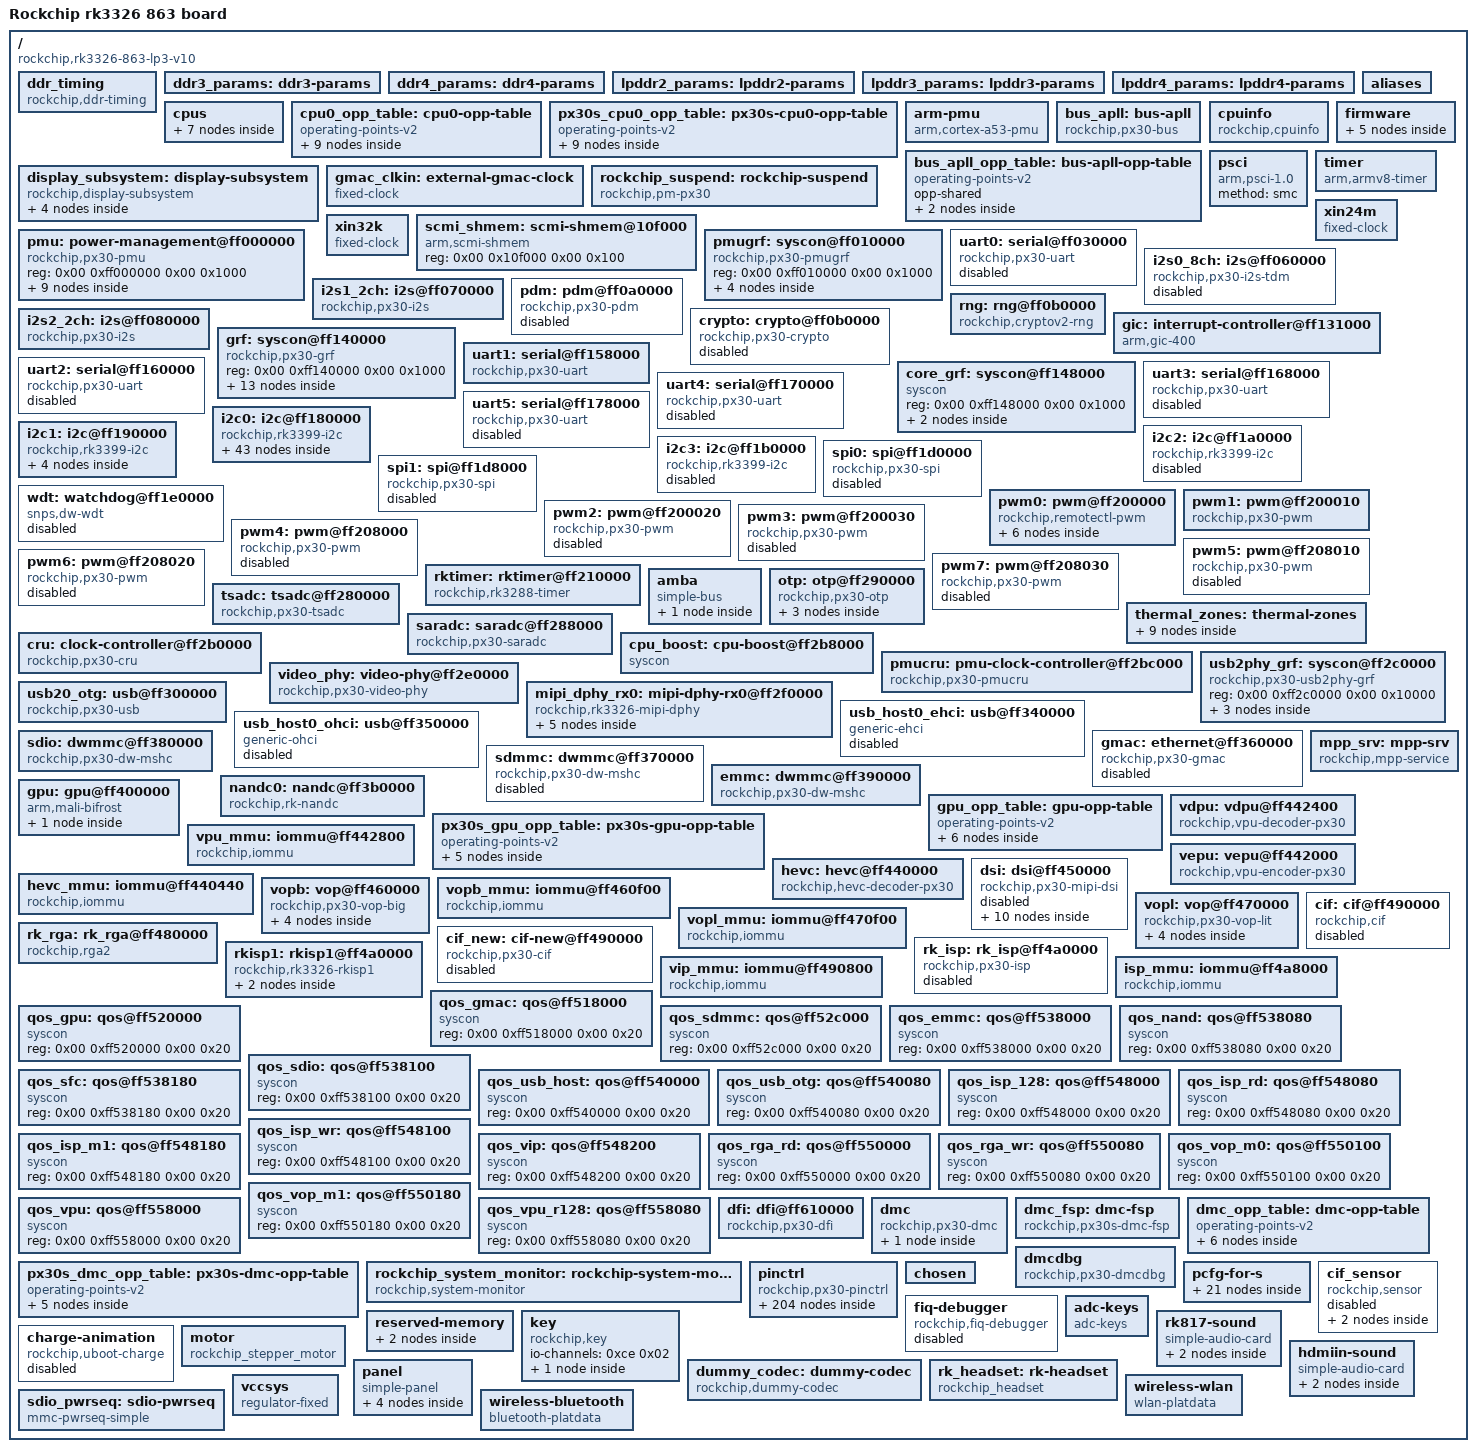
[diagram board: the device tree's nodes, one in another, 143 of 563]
/dts-v1/;

/ {
	compatible = "rockchip,rk3326-863-lp3-v10", "rockchip,rk3326";
	interrupt-parent = <0x01>;
	#address-cells = <0x02>;
	#size-cells = <0x02>;
	model = "Rockchip rk3326 863 board";

	ddr_timing: ddr_timing {
		compatible = "rockchip,ddr-timing";
		ddr2_speed_bin = <0x00>;
		ddr3_speed_bin = <0x15>;
		ddr4_speed_bin = <0x0c>;
		pd_idle = <0x0d>;
		sr_idle = <0x5d>;
		sr_mc_gate_idle = <0x00>;
		srpd_lite_idle = <0x00>;
		standby_idle = <0x00>;
		auto_pd_dis_freq = <0x42a>;
		auto_sr_dis_freq = <0x320>;
		ddr2_dll_dis_freq = <0x12c>;
		ddr3_dll_dis_freq = <0x12c>;
		ddr4_dll_dis_freq = <0x271>;
		phy_dll_dis_freq = <0x190>;
		ddr2_odt_dis_freq = <0x64>;
		phy_ddr2_odt_dis_freq = <0x64>;
		ddr2_drv = <0x01>;
		ddr2_odt = <0x96>;
		phy_ddr2_ca_drv = <0x15>;
		phy_ddr2_ck_drv = <0x12>;
		phy_ddr2_dq_drv = <0x15>;
		phy_ddr2_odt = <0x02>;
		ddr3_odt_dis_freq = <0x190>;
		phy_ddr3_odt_dis_freq = <0x190>;
		ddr3_drv = <0x28>;
		ddr3_odt = <0x78>;
		phy_ddr3_ca_drv = <0x15>;
		phy_ddr3_ck_drv = <0x12>;
		phy_ddr3_dq_drv = <0x15>;
		phy_ddr3_odt = <0x02>;
		phy_lpddr2_odt_dis_freq = <0x29a>;
		lpddr2_drv = <0x28>;
		phy_lpddr2_ca_drv = <0x16>;
		phy_lpddr2_ck_drv = <0x13>;
		phy_lpddr2_dq_drv = <0x16>;
		phy_lpddr2_odt = <0x00>;
		lpddr3_odt_dis_freq = <0x190>;
		phy_lpddr3_odt_dis_freq = <0x190>;
		lpddr3_drv = <0x28>;
		lpddr3_odt = <0xf0>;
		phy_lpddr3_ca_drv = <0x16>;
		phy_lpddr3_ck_drv = <0x13>;
		phy_lpddr3_dq_drv = <0x16>;
		phy_lpddr3_odt = <0x02>;
		lpddr4_odt_dis_freq = <0x320>;
		phy_lpddr4_odt_dis_freq = <0x320>;
		lpddr4_drv = <0x3c>;
		lpddr4_dq_odt = <0x28>;
		lpddr4_ca_odt = <0x28>;
		phy_lpddr4_ca_drv = <0x14>;
		phy_lpddr4_ck_cs_drv = <0x06>;
		phy_lpddr4_dq_drv = <0x06>;
		phy_lpddr4_odt = <0x10>;
		ddr4_odt_dis_freq = <0x29a>;
		phy_ddr4_odt_dis_freq = <0x29a>;
		ddr4_drv = <0x22>;
		ddr4_odt = <0xf0>;
		phy_ddr4_ca_drv = <0x16>;
		phy_ddr4_ck_drv = <0x13>;
		phy_ddr4_dq_drv = <0x16>;
		phy_ddr4_odt = <0x02>;
		ddr3a1_ddr4a9_de-skew = <0x06>;
		ddr3a0_ddr4a10_de-skew = <0x07>;
		ddr3a3_ddr4a6_de-skew = <0x07>;
		ddr3a2_ddr4a4_de-skew = <0x07>;
		ddr3a5_ddr4a8_de-skew = <0x07>;
		ddr3a4_ddr4a5_de-skew = <0x07>;
		ddr3a7_ddr4a11_de-skew = <0x07>;
		ddr3a6_ddr4a7_de-skew = <0x06>;
		ddr3a9_ddr4a0_de-skew = <0x07>;
		ddr3a8_ddr4a13_de-skew = <0x07>;
		ddr3a11_ddr4a3_de-skew = <0x07>;
		ddr3a10_ddr4cs0_de-skew = <0x07>;
		ddr3a13_ddr4a2_de-skew = <0x07>;
		ddr3a12_ddr4ba1_de-skew = <0x07>;
		ddr3a15_ddr4odt0_de-skew = <0x07>;
		ddr3a14_ddr4a1_de-skew = <0x07>;
		ddr3ba1_ddr4a15_de-skew = <0x07>;
		ddr3ba0_ddr4bg0_de-skew = <0x07>;
		ddr3ras_ddr4cke_de-skew = <0x07>;
		ddr3ba2_ddr4ba0_de-skew = <0x07>;
		ddr3we_ddr4bg1_de-skew = <0x07>;
		ddr3cas_ddr4a12_de-skew = <0x07>;
		ddr3ckn_ddr4ckn_de-skew = <0x07>;
		ddr3ckp_ddr4ckp_de-skew = <0x07>;
		ddr3cke_ddr4a16_de-skew = <0x07>;
		ddr3odt0_ddr4a14_de-skew = <0x07>;
		ddr3cs0_ddr4act_de-skew = <0x06>;
		ddr3reset_ddr4reset_de-skew = <0x07>;
		ddr3cs1_ddr4cs1_de-skew = <0x06>;
		ddr3odt1_ddr4odt1_de-skew = <0x07>;
		cs0_dm0_rx_de-skew = <0x07>;
		cs0_dm0_tx_de-skew = <0x07>;
		cs0_dq0_rx_de-skew = <0x08>;
		cs0_dq0_tx_de-skew = <0x08>;
		cs0_dq1_rx_de-skew = <0x09>;
		cs0_dq1_tx_de-skew = <0x08>;
		cs0_dq2_rx_de-skew = <0x08>;
		cs0_dq2_tx_de-skew = <0x08>;
		cs0_dq3_rx_de-skew = <0x08>;
		cs0_dq3_tx_de-skew = <0x08>;
		cs0_dq4_rx_de-skew = <0x09>;
		cs0_dq4_tx_de-skew = <0x08>;
		cs0_dq5_rx_de-skew = <0x09>;
		cs0_dq5_tx_de-skew = <0x08>;
		cs0_dq6_rx_de-skew = <0x09>;
		cs0_dq6_tx_de-skew = <0x08>;
		cs0_dq7_rx_de-skew = <0x08>;
		cs0_dq7_tx_de-skew = <0x08>;
		cs0_dqs0_rx_de-skew = <0x06>;
		cs0_dqs0p_tx_de-skew = <0x09>;
		cs0_dqs0n_tx_de-skew = <0x09>;
		cs0_dm1_rx_de-skew = <0x07>;
		cs0_dm1_tx_de-skew = <0x06>;
		cs0_dq8_rx_de-skew = <0x08>;
		cs0_dq8_tx_de-skew = <0x07>;
		cs0_dq9_rx_de-skew = <0x09>;
		cs0_dq9_tx_de-skew = <0x07>;
		cs0_dq10_rx_de-skew = <0x08>;
		cs0_dq10_tx_de-skew = <0x08>;
		cs0_dq11_rx_de-skew = <0x08>;
		cs0_dq11_tx_de-skew = <0x07>;
		cs0_dq12_rx_de-skew = <0x08>;
		cs0_dq12_tx_de-skew = <0x08>;
		cs0_dq13_rx_de-skew = <0x09>;
		cs0_dq13_tx_de-skew = <0x07>;
		cs0_dq14_rx_de-skew = <0x09>;
		cs0_dq14_tx_de-skew = <0x08>;
		cs0_dq15_rx_de-skew = <0x09>;
		cs0_dq15_tx_de-skew = <0x07>;
		cs0_dqs1_rx_de-skew = <0x07>;
		cs0_dqs1p_tx_de-skew = <0x09>;
		cs0_dqs1n_tx_de-skew = <0x09>;
		cs0_dm2_rx_de-skew = <0x07>;
		cs0_dm2_tx_de-skew = <0x07>;
		cs0_dq16_rx_de-skew = <0x09>;
		cs0_dq16_tx_de-skew = <0x09>;
		cs0_dq17_rx_de-skew = <0x07>;
		cs0_dq17_tx_de-skew = <0x09>;
		cs0_dq18_rx_de-skew = <0x07>;
		cs0_dq18_tx_de-skew = <0x08>;
		cs0_dq19_rx_de-skew = <0x07>;
		cs0_dq19_tx_de-skew = <0x09>;
		cs0_dq20_rx_de-skew = <0x09>;
		cs0_dq20_tx_de-skew = <0x09>;
		cs0_dq21_rx_de-skew = <0x09>;
		cs0_dq21_tx_de-skew = <0x09>;
		cs0_dq22_rx_de-skew = <0x08>;
		cs0_dq22_tx_de-skew = <0x09>;
		cs0_dq23_rx_de-skew = <0x08>;
		cs0_dq23_tx_de-skew = <0x09>;
		cs0_dqs2_rx_de-skew = <0x06>;
		cs0_dqs2p_tx_de-skew = <0x09>;
		cs0_dqs2n_tx_de-skew = <0x09>;
		cs0_dm3_rx_de-skew = <0x07>;
		cs0_dm3_tx_de-skew = <0x07>;
		cs0_dq24_rx_de-skew = <0x08>;
		cs0_dq24_tx_de-skew = <0x08>;
		cs0_dq25_rx_de-skew = <0x09>;
		cs0_dq25_tx_de-skew = <0x09>;
		cs0_dq26_rx_de-skew = <0x09>;
		cs0_dq26_tx_de-skew = <0x08>;
		cs0_dq27_rx_de-skew = <0x09>;
		cs0_dq27_tx_de-skew = <0x08>;
		cs0_dq28_rx_de-skew = <0x09>;
		cs0_dq28_tx_de-skew = <0x09>;
		cs0_dq29_rx_de-skew = <0x09>;
		cs0_dq29_tx_de-skew = <0x09>;
		cs0_dq30_rx_de-skew = <0x08>;
		cs0_dq30_tx_de-skew = <0x08>;
		cs0_dq31_rx_de-skew = <0x08>;
		cs0_dq31_tx_de-skew = <0x08>;
		cs0_dqs3_rx_de-skew = <0x07>;
		cs0_dqs3p_tx_de-skew = <0x09>;
		cs0_dqs3n_tx_de-skew = <0x09>;
		cs1_dm0_rx_de-skew = <0x07>;
		cs1_dm0_tx_de-skew = <0x07>;
		cs1_dq0_rx_de-skew = <0x08>;
		cs1_dq0_tx_de-skew = <0x08>;
		cs1_dq1_rx_de-skew = <0x09>;
		cs1_dq1_tx_de-skew = <0x08>;
		cs1_dq2_rx_de-skew = <0x08>;
		cs1_dq2_tx_de-skew = <0x08>;
		cs1_dq3_rx_de-skew = <0x08>;
		cs1_dq3_tx_de-skew = <0x08>;
		cs1_dq4_rx_de-skew = <0x08>;
		cs1_dq4_tx_de-skew = <0x08>;
		cs1_dq5_rx_de-skew = <0x09>;
		cs1_dq5_tx_de-skew = <0x08>;
		cs1_dq6_rx_de-skew = <0x09>;
		cs1_dq6_tx_de-skew = <0x08>;
		cs1_dq7_rx_de-skew = <0x08>;
		cs1_dq7_tx_de-skew = <0x08>;
		cs1_dqs0_rx_de-skew = <0x06>;
		cs1_dqs0p_tx_de-skew = <0x09>;
		cs1_dqs0n_tx_de-skew = <0x09>;
		cs1_dm1_rx_de-skew = <0x07>;
		cs1_dm1_tx_de-skew = <0x07>;
		cs1_dq8_rx_de-skew = <0x08>;
		cs1_dq8_tx_de-skew = <0x08>;
		cs1_dq9_rx_de-skew = <0x08>;
		cs1_dq9_tx_de-skew = <0x07>;
		cs1_dq10_rx_de-skew = <0x07>;
		cs1_dq10_tx_de-skew = <0x08>;
		cs1_dq11_rx_de-skew = <0x08>;
		cs1_dq11_tx_de-skew = <0x08>;
		cs1_dq12_rx_de-skew = <0x08>;
		cs1_dq12_tx_de-skew = <0x07>;
		cs1_dq13_rx_de-skew = <0x08>;
		cs1_dq13_tx_de-skew = <0x08>;
		cs1_dq14_rx_de-skew = <0x08>;
		cs1_dq14_tx_de-skew = <0x08>;
		cs1_dq15_rx_de-skew = <0x08>;
		cs1_dq15_tx_de-skew = <0x07>;
		cs1_dqs1_rx_de-skew = <0x07>;
		cs1_dqs1p_tx_de-skew = <0x09>;
		cs1_dqs1n_tx_de-skew = <0x09>;
		cs1_dm2_rx_de-skew = <0x07>;
		cs1_dm2_tx_de-skew = <0x08>;
		cs1_dq16_rx_de-skew = <0x08>;
		cs1_dq16_tx_de-skew = <0x09>;
		cs1_dq17_rx_de-skew = <0x08>;
		cs1_dq17_tx_de-skew = <0x09>;
		cs1_dq18_rx_de-skew = <0x07>;
		cs1_dq18_tx_de-skew = <0x08>;
		cs1_dq19_rx_de-skew = <0x08>;
		cs1_dq19_tx_de-skew = <0x09>;
		cs1_dq20_rx_de-skew = <0x09>;
		cs1_dq20_tx_de-skew = <0x09>;
		cs1_dq21_rx_de-skew = <0x09>;
		cs1_dq21_tx_de-skew = <0x09>;
		cs1_dq22_rx_de-skew = <0x08>;
		cs1_dq22_tx_de-skew = <0x09>;
		cs1_dq23_rx_de-skew = <0x08>;
		cs1_dq23_tx_de-skew = <0x09>;
		cs1_dqs2_rx_de-skew = <0x06>;
		cs1_dqs2p_tx_de-skew = <0x09>;
		cs1_dqs2n_tx_de-skew = <0x09>;
		cs1_dm3_rx_de-skew = <0x07>;
		cs1_dm3_tx_de-skew = <0x07>;
		cs1_dq24_rx_de-skew = <0x08>;
		cs1_dq24_tx_de-skew = <0x09>;
		cs1_dq25_rx_de-skew = <0x09>;
		cs1_dq25_tx_de-skew = <0x09>;
		cs1_dq26_rx_de-skew = <0x09>;
		cs1_dq26_tx_de-skew = <0x08>;
		cs1_dq27_rx_de-skew = <0x08>;
		cs1_dq27_tx_de-skew = <0x08>;
		cs1_dq28_rx_de-skew = <0x09>;
		cs1_dq28_tx_de-skew = <0x09>;
		cs1_dq29_rx_de-skew = <0x09>;
		cs1_dq29_tx_de-skew = <0x09>;
		cs1_dq30_rx_de-skew = <0x09>;
		cs1_dq30_tx_de-skew = <0x08>;
		cs1_dq31_rx_de-skew = <0x08>;
		cs1_dq31_tx_de-skew = <0x08>;
		cs1_dqs3_rx_de-skew = <0x07>;
		cs1_dqs3p_tx_de-skew = <0x09>;
		cs1_dqs3n_tx_de-skew = <0x09>;
		phandle = <0xbb>;
	};

	ddr3_params: ddr3-params {
		version = <0x101>;
		expanded_version = <0x00>;
		reserved = <0x00>;
		freq_0 = <0x312>;
		freq_1 = <0x148>;
		freq_2 = <0x29a>;
		freq_3 = <0x29a>;
		freq_4 = <0x00>;
		freq_5 = <0x00>;
		pd_idle = <0x0d>;
		sr_idle = <0x5d>;
		sr_mc_gate_idle = <0x00>;
		srpd_lite_idle = <0x00>;
		standby_idle = <0x00>;
		pd_dis_freq = <0x42a>;
		sr_dis_freq = <0x320>;
		dram_dll_dis_freq = <0x12c>;
		phy_dll_dis_freq = <0x00>;
		phy_dq_drv_odten = <0x21>;
		phy_ca_drv_odten = <0x21>;
		phy_clk_drv_odten = <0x21>;
		dram_dq_drv_odten = <0x22>;
		phy_dq_drv_odtoff = <0x21>;
		phy_ca_drv_odtoff = <0x21>;
		phy_clk_drv_odtoff = <0x21>;
		dram_dq_drv_odtoff = <0x22>;
		dram_odt = <0x78>;
		phy_odt = <0x85>;
		phy_odt_puup_en = <0x01>;
		phy_odt_pudn_en = <0x01>;
		dram_dq_odt_en_freq = <0x14d>;
		phy_odt_en_freq = <0x14d>;
		phy_dq_sr_odten = <0x0f>;
		phy_ca_sr_odten = <0x03>;
		phy_clk_sr_odten = <0x03>;
		phy_dq_sr_odtoff = <0x0f>;
		phy_ca_sr_odtoff = <0x03>;
		phy_clk_sr_odtoff = <0x03>;
		ssmod_downspread = <0x00>;
		ssmod_div = <0x00>;
		ssmod_spread = <0x00>;
		mode_2t = <0x00>;
		speed_bin = <0x15>;
		dram_ext_temp = <0x00>;
		byte_map = <0xb1>;
		dq_map_cs0_dq_l = <0x00>;
		dq_map_cs0_dq_h = <0x00>;
		dq_map_cs1_dq_l = <0x00>;
		dq_map_cs1_dq_h = <0x00>;
		phandle = <0xbc>;
	};

	ddr4_params: ddr4-params {
		version = <0x101>;
		expanded_version = <0x00>;
		reserved = <0x00>;
		freq_0 = <0x39c>;
		freq_1 = <0x148>;
		freq_2 = <0x29a>;
		freq_3 = <0x312>;
		freq_4 = <0x00>;
		freq_5 = <0x00>;
		pd_idle = <0x0d>;
		sr_idle = <0x5d>;
		sr_mc_gate_idle = <0x00>;
		srpd_lite_idle = <0x00>;
		standby_idle = <0x00>;
		pd_dis_freq = <0x42a>;
		sr_dis_freq = <0x320>;
		dram_dll_dis_freq = <0x1f4>;
		phy_dll_dis_freq = <0x00>;
		phy_dq_drv_odten = <0x21>;
		phy_ca_drv_odten = <0x21>;
		phy_clk_drv_odten = <0x21>;
		dram_dq_drv_odten = <0x22>;
		phy_dq_drv_odtoff = <0x21>;
		phy_ca_drv_odtoff = <0x21>;
		phy_clk_drv_odtoff = <0x21>;
		dram_dq_drv_odtoff = <0x22>;
		dram_odt = <0x78>;
		phy_odt = <0x79>;
		phy_odt_puup_en = <0x01>;
		phy_odt_pudn_en = <0x01>;
		dram_dq_odt_en_freq = <0x1f4>;
		phy_odt_en_freq = <0x1f4>;
		phy_dq_sr_odten = <0x0e>;
		phy_ca_sr_odten = <0x01>;
		phy_clk_sr_odten = <0x01>;
		phy_dq_sr_odtoff = <0x0e>;
		phy_ca_sr_odtoff = <0x01>;
		phy_clk_sr_odtoff = <0x01>;
		ssmod_downspread = <0x00>;
		ssmod_div = <0x00>;
		ssmod_spread = <0x00>;
		mode_2t = <0x00>;
		speed_bin = <0x0c>;
		dram_ext_temp = <0x00>;
		byte_map = <0xb1>;
		dq_map_cs0_dq_l = <0x139b6273>;
		dq_map_cs0_dq_h = <0x272d6f42>;
		dq_map_cs1_dq_l = <0x46ce3726>;
		dq_map_cs1_dq_h = <0x72783a17>;
		phandle = <0xbd>;
	};

	lpddr2_params: lpddr2-params {
		version = <0x101>;
		expanded_version = <0x00>;
		reserved = <0x00>;
		freq_0 = <0x210>;
		freq_1 = <0x148>;
		freq_2 = <0x1c2>;
		freq_3 = <0x210>;
		freq_4 = <0x00>;
		freq_5 = <0x00>;
		pd_idle = <0x0d>;
		sr_idle = <0x5d>;
		sr_mc_gate_idle = <0x00>;
		srpd_lite_idle = <0x00>;
		standby_idle = <0x00>;
		pd_dis_freq = <0x42a>;
		sr_dis_freq = <0x320>;
		dram_dll_dis_freq = <0x00>;
		phy_dll_dis_freq = <0x00>;
		phy_dq_drv_odten = <0x21>;
		phy_ca_drv_odten = <0x21>;
		phy_clk_drv_odten = <0x21>;
		dram_dq_drv_odten = <0x22>;
		phy_dq_drv_odtoff = <0x21>;
		phy_ca_drv_odtoff = <0x21>;
		phy_clk_drv_odtoff = <0x21>;
		dram_dq_drv_odtoff = <0x22>;
		dram_odt = <0x00>;
		phy_odt = <0x00>;
		phy_odt_puup_en = <0x00>;
		phy_odt_pudn_en = <0x00>;
		dram_dq_odt_en_freq = <0x271>;
		phy_odt_en_freq = <0x271>;
		phy_dq_sr_odten = <0x0e>;
		phy_ca_sr_odten = <0x01>;
		phy_clk_sr_odten = <0x01>;
		phy_dq_sr_odtoff = <0x0e>;
		phy_ca_sr_odtoff = <0x01>;
		phy_clk_sr_odtoff = <0x01>;
		ssmod_downspread = <0x00>;
		ssmod_div = <0x00>;
		ssmod_spread = <0x00>;
		mode_2t = <0x00>;
		speed_bin = <0x00>;
		dram_ext_temp = <0x00>;
		byte_map = <0xe4>;
		dq_map_cs0_dq_l = <0x00>;
		dq_map_cs0_dq_h = <0x00>;
		dq_map_cs1_dq_l = <0x00>;
		dq_map_cs1_dq_h = <0x00>;
		phandle = <0xbe>;
	};

	lpddr3_params: lpddr3-params {
		version = <0x101>;
		expanded_version = <0x00>;
		reserved = <0x00>;
		freq_0 = <0x29a>;
		freq_1 = <0x29a>;
		freq_2 = <0x29a>;
		freq_3 = <0x312>;
		freq_4 = <0x00>;
		freq_5 = <0x00>;
		pd_idle = <0x0d>;
		sr_idle = <0x5d>;
		sr_mc_gate_idle = <0x00>;
		srpd_lite_idle = <0x00>;
		standby_idle = <0x00>;
		pd_dis_freq = <0x42a>;
		sr_dis_freq = <0x320>;
		dram_dll_dis_freq = <0x00>;
		phy_dll_dis_freq = <0x00>;
		phy_dq_drv_odten = <0x21>;
		phy_ca_drv_odten = <0x21>;
		phy_clk_drv_odten = <0x21>;
		dram_dq_drv_odten = <0x22>;
		phy_dq_drv_odtoff = <0x21>;
		phy_ca_drv_odtoff = <0x21>;
		phy_clk_drv_odtoff = <0x21>;
		dram_dq_drv_odtoff = <0x22>;
		dram_odt = <0xf0>;
		phy_odt = <0x79>;
		phy_odt_puup_en = <0x01>;
		phy_odt_pudn_en = <0x01>;
		dram_dq_odt_en_freq = <0x14d>;
		phy_odt_en_freq = <0x14d>;
		phy_dq_sr_odten = <0x00>;
		phy_ca_sr_odten = <0x00>;
		phy_clk_sr_odten = <0x00>;
		phy_dq_sr_odtoff = <0x00>;
		phy_ca_sr_odtoff = <0x00>;
		phy_clk_sr_odtoff = <0x00>;
		ssmod_downspread = <0x00>;
		ssmod_div = <0x00>;
		ssmod_spread = <0x00>;
		mode_2t = <0x00>;
		speed_bin = <0x00>;
		dram_ext_temp = <0x00>;
		byte_map = <0xe4>;
		dq_map_cs0_dq_l = <0x00>;
		dq_map_cs0_dq_h = <0x00>;
		dq_map_cs1_dq_l = <0x00>;
		dq_map_cs1_dq_h = <0x00>;
		phandle = <0xbf>;
	};

	lpddr4_params: lpddr4-params {
		version = <0x101>;
		expanded_version = <0x00>;
		reserved = <0x00>;
		freq_0 = <0x39c>;
		freq_1 = <0x148>;
		freq_2 = <0x29a>;
		freq_3 = <0x312>;
		freq_4 = <0x00>;
		freq_5 = <0x00>;
		pd_idle = <0x0d>;
		sr_idle = <0x5d>;
		sr_mc_gate_idle = <0x00>;
		srpd_lite_idle = <0x00>;
		standby_idle = <0x00>;
		pd_dis_freq = <0x42a>;
		sr_dis_freq = <0x320>;
		dram_dll_dis_freq = <0x00>;
		phy_dll_dis_freq = <0x00>;
		phy_dq_drv_odten = <0x23>;
		phy_ca_drv_odten = <0x26>;
		phy_clk_drv_odten = <0x2f>;
		dram_dq_drv_odten = <0x28>;
		phy_dq_drv_odtoff = <0x23>;
		phy_ca_drv_odtoff = <0x26>;
		phy_clk_drv_odtoff = <0x2f>;
		dram_dq_drv_odtoff = <0x28>;
		dram_odt = <0x3c>;
		phy_odt = <0x50>;
		phy_odt_puup_en = <0x00>;
		phy_odt_pudn_en = <0x00>;
		dram_dq_odt_en_freq = <0x320>;
		phy_odt_en_freq = <0x320>;
		phy_dq_sr_odten = <0x0f>;
		phy_ca_sr_odten = <0x01>;
		phy_clk_sr_odten = <0x01>;
		phy_dq_sr_odtoff = <0x0f>;
		phy_ca_sr_odtoff = <0x01>;
		phy_clk_sr_odtoff = <0x01>;
		ssmod_downspread = <0x00>;
		ssmod_div = <0x00>;
		ssmod_spread = <0x00>;
		mode_2t = <0x00>;
		speed_bin = <0x00>;
		dram_ext_temp = <0x00>;
		byte_map = <0xe4>;
		dq_map_cs0_dq_l = <0x00>;
		dq_map_cs0_dq_h = <0x00>;
		dq_map_cs1_dq_l = <0x00>;
		dq_map_cs1_dq_h = <0x00>;
		lp4_ca_odt = <0x78>;
		lp4_drv_pu_cal_odten = <0x00>;
		lp4_drv_pu_cal_odtoff = <0x00>;
		phy_lp4_drv_pulldown_en_odten = <0x00>;
		phy_lp4_drv_pulldown_en_odtoff = <0x00>;
		lp4_ca_odt_en_freq = <0x320>;
		phy_lp4_cs_drv_odten = <0x00>;
		phy_lp4_cs_drv_odtoff = <0x00>;
		lp4_odte_ck_en = <0x01>;
		lp4_odte_cs_en = <0x01>;
		lp4_odtd_ca_en = <0x00>;
		phy_lp4_dq_vref_odten = <0xc8>;
		lp4_dq_vref_odten = <0x13c>;
		lp4_ca_vref_odten = <0x17c>;
		phy_lp4_dq_vref_odtoff = <0x12c>;
		lp4_dq_vref_odtoff = <0x1a4>;
		lp4_ca_vref_odtoff = <0x1a4>;
		phandle = <0xc0>;
	};

	aliases {
		ethernet0 = "/ethernet@ff360000";
		i2c0 = "/i2c@ff180000";
		i2c1 = "/i2c@ff190000";
		i2c2 = "/i2c@ff1a0000";
		i2c3 = "/i2c@ff1b0000";
		mmc0 = "/dwmmc@ff370000";
		mmc1 = "/dwmmc@ff380000";
		mmc2 = "/dwmmc@ff390000";
		serial0 = "/serial@ff030000";
		serial1 = "/serial@ff158000";
		serial2 = "/serial@ff160000";
		serial3 = "/serial@ff168000";
		serial4 = "/serial@ff170000";
		serial5 = "/serial@ff178000";
		spi0 = "/spi@ff1d0000";
		spi1 = "/spi@ff1d8000";
	};

	cpus {
		#address-cells = <0x02>;
		#size-cells = <0x00>;

		cpu0: cpu@0 {
			device_type = "cpu";
			compatible = "arm,cortex-a35", "arm,armv8";
			reg = <0x00 0x00>;
			enable-method = "psci";
			clocks = <0x02 0x07>;
			#cooling-cells = <0x02>;
			dynamic-power-coefficient = <0x5a>;
			operating-points-v2 = <0x03>;
			cpu-idle-states = <0x04 0x05>;
			cpu-supply = <0x06>;
			phandle = <0x09>;
		};

		cpu1: cpu@1 {
			device_type = "cpu";
			compatible = "arm,cortex-a35", "arm,armv8";
			reg = <0x00 0x01>;
			enable-method = "psci";
			operating-points-v2 = <0x03>;
			cpu-idle-states = <0x04 0x05>;
			phandle = <0x0a>;
		};

		cpu2: cpu@2 {
			device_type = "cpu";
			compatible = "arm,cortex-a35", "arm,armv8";
			reg = <0x00 0x02>;
			enable-method = "psci";
			operating-points-v2 = <0x03>;
			cpu-idle-states = <0x04 0x05>;
			phandle = <0x0b>;
		};

		cpu3: cpu@3 {
			device_type = "cpu";
			compatible = "arm,cortex-a35", "arm,armv8";
			reg = <0x00 0x03>;
			enable-method = "psci";
			operating-points-v2 = <0x03>;
			cpu-idle-states = <0x04 0x05>;
			phandle = <0x0c>;
		};

		idle-states {
			entry-method = "psci";

			CPU_SLEEP: cpu-sleep {
				compatible = "arm,idle-state";
				local-timer-stop;
				arm,psci-suspend-param = <0x10000>;
				entry-latency-us = <0x78>;
				exit-latency-us = <0xfa>;
				min-residency-us = <0x384>;
				phandle = <0x04>;
			};

			CLUSTER_SLEEP: cluster-sleep {
				compatible = "arm,idle-state";
				local-timer-stop;
				arm,psci-suspend-param = <0x1010000>;
				entry-latency-us = <0x190>;
				exit-latency-us = <0x1f4>;
				min-residency-us = <0x7d0>;
				phandle = <0x05>;
			};
		};
	};

	cpu0_opp_table: cpu0-opp-table {
		compatible = "operating-points-v2";
		opp-shared;
		rockchip,temp-hysteresis = <0x1388>;
		rockchip,low-temp = <0x00>;
		rockchip,low-temp-min-volt = <0xf4240>;
		rockchip,low-temp-adjust-volt = <0x00 0x5e8 0xc350>;
		clocks = <0x02 0x01>;
		rockchip,avs-scale = <0x04>;
		rockchip,max-volt = <0x149970>;
		rockchip,evb-irdrop = <0x61a8>;
		nvmem-cells = <0x07 0x08>;
		nvmem-cell-names = "cpu_leakage", "performance";
		rockchip,bin-scaling-sel = <0x00 0x0d 0x01 0x0f>;
		rockchip,pvtm-voltage-sel = <0x00 0xc350 0x00 0xc351 0xd2f0 0x01 0xd2f1 0xea60 0x02 0xea61 0x1869f 0x03>;
		rockchip,pvtm-freq = <0x639c0>;
		rockchip,pvtm-volt = <0xf4240>;
		rockchip,pvtm-ch = <0x00 0x00>;
		rockchip,pvtm-sample-time = <0x3e8>;
		rockchip,pvtm-number = <0x0a>;
		rockchip,pvtm-error = <0x3e8>;
		rockchip,pvtm-ref-temp = <0x28>;
		rockchip,pvtm-temp-prop = <0xffffffc8 0xffffffc8>;
		rockchip,thermal-zone = "soc-thermal";
		rockchip,avs = <0x01>;
		rockchip,board-irdrop = <0x00 0x32f 0x927c 0x330 0x45f 0xc350 0x4b0 0x5e8 0x124f8>;
		phandle = <0x03>;

		opp-408000000 {
			opp-hz = <0x00 0x18519600>;
			opp-microvolt = <0xe7ef0 0xe7ef0 0x149970>;
			opp-microvolt-L0 = <0xe7ef0 0xe7ef0 0x149970>;
			opp-microvolt-L1 = <0xe7ef0 0xe7ef0 0x149970>;
			opp-microvolt-L2 = <0xe7ef0 0xe7ef0 0x149970>;
			opp-microvolt-L3 = <0xe7ef0 0xe7ef0 0x149970>;
			clock-latency-ns = <0x9c40>;
			opp-suspend;
		};

		opp-600000000 {
			opp-hz = <0x00 0x23c34600>;
			opp-microvolt = <0xe7ef0 0xe7ef0 0x149970>;
			opp-microvolt-L0 = <0xe7ef0 0xe7ef0 0x149970>;
			opp-microvolt-L1 = <0xe7ef0 0xe7ef0 0x149970>;
			opp-microvolt-L2 = <0xe7ef0 0xe7ef0 0x149970>;
			opp-microvolt-L3 = <0xe7ef0 0xe7ef0 0x149970>;
			clock-latency-ns = <0x9c40>;
		};

		opp-816000000 {
			opp-hz = <0x00 0x30a32c00>;
			opp-microvolt = <0x100590 0x100590 0x149970>;
			opp-microvolt-L0 = <0x100590 0x100590 0x149970>;
			opp-microvolt-L1 = <0xf4240 0xf4240 0x149970>;
			opp-microvolt-L2 = <0xf4240 0xf4240 0x149970>;
			opp-microvolt-L3 = <0xe7ef0 0xe7ef0 0x149970>;
			clock-latency-ns = <0x9c40>;
		};

		opp-1008000000 {
			opp-hz = <0x00 0x3c14dc00>;
			opp-microvolt = <0x11edd8 0x11edd8 0x149970>;
			opp-microvolt-L0 = <0x11edd8 0x11edd8 0x149970>;
			opp-microvolt-L1 = <0x112a88 0x112a88 0x149970>;
			opp-microvolt-L2 = <0x112a88 0x112a88 0x149970>;
			opp-microvolt-L3 = <0x100590 0x100590 0x149970>;
			clock-latency-ns = <0x9c40>;
		};

		opp-1200000000 {
			opp-hz = <0x00 0x47868c00>;
			opp-microvolt = <0x13d620 0x13d620 0x149970>;
			opp-microvolt-L0 = <0x13d620 0x13d620 0x149970>;
			opp-microvolt-L1 = <0x137478 0x137478 0x149970>;
			opp-microvolt-L2 = <0x1312d0 0x1312d0 0x149970>;
			opp-microvolt-L3 = <0x124f80 0x124f80 0x149970>;
			clock-latency-ns = <0x9c40>;
		};

		opp-1248000000 {
			opp-hz = <0x00 0x4a62f800>;
			opp-microvolt = <0x149970 0x149970 0x149970>;
			opp-microvolt-L0 = <0x149970 0x149970 0x149970>;
			opp-microvolt-L1 = <0x13d620 0x13d620 0x149970>;
			opp-microvolt-L2 = <0x137478 0x137478 0x149970>;
			opp-microvolt-L3 = <0x12b128 0x12b128 0x149970>;
			clock-latency-ns = <0x9c40>;
		};

		opp-1296000000 {
			opp-hz = <0x00 0x4d3f6400>;
			opp-microvolt = <0x149970 0x149970 0x149970>;
			opp-microvolt-L0 = <0x149970 0x149970 0x149970>;
			opp-microvolt-L1 = <0x149970 0x149970 0x149970>;
			opp-microvolt-L2 = <0x13d620 0x13d620 0x149970>;
			opp-microvolt-L3 = <0x1312d0 0x1312d0 0x149970>;
			clock-latency-ns = <0x9c40>;
		};

		opp-1416000000 {
			opp-hz = <0x00 0x54667200>;
			opp-microvolt = <0x149970 0x149970 0x149970>;
			opp-microvolt-L0 = <0x149970 0x149970 0x149970>;
			opp-microvolt-L1 = <0x149970 0x149970 0x149970>;
			opp-microvolt-L2 = <0x13d620 0x13d620 0x149970>;
			opp-microvolt-L3 = <0x1312d0 0x1312d0 0x149970>;
			clock-latency-ns = <0x9c40>;
		};

		opp-1512000000 {
			opp-hz = <0x00 0x5a1f4a00>;
			opp-microvolt = <0x149970 0x149970 0x149970>;
			opp-microvolt-L0 = <0x149970 0x149970 0x149970>;
			opp-microvolt-L1 = <0x149970 0x149970 0x149970>;
			opp-microvolt-L2 = <0x13d620 0x13d620 0x149970>;
			opp-microvolt-L3 = <0x1312d0 0x1312d0 0x149970>;
			clock-latency-ns = <0x9c40>;
		};
	};

	px30s_cpu0_opp_table: px30s-cpu0-opp-table {
		compatible = "operating-points-v2";
		opp-shared;
		nvmem-cells = <0x07>;
		nvmem-cell-names = "cpu_leakage";
		rockchip,pvtm-voltage-sel = <0x00 0x110da 0x00 0x110db 0x12048 0x01 0x12049 0x12fb6 0x02 0x12fb7 0x13f24 0x03 0x13f25 0x1869f 0x04>;
		rockchip,pvtm-freq = <0x639c0>;
		rockchip,pvtm-volt = <0xdbba0>;
		rockchip,pvtm-ch = <0x00 0x00>;
		rockchip,pvtm-sample-time = <0x3e8>;
		rockchip,pvtm-number = <0x0a>;
		rockchip,pvtm-error = <0x3e8>;
		rockchip,pvtm-ref-temp = <0x00>;
		rockchip,pvtm-temp-prop = <0x00 0x00>;
		rockchip,thermal-zone = "soc-thermal";
		phandle = <0xdf>;

		opp-408000000 {
			opp-hz = <0x00 0x18519600>;
			opp-microvolt = <0xcf850 0xcf850 0x118c30>;
			clock-latency-ns = <0x9c40>;
			opp-suspend;
		};

		opp-600000000 {
			opp-hz = <0x00 0x23c34600>;
			opp-microvolt = <0xcf850 0xcf850 0x118c30>;
			clock-latency-ns = <0x9c40>;
		};

		opp-816000000 {
			opp-hz = <0x00 0x30a32c00>;
			opp-microvolt = <0xcf850 0xcf850 0x118c30>;
			clock-latency-ns = <0x9c40>;
		};

		opp-1008000000 {
			opp-hz = <0x00 0x3c14dc00>;
			opp-microvolt = <0xe7ef0 0xe7ef0 0x118c30>;
			opp-microvolt-L0 = <0xe7ef0 0xe7ef0 0x118c30>;
			opp-microvolt-L1 = <0xe1d48 0xe1d48 0x118c30>;
			opp-microvolt-L2 = <0xdbba0 0xdbba0 0x118c30>;
			opp-microvolt-L3 = <0xd59f8 0xd59f8 0x118c30>;
			opp-microvolt-L4 = <0xcf850 0xcf850 0x118c30>;
			clock-latency-ns = <0x9c40>;
		};

		opp-1200000000 {
			opp-hz = <0x00 0x47868c00>;
			opp-microvolt = <0x100590 0x100590 0x118c30>;
			opp-microvolt-L0 = <0x100590 0x100590 0x118c30>;
			opp-microvolt-L1 = <0xfa3e8 0xfa3e8 0x118c30>;
			opp-microvolt-L2 = <0xf4240 0xf4240 0x118c30>;
			opp-microvolt-L3 = <0xee098 0xee098 0x118c30>;
			opp-microvolt-L4 = <0xe7ef0 0xe7ef0 0x118c30>;
			clock-latency-ns = <0x9c40>;
		};

		opp-1248000000 {
			opp-hz = <0x00 0x4a62f800>;
			opp-microvolt = <0x106738 0x106738 0x118c30>;
			opp-microvolt-L0 = <0x106738 0x106738 0x118c30>;
			opp-microvolt-L1 = <0x100590 0x100590 0x118c30>;
			opp-microvolt-L2 = <0xfa3e8 0xfa3e8 0x118c30>;
			opp-microvolt-L3 = <0xf4240 0xf4240 0x118c30>;
			opp-microvolt-L4 = <0xee098 0xee098 0x118c30>;
			clock-latency-ns = <0x9c40>;
		};

		opp-1296000000 {
			opp-hz = <0x00 0x4d3f6400>;
			opp-microvolt = <0x10c8e0 0x10c8e0 0x118c30>;
			opp-microvolt-L0 = <0x10c8e0 0x10c8e0 0x118c30>;
			opp-microvolt-L1 = <0x106738 0x106738 0x118c30>;
			opp-microvolt-L2 = <0x100590 0x100590 0x118c30>;
			opp-microvolt-L3 = <0xfa3e8 0xfa3e8 0x118c30>;
			opp-microvolt-L4 = <0xf4240 0xf4240 0x118c30>;
			clock-latency-ns = <0x9c40>;
		};

		opp-1416000000 {
			opp-hz = <0x00 0x54667200>;
			opp-microvolt = <0x118c30 0x118c30 0x118c30>;
			opp-microvolt-L0 = <0x118c30 0x118c30 0x118c30>;
			opp-microvolt-L1 = <0x112a88 0x112a88 0x118c30>;
			opp-microvolt-L2 = <0x10c8e0 0x10c8e0 0x118c30>;
			opp-microvolt-L3 = <0x106738 0x106738 0x118c30>;
			opp-microvolt-L4 = <0x100590 0x100590 0x118c30>;
			clock-latency-ns = <0x9c40>;
		};

		opp-1512000000 {
			opp-hz = <0x00 0x5a1f4a00>;
			opp-microvolt = <0x118c30 0x118c30 0x118c30>;
			opp-microvolt-L0 = <0x118c30 0x118c30 0x118c30>;
			opp-microvolt-L1 = <0x112a88 0x112a88 0x118c30>;
			opp-microvolt-L2 = <0x10c8e0 0x10c8e0 0x118c30>;
			opp-microvolt-L3 = <0x106738 0x106738 0x118c30>;
			opp-microvolt-L4 = <0x100590 0x100590 0x118c30>;
			clock-latency-ns = <0x9c40>;
		};
	};

	arm-pmu {
		compatible = "arm,cortex-a53-pmu";
		interrupts = <0x00 0x64 0x04 0x00 0x65 0x04 0x00 0x66 0x04 0x00 0x67 0x04>;
		interrupt-affinity = <0x09 0x0a 0x0b 0x0c>;
	};

	bus_apll: bus-apll {
		compatible = "rockchip,px30-bus";
		rockchip,busfreq-policy = "clkfreq";
		clocks = <0x02 0x01>;
		clock-names = "bus";
		operating-points-v2 = <0x0d>;
		status = "okay";
		bus-supply = <0x0e>;
		phandle = <0xe0>;
	};

	bus_apll_opp_table: bus-apll-opp-table {
		compatible = "operating-points-v2";
		opp-shared;
		phandle = <0x0d>;

		opp-1512000000 {
			opp-hz = <0x00 0x5a1f4a00>;
			opp-microvolt = <0xf4240>;
		};

		opp-1008000000 {
			opp-hz = <0x00 0x3c14dc00>;
			opp-microvolt = <0xe7ef0>;
		};
	};

	cpuinfo {
		compatible = "rockchip,cpuinfo";
		nvmem-cells = <0x0f>;
		nvmem-cell-names = "id";
	};

	display_subsystem: display-subsystem {
		compatible = "rockchip,display-subsystem";
		ports = <0x10 0x11>;
		status = "okay";
		logo-memory-region = <0x12>;
		phandle = <0xe1>;

		route {

			route_lvds: route-lvds {
				status = "okay";
				logo,uboot = "logo.bmp";
				logo,kernel = "logo_kernel.bmp";
				logo,mode = "center";
				charge_logo,mode = "center";
				connect = <0x13>;
				phandle = <0xe2>;
			};

			route_dsi: route-dsi {
				status = "disabled";
				logo,uboot = "logo.bmp";
				logo,kernel = "logo_kernel.bmp";
				logo,mode = "center";
				charge_logo,mode = "center";
				connect = <0x14>;
				phandle = <0xe3>;
			};

			route_rgb: route-rgb {
				status = "disabled";
				logo,uboot = "logo.bmp";
				logo,kernel = "logo_kernel.bmp";
				logo,mode = "center";
				charge_logo,mode = "center";
				connect = <0x15>;
				phandle = <0xe4>;
			};
		};
	};

	firmware {

		optee: optee {
			compatible = "linaro,optee-tz";
			method = "smc";
			phandle = <0xe5>;
		};

		scmi: scmi {
			compatible = "arm,scmi-smc";
			shmem = <0x16>;
			arm,smc-id = <0x82000010>;
			#address-cells = <0x01>;
			#size-cells = <0x00>;
			phandle = <0xe6>;

			scmi_clk: protocol@14 {
				reg = <0x14>;
				#clock-cells = <0x01>;
				phandle = <0xe7>;
			};
		};

		sdei: sdei {
			compatible = "arm,sdei-1.0";
			method = "smc";
			phandle = <0xe8>;
		};

		firmware_android: android {
			phandle = <0xe9>;
		};
	};

	gmac_clkin: external-gmac-clock {
		compatible = "fixed-clock";
		clock-frequency = <0x2faf080>;
		clock-output-names = "gmac_clkin";
		#clock-cells = <0x00>;
		phandle = <0xea>;
	};

	psci {
		compatible = "arm,psci-1.0";
		method = "smc";
	};

	rockchip_suspend: rockchip-suspend {
		compatible = "rockchip,pm-px30";
		status = "okay";
		rockchip,sleep-debug-en = <0x01>;
		rockchip,sleep-mode-config = <0x20702>;
		rockchip,wakeup-config = <0x85>;
		phandle = <0xeb>;
	};

	timer {
		compatible = "arm,armv8-timer";
		interrupts = <0x01 0x0d 0xf04 0x01 0x0e 0xf04 0x01 0x0b 0xf04 0x01 0x0a 0xf04>;
	};

	xin24m: xin24m {
		compatible = "fixed-clock";
		#clock-cells = <0x00>;
		clock-frequency = <0x16e3600>;
		clock-output-names = "xin24m";
		phandle = <0xec>;
	};

	xin32k: xin32k {
		compatible = "fixed-clock";
		#clock-cells = <0x00>;
		clock-frequency = <0x8000>;
		clock-output-names = "xin32k";
		phandle = <0xed>;
	};

	scmi_shmem: scmi-shmem@10f000 {
		compatible = "arm,scmi-shmem";
		reg = <0x00 0x10f000 0x00 0x100>;
		phandle = <0x16>;
	};

	pmu: power-management@ff000000 {
		compatible = "rockchip,px30-pmu", "syscon", "simple-mfd";
		reg = <0x00 0xff000000 0x00 0x1000>;
		phandle = <0xee>;

		power: power-controller {
			compatible = "rockchip,px30-power-controller";
			#power-domain-cells = <0x01>;
			#address-cells = <0x01>;
			#size-cells = <0x00>;
			phandle = <0x91>;

			pd_usb@5 {
				reg = <0x05>;
				clocks = <0x02 0x103 0x02 0x102 0x02 0x3c>;
				pm_qos = <0x17 0x18>;
			};

			pd_sdcard@7 {
				reg = <0x07>;
				clocks = <0x02 0xf7 0x02 0x3b>;
				pm_qos = <0x19>;
			};

			pd_gmac@9 {
				reg = <0x09>;
				clocks = <0x02 0xb2 0x02 0x143 0x02 0x40 0x02 0x3f>;
				pm_qos = <0x1a>;
			};

			pd_mmc_nand@10 {
				reg = <0x0a>;
				clocks = <0x02 0xfe 0x02 0x100 0x02 0xff 0x02 0x101 0x02 0x39 0x02 0x37 0x02 0x38 0x02 0x3a>;
				pm_qos = <0x1b 0x1c 0x1d 0x1e>;
			};

			pd_vpu@11 {
				reg = <0x0b>;
				clocks = <0x02 0xaf 0x02 0xf4 0x02 0x4b>;
				pm_qos = <0x1f 0x20>;
			};

			pd_vo@12 {
				reg = <0x0c>;
				clocks = <0x02 0xb7 0x02 0xb5 0x02 0xb6 0x02 0x96 0x02 0x97 0x02 0xfd 0x02 0xfb 0x02 0xfc 0x02 0x144 0x02 0x35 0x02 0x36>;
				pm_qos = <0x21 0x22 0x23 0x24>;
			};

			pd_vi@13 {
				reg = <0x0d>;
				clocks = <0x02 0xb3 0x02 0xb4 0x02 0xf9 0x02 0xfa 0x02 0x33>;
				pm_qos = <0x25 0x26 0x27 0x28 0x29>;
			};

			pd_gpu@14 {
				reg = <0x0e>;
				clocks = <0x02 0x49>;
				pm_qos = <0x2a>;
			};
		};
	};

	pmugrf: syscon@ff010000 {
		compatible = "rockchip,px30-pmugrf", "syscon", "simple-mfd";
		reg = <0x00 0xff010000 0x00 0x1000>;
		#address-cells = <0x01>;
		#size-cells = <0x01>;
		phandle = <0xb8>;

		pmu_io_domains: io-domains {
			compatible = "rockchip,px30-pmu-io-voltage-domain";
			status = "okay";
			pmuio1-supply = <0x2b>;
			pmuio2-supply = <0x2b>;
			phandle = <0xef>;
		};

		reboot_mode: reboot-mode {
			compatible = "syscon-reboot-mode";
			offset = <0x200>;
			mode-bootloader = <0x5242c301>;
			mode-charge = <0x5242c30b>;
			mode-fastboot = <0x5242c309>;
			mode-loader = <0x5242c301>;
			mode-normal = <0x5242c300>;
			mode-recovery = <0x5242c303>;
			mode-ums = <0x5242c30c>;
			phandle = <0xf0>;
		};

		pmu_pvtm: pmu-pvtm {
			compatible = "rockchip,px30-pmu-pvtm";
			#address-cells = <0x01>;
			#size-cells = <0x00>;
			status = "okay";
			phandle = <0xf1>;

			pvtm@1 {
				reg = <0x01>;
				clocks = <0x2c 0x07>;
				clock-names = "clk";
			};
		};
	};

	uart0: serial@ff030000 {
		compatible = "rockchip,px30-uart", "snps,dw-apb-uart";
		reg = <0x00 0xff030000 0x00 0x100>;
		interrupts = <0x00 0x0f 0x04>;
		clocks = <0x2c 0x06 0x2c 0x15>;
		clock-names = "baudclk", "apb_pclk";
		reg-shift = <0x02>;
		reg-io-width = <0x04>;
		dmas = <0x2d 0x00 0x2d 0x01>;
		pinctrl-names = "default";
		pinctrl-0 = <0x2e 0x2f 0x30>;
		status = "disabled";
		phandle = <0xf2>;
	};

	i2s0_8ch: i2s@ff060000 {
		compatible = "rockchip,px30-i2s-tdm";
		reg = <0x00 0xff060000 0x00 0x1000>;
		interrupts = <0x00 0x0c 0x04>;
		clocks = <0x02 0x10 0x02 0x12 0x02 0x106>;
		clock-names = "mclk_tx", "mclk_rx", "hclk";
		dmas = <0x2d 0x10 0x2d 0x11>;
		dma-names = "tx", "rx";
		resets = <0x02 0x84 0x02 0xbf>;
		reset-names = "tx-m", "rx-m";
		rockchip,cru = <0x02>;
		rockchip,grf = <0x31>;
		pinctrl-names = "default";
		pinctrl-0 = <0x32 0x33 0x34 0x35 0x36 0x37 0x38 0x39 0x3a 0x3b 0x3c 0x3d>;
		status = "disabled";
		phandle = <0xf3>;
	};

	i2s1_2ch: i2s@ff070000 {
		compatible = "rockchip,px30-i2s", "rockchip,rk3066-i2s";
		reg = <0x00 0xff070000 0x00 0x1000>;
		interrupts = <0x00 0x0d 0x04>;
		clocks = <0x02 0x14 0x02 0x107>;
		clock-names = "i2s_clk", "i2s_hclk";
		dmas = <0x2d 0x12 0x2d 0x13>;
		dma-names = "tx", "rx";
		resets = <0x02 0x86 0x02 0x85>;
		reset-names = "reset-m", "reset-h";
		pinctrl-names = "default";
		pinctrl-0 = <0x3e 0x3f 0x40 0x41>;
		status = "okay";
		#sound-dai-cells = <0x00>;
		phandle = <0xcf>;
	};

	i2s2_2ch: i2s@ff080000 {
		compatible = "rockchip,px30-i2s", "rockchip,rk3066-i2s";
		reg = <0x00 0xff080000 0x00 0x1000>;
		interrupts = <0x00 0x0e 0x04>;
		clocks = <0x02 0x16 0x02 0x108>;
		clock-names = "i2s_clk", "i2s_hclk";
		dmas = <0x2d 0x14 0x2d 0x15>;
		dma-names = "tx", "rx";
		resets = <0x02 0x88 0x02 0x87>;
		reset-names = "reset-m", "reset-h";
		pinctrl-names = "default";
		pinctrl-0 = <0x42 0x43 0x44 0x45>;
		status = "okay";
		#sound-dai-cells = <0x00>;
		phandle = <0xd2>;
	};

	pdm: pdm@ff0a0000 {
		compatible = "rockchip,px30-pdm";
		reg = <0x00 0xff0a0000 0x00 0x1000>;
		clocks = <0x02 0x0f 0x02 0x105>;
		clock-names = "pdm_clk", "pdm_hclk";
		dmas = <0x2d 0x18>;
		dma-names = "rx";
		resets = <0x02 0x82>;
		reset-names = "pdm-m";
		pinctrl-names = "default";
		pinctrl-0 = <0x46 0x47 0x48 0x49 0x4a 0x4b>;
		status = "disabled";
		phandle = <0xf4>;
	};

	crypto: crypto@ff0b0000 {
		compatible = "rockchip,px30-crypto";
		reg = <0x00 0xff0b0000 0x00 0x400 0x00 0xff0b0480 0x00 0x3b80>;
		interrupts = <0x00 0x52 0x04>;
		clocks = <0x02 0xac 0x02 0xf1 0x02 0x30 0x02 0x31>;
		clock-names = "aclk", "hclk", "sclk", "apb_pclk";
		resets = <0x02 0x74>;
		reset-names = "crypto-rst";
		status = "disabled";
		phandle = <0xf5>;
	};

	rng: rng@ff0b0000 {
		compatible = "rockchip,cryptov2-rng";
		reg = <0x00 0xff0b0400 0x00 0x80>;
		clocks = <0x02 0x30 0x02 0x31 0x02 0xac 0x02 0xf1>;
		clock-names = "clk_crypto", "clk_crypto_apk", "aclk_crypto", "hclk_crypto";
		assigned-clocks = <0x02 0x30 0x02 0x31 0x02 0xac 0x02 0xf1>;
		assigned-clock-rates = <0x8f0d180 0x8f0d180 0xbebc200 0xbebc200>;
		resets = <0x02 0x74>;
		reset-names = "reset";
		status = "okay";
		phandle = <0xf6>;
	};

	gic: interrupt-controller@ff131000 {
		compatible = "arm,gic-400";
		#interrupt-cells = <0x03>;
		#address-cells = <0x00>;
		interrupt-controller;
		reg = <0x00 0xff131000 0x00 0x1000 0x00 0xff132000 0x00 0x2000 0x00 0xff134000 0x00 0x2000 0x00 0xff136000 0x00 0x2000>;
		interrupts = <0x01 0x09 0xf04>;
		phandle = <0x01>;
	};

	grf: syscon@ff140000 {
		compatible = "rockchip,px30-grf", "syscon", "simple-mfd";
		reg = <0x00 0xff140000 0x00 0x1000>;
		#address-cells = <0x01>;
		#size-cells = <0x01>;
		phandle = <0x31>;

		io_domains: io-domains {
			compatible = "rockchip,px30-io-voltage-domain";
			status = "okay";
			vccio1-supply = <0x4c>;
			vccio2-supply = <0x4d>;
			vccio3-supply = <0x4e>;
			vccio4-supply = <0x4c>;
			vccio5-supply = <0x4c>;
			phandle = <0xf7>;
		};

		lvds: lvds {
			compatible = "rockchip,px30-lvds";
			phys = <0x4f>;
			phy-names = "phy";
			status = "okay";
			phandle = <0xf8>;

			ports {
				#address-cells = <0x01>;
				#size-cells = <0x00>;

				port@0 {
					reg = <0x00>;
					#address-cells = <0x01>;
					#size-cells = <0x00>;

					lvds_in_vopb: endpoint@0 {
						reg = <0x00>;
						remote-endpoint = <0x13>;
						status = "okay";
						phandle = <0xa9>;
					};

					lvds_in_vopl: endpoint@1 {
						reg = <0x01>;
						remote-endpoint = <0x50>;
						status = "disabled";
						phandle = <0xad>;
					};
				};

				port@1 {
					reg = <0x01>;

					lvds_out_panel: endpoint {
						remote-endpoint = <0x51>;
						phandle = <0xd8>;
					};
				};
			};
		};

		rgb: rgb {
			compatible = "rockchip,px30-rgb";
			pinctrl-names = "default", "sleep";
			pinctrl-0 = <0x52>;
			pinctrl-1 = <0x53>;
			status = "disabled";
			phys = <0x4f>;
			phy-names = "phy";
			phandle = <0xf9>;

			ports {
				#address-cells = <0x01>;
				#size-cells = <0x00>;

				port@0 {
					reg = <0x00>;
					#address-cells = <0x01>;
					#size-cells = <0x00>;

					rgb_in_vopb: endpoint@0 {
						reg = <0x00>;
						remote-endpoint = <0x15>;
						phandle = <0xab>;
					};

					rgb_in_vopl: endpoint@1 {
						reg = <0x01>;
						remote-endpoint = <0x54>;
						phandle = <0xaf>;
					};
				};
			};
		};
	};

	core_grf: syscon@ff148000 {
		compatible = "syscon", "simple-mfd";
		reg = <0x00 0xff148000 0x00 0x1000>;
		#address-cells = <0x01>;
		#size-cells = <0x01>;
		phandle = <0xfa>;

		pvtm: pvtm {
			compatible = "rockchip,px30-pvtm";
			#address-cells = <0x01>;
			#size-cells = <0x00>;
			status = "okay";
			phandle = <0xfb>;

			pvtm@0 {
				reg = <0x00>;
				clocks = <0x02 0x4a>;
				clock-names = "clk";
			};
		};
	};

	uart1: serial@ff158000 {
		compatible = "rockchip,px30-uart", "snps,dw-apb-uart";
		reg = <0x00 0xff158000 0x00 0x100>;
		interrupts = <0x00 0x10 0x04>;
		clocks = <0x02 0x18 0x02 0x149>;
		clock-names = "baudclk", "apb_pclk";
		reg-shift = <0x02>;
		reg-io-width = <0x04>;
		dmas = <0x2d 0x02 0x2d 0x03>;
		pinctrl-names = "default";
		pinctrl-0 = <0x55 0x56>;
		status = "okay";
		phandle = <0xfc>;
	};

	uart2: serial@ff160000 {
		compatible = "rockchip,px30-uart", "snps,dw-apb-uart";
		reg = <0x00 0xff160000 0x00 0x100>;
		interrupts = <0x00 0x11 0x04>;
		clocks = <0x02 0x19 0x02 0x14a>;
		clock-names = "baudclk", "apb_pclk";
		reg-shift = <0x02>;
		reg-io-width = <0x04>;
		dmas = <0x2d 0x04 0x2d 0x05>;
		pinctrl-names = "default";
		pinctrl-0 = <0x57>;
		status = "disabled";
		phandle = <0xfd>;
	};

	uart3: serial@ff168000 {
		compatible = "rockchip,px30-uart", "snps,dw-apb-uart";
		reg = <0x00 0xff168000 0x00 0x100>;
		interrupts = <0x00 0x12 0x04>;
		clocks = <0x02 0x1a 0x02 0x14b>;
		clock-names = "baudclk", "apb_pclk";
		reg-shift = <0x02>;
		reg-io-width = <0x04>;
		dmas = <0x2d 0x06 0x2d 0x07>;
		pinctrl-names = "default";
		pinctrl-0 = <0x58 0x59 0x5a>;
		status = "disabled";
		phandle = <0xfe>;
	};

	uart4: serial@ff170000 {
		compatible = "rockchip,px30-uart", "snps,dw-apb-uart";
		reg = <0x00 0xff170000 0x00 0x100>;
		interrupts = <0x00 0x13 0x04>;
		clocks = <0x02 0x1b 0x02 0x14c>;
		clock-names = "baudclk", "apb_pclk";
		reg-shift = <0x02>;
		reg-io-width = <0x04>;
		dmas = <0x2d 0x08 0x2d 0x09>;
		pinctrl-names = "default";
		pinctrl-0 = <0x5b 0x5c 0x5d>;
		status = "disabled";
		phandle = <0xff>;
	};

	uart5: serial@ff178000 {
		compatible = "rockchip,px30-uart", "snps,dw-apb-uart";
		reg = <0x00 0xff178000 0x00 0x100>;
		interrupts = <0x00 0x14 0x04>;
		clocks = <0x02 0x1c 0x02 0x14d>;
		clock-names = "baudclk", "apb_pclk";
		reg-shift = <0x02>;
		reg-io-width = <0x04>;
		dmas = <0x2d 0x0a 0x2d 0x0b>;
		pinctrl-names = "default";
		pinctrl-0 = <0x5e 0x5f 0x60>;
		status = "disabled";
		phandle = <0x100>;
	};

	i2c0: i2c@ff180000 {
		compatible = "rockchip,rk3399-i2c";
		reg = <0x00 0xff180000 0x00 0x1000>;
		clocks = <0x02 0x1d 0x02 0x14e>;
		clock-names = "i2c", "pclk";
		interrupts = <0x00 0x07 0x04>;
		pinctrl-names = "default";
		pinctrl-0 = <0x61>;
		#address-cells = <0x01>;
		#size-cells = <0x00>;
		status = "okay";
		phandle = <0x101>;

		rk817: pmic@20 {
			compatible = "rockchip,rk817";
			reg = <0x20>;
			interrupt-parent = <0x62>;
			interrupts = <0x07 0x08>;
			pinctrl-names = "default", "pmic-sleep", "pmic-power-off", "pmic-reset";
			pinctrl-0 = <0x63>;
			pinctrl-1 = <0x64 0x65>;
			pinctrl-2 = <0x66 0x67>;
			pinctrl-3 = <0x68 0x69>;
			rockchip,system-power-controller;
			wakeup-source;
			#clock-cells = <0x01>;
			clock-output-names = "rk808-clkout1", "wifibt_32kin";
			pmic-reset-func = <0x01>;
			vcc1-supply = <0x6a>;
			vcc2-supply = <0x6a>;
			vcc3-supply = <0x6a>;
			vcc4-supply = <0x6a>;
			vcc5-supply = <0x6a>;
			vcc6-supply = <0x6a>;
			vcc7-supply = <0x4c>;
			vcc8-supply = <0x6a>;
			vcc9-supply = <0x6b>;
			phandle = <0xd9>;

			pwrkey {
				status = "okay";
			};

			pinctrl_rk8xx: pinctrl_rk8xx {
				gpio-controller;
				#gpio-cells = <0x02>;
				phandle = <0x102>;

				rk817_ts_gpio1: rk817_ts_gpio1 {
					pins = "gpio_ts";
					function = "pin_fun1";
					phandle = <0x103>;
				};

				rk817_gt_gpio2: rk817_gt_gpio2 {
					pins = "gpio_gt";
					function = "pin_fun1";
					phandle = <0x104>;
				};

				rk817_pin_ts: rk817_pin_ts {
					pins = "gpio_ts";
					function = "pin_fun0";
					phandle = <0x105>;
				};

				rk817_pin_gt: rk817_pin_gt {
					pins = "gpio_gt";
					function = "pin_fun0";
					phandle = <0x106>;
				};

				rk817_slppin_null: rk817_slppin_null {
					pins = "gpio_slp";
					function = "pin_fun0";
					phandle = <0x107>;
				};

				rk817_slppin_slp: rk817_slppin_slp {
					pins = "gpio_slp";
					function = "pin_fun1";
					phandle = <0x65>;
				};

				rk817_slppin_pwrdn: rk817_slppin_pwrdn {
					pins = "gpio_slp";
					function = "pin_fun2";
					phandle = <0x67>;
				};

				rk817_slppin_rst: rk817_slppin_rst {
					pins = "gpio_slp";
					function = "pin_fun3";
					phandle = <0x69>;
				};
			};

			regulators {

				vdd_logic: DCDC_REG1 {
					regulator-always-on;
					regulator-boot-on;
					regulator-min-microvolt = <0xcf850>;
					regulator-max-microvolt = <0x149970>;
					regulator-ramp-delay = <0x1771>;
					regulator-initial-mode = <0x02>;
					regulator-name = "vdd_logic";
					phandle = <0x0e>;

					regulator-state-mem {
						regulator-on-in-suspend;
						regulator-suspend-microvolt = <0xe7ef0>;
					};
				};

				vdd_arm: DCDC_REG2 {
					regulator-always-on;
					regulator-boot-on;
					regulator-min-microvolt = <0xcf850>;
					regulator-max-microvolt = <0x149970>;
					regulator-ramp-delay = <0x1771>;
					regulator-initial-mode = <0x02>;
					regulator-name = "vdd_arm";
					phandle = <0x06>;

					regulator-state-mem {
						regulator-off-in-suspend;
						regulator-suspend-microvolt = <0xe7ef0>;
					};
				};

				vcc_ddr: DCDC_REG3 {
					regulator-always-on;
					regulator-boot-on;
					regulator-initial-mode = <0x02>;
					regulator-name = "vcc_ddr";
					phandle = <0x108>;

					regulator-state-mem {
						regulator-on-in-suspend;
					};
				};

				vcc_3v0: DCDC_REG4 {
					regulator-always-on;
					regulator-boot-on;
					regulator-min-microvolt = <0x325aa0>;
					regulator-max-microvolt = <0x325aa0>;
					regulator-initial-mode = <0x02>;
					regulator-name = "vcc_3v0";
					phandle = <0x4c>;

					regulator-state-mem {
						regulator-on-in-suspend;
						regulator-suspend-microvolt = <0x325aa0>;
					};
				};

				vcc_1v0: LDO_REG1 {
					regulator-always-on;
					regulator-boot-on;
					regulator-min-microvolt = <0xf4240>;
					regulator-max-microvolt = <0xf4240>;
					regulator-name = "vcc_1v0";
					phandle = <0x109>;

					regulator-state-mem {
						regulator-on-in-suspend;
						regulator-suspend-microvolt = <0xf4240>;
					};
				};

				vcc1v8_soc: LDO_REG2 {
					regulator-always-on;
					regulator-boot-on;
					regulator-min-microvolt = <0x1b7740>;
					regulator-max-microvolt = <0x1b7740>;
					regulator-name = "vcc1v8_soc";
					phandle = <0x8f>;

					regulator-state-mem {
						regulator-on-in-suspend;
						regulator-suspend-microvolt = <0x1b7740>;
					};
				};

				vdd1v0_soc: LDO_REG3 {
					regulator-always-on;
					regulator-boot-on;
					regulator-min-microvolt = <0xf4240>;
					regulator-max-microvolt = <0xf4240>;
					regulator-name = "vcc1v0_soc";
					phandle = <0x10a>;

					regulator-state-mem {
						regulator-on-in-suspend;
						regulator-suspend-microvolt = <0xf4240>;
					};
				};

				vcc3v0_pmu: LDO_REG4 {
					regulator-always-on;
					regulator-boot-on;
					regulator-min-microvolt = <0x2dc6c0>;
					regulator-max-microvolt = <0x2dc6c0>;
					regulator-name = "vcc3v0_pmu";
					phandle = <0x2b>;

					regulator-state-mem {
						regulator-on-in-suspend;
						regulator-suspend-microvolt = <0x2dc6c0>;
					};
				};

				vccio_sd: LDO_REG5 {
					regulator-always-on;
					regulator-boot-on;
					regulator-min-microvolt = <0x1b7740>;
					regulator-max-microvolt = <0x325aa0>;
					regulator-name = "vccio_sd";
					phandle = <0x4d>;

					regulator-state-mem {
						regulator-on-in-suspend;
						regulator-suspend-microvolt = <0x325aa0>;
					};
				};

				vcc_sd: LDO_REG6 {
					regulator-min-microvolt = <0x325aa0>;
					regulator-max-microvolt = <0x325aa0>;
					regulator-name = "vcc_sd";
					phandle = <0x9c>;

					regulator-state-mem {
						regulator-on-in-suspend;
						regulator-suspend-microvolt = <0x325aa0>;
					};
				};

				vcc2v8_dvp: LDO_REG7 {
					regulator-boot-on;
					regulator-always-on;
					regulator-min-microvolt = <0x325aa0>;
					regulator-max-microvolt = <0x325aa0>;
					regulator-name = "vcc2v8_dvp";
					phandle = <0x4e>;

					regulator-state-mem {
						regulator-on-in-suspend;
						regulator-suspend-microvolt = <0x325aa0>;
					};
				};

				vcc1v8_dvp: LDO_REG8 {
					regulator-boot-on;
					regulator-min-microvolt = <0x1b7740>;
					regulator-max-microvolt = <0x1b7740>;
					regulator-name = "vcc1v8_dvp";
					phandle = <0x10b>;

					regulator-state-mem {
						regulator-off-in-suspend;
						regulator-suspend-microvolt = <0x1b7740>;
					};
				};

				vcc_lcd: LDO_REG9 {
					regulator-boot-on;
					regulator-min-microvolt = <0x325aa0>;
					regulator-max-microvolt = <0x325aa0>;
					regulator-name = "vcc_lcd";
					phandle = <0xd5>;

					regulator-state-mem {
						regulator-off-in-suspend;
						regulator-suspend-microvolt = <0x16e360>;
					};
				};

				dcdc_boost: BOOST {
					regulator-always-on;
					regulator-boot-on;
					regulator-min-microvolt = <0x47b760>;
					regulator-max-microvolt = <0x5265c0>;
					regulator-name = "boost";
					phandle = <0x6b>;
				};

				otg_switch: OTG_SWITCH {
					regulator-name = "otg_switch";
					phandle = <0x10c>;
				};
			};

			battery {
				compatible = "rk817,battery";
				ocv_table = <0xdac 0xddc 0xe08 0xe34 0xe67 0xe9c 0xec4 0xede 0xef3 0xf06 0xf18 0xf31 0xf59 0xf7c 0xf99 0xfaf 0xfbe 0xfc9 0xfd8 0xfec 0x1034>;
				design_capacity = <0xfa0>;
				design_qmax = <0x1068>;
				bat_res = <0x64>;
				sleep_enter_current = <0x96>;
				sleep_exit_current = <0xb4>;
				sleep_filter_current = <0x64>;
				power_off_thresd = <0xdac>;
				zero_algorithm_vol = <0xf0a>;
				max_soc_offset = <0x3c>;
				monitor_sec = <0x05>;
				sample_res = <0x0a>;
				virtual_power = <0x00>;
			};

			charger {
				compatible = "rk817,charger";
				min_input_voltage = <0x1194>;
				max_input_current = <0x5dc>;
				max_chrg_current = <0x7d0>;
				max_chrg_voltage = <0x1068>;
				chrg_term_mode = <0x00>;
				chrg_finish_cur = <0x12c>;
				virtual_power = <0x00>;
				dc_det_adc = <0x00>;
				extcon = <0x6c>;
			};

			rk817_codec: codec {
				#sound-dai-cells = <0x00>;
				compatible = "rockchip,rk817-codec";
				clocks = <0x02 0x15>;
				clock-names = "mclk";
				pinctrl-names = "default";
				pinctrl-0 = <0x6d>;
				spk-ctl-gpios = <0x6e 0x14 0x01>;
				hp-volume = <0x05>;
				spk-volume = <0x02>;
				capture-volume = <0x05>;
				use-ext-amplifier;
				mic-in-differential;
				status = "okay";
				phandle = <0xd0>;
			};
		};
	};

	i2c1: i2c@ff190000 {
		compatible = "rockchip,rk3399-i2c";
		reg = <0x00 0xff190000 0x00 0x1000>;
		clocks = <0x02 0x1e 0x02 0x14f>;
		clock-names = "i2c", "pclk";
		interrupts = <0x00 0x08 0x04>;
		pinctrl-names = "default";
		pinctrl-0 = <0x6f>;
		#address-cells = <0x01>;
		#size-cells = <0x00>;
		status = "okay";
		clock-frequency = <0x61a80>;
		phandle = <0x10d>;

		rk628_csi_v4l2: rk628_csi_v4l2@50 {
			reg = <0x50>;
			hpd-output-inverted;
			compatible = "rockchip,rk628-csi-v4l2";
			interrupt-parent = <0x6e>;
			interrupts = <0x1a 0x04>;
			enable-gpios = <0x6e 0x18 0x00>;
			reset-gpios = <0x6e 0x19 0x01>;
			plugin-det-gpios = <0x6e 0x1b 0x00>;
			power-gpios = <0x6e 0x17 0x00>;
			hdcp-enable = <0x01>;
			scaler-en = <0x01>;
			rockchip,camera-module-index = <0x00>;
			rockchip,camera-module-facing = "back";
			rockchip,camera-module-name = "RK628-CSI";
			rockchip,camera-module-lens-name = "NC";
			phandle = <0x10e>;

			port {

				hdmiin_out0: endpoint {
					remote-endpoint = <0x70>;
					data-lanes = <0x01 0x02 0x03 0x04>;
					phandle = <0x92>;
				};
			};
		};

		sensor@26 {
			compatible = "gs_mir3da";
			reg = <0x26>;
			type = <0x02>;
			irq_enable = <0x00>;
			poll_delay_ms = <0x14>;
			layout = <0x01>;
			status = "okay";
		};
	};

	i2c2: i2c@ff1a0000 {
		compatible = "rockchip,rk3399-i2c";
		reg = <0x00 0xff1a0000 0x00 0x1000>;
		clocks = <0x02 0x1f 0x02 0x150>;
		clock-names = "i2c", "pclk";
		interrupts = <0x00 0x09 0x04>;
		pinctrl-names = "default";
		pinctrl-0 = <0x71>;
		#address-cells = <0x01>;
		#size-cells = <0x00>;
		status = "disabled";
		phandle = <0x10f>;
	};

	i2c3: i2c@ff1b0000 {
		compatible = "rockchip,rk3399-i2c";
		reg = <0x00 0xff1b0000 0x00 0x1000>;
		clocks = <0x02 0x20 0x02 0x151>;
		clock-names = "i2c", "pclk";
		interrupts = <0x00 0x0a 0x04>;
		pinctrl-names = "default";
		pinctrl-0 = <0x72>;
		#address-cells = <0x01>;
		#size-cells = <0x00>;
		status = "disabled";
		phandle = <0x110>;
	};

	spi0: spi@ff1d0000 {
		compatible = "rockchip,px30-spi", "rockchip,rk3066-spi";
		reg = <0x00 0xff1d0000 0x00 0x1000>;
		interrupts = <0x00 0x1a 0x04>;
		#address-cells = <0x01>;
		#size-cells = <0x00>;
		clocks = <0x02 0x24 0x02 0x155>;
		clock-names = "spiclk", "apb_pclk";
		dmas = <0x2d 0x0c 0x2d 0x0d>;
		dma-names = "tx", "rx";
		pinctrl-names = "default", "high_speed";
		pinctrl-0 = <0x73 0x74 0x75 0x76>;
		pinctrl-1 = <0x77 0x74 0x78 0x79>;
		status = "disabled";
		phandle = <0x111>;
	};

	spi1: spi@ff1d8000 {
		compatible = "rockchip,px30-spi", "rockchip,rk3066-spi";
		reg = <0x00 0xff1d8000 0x00 0x1000>;
		interrupts = <0x00 0x1b 0x04>;
		#address-cells = <0x01>;
		#size-cells = <0x00>;
		clocks = <0x02 0x25 0x02 0x156>;
		clock-names = "spiclk", "apb_pclk";
		dmas = <0x2d 0x0e 0x2d 0x0f>;
		dma-names = "tx", "rx";
		pinctrl-names = "default", "high_speed";
		pinctrl-0 = <0x7a 0x7b 0x7c 0x7d 0x7e>;
		pinctrl-1 = <0x7f 0x7b 0x7c 0x80 0x81>;
		status = "disabled";
		phandle = <0x112>;
	};

	wdt: watchdog@ff1e0000 {
		compatible = "snps,dw-wdt";
		reg = <0x00 0xff1e0000 0x00 0x100>;
		clocks = <0x02 0x15b>;
		interrupts = <0x00 0x25 0x04>;
		resets = <0x02 0xb5>;
		reset-names = "reset";
		status = "disabled";
		phandle = <0x113>;
	};

	pwm0: pwm@ff200000 {
		compatible = "rockchip,remotectl-pwm";
		reg = <0x00 0xff200000 0x00 0x10>;
		#pwm-cells = <0x03>;
		pinctrl-names = "default";
		pinctrl-0 = <0x82>;
		clocks = <0x02 0x22 0x02 0x153>;
		clock-names = "pwm", "pclk";
		status = "okay";
		interrupts = <0x00 0x18 0x04>;
		remote_pwm_id = <0x00>;
		handle_cpu_id = <0x01>;
		remote_support_psci = <0x01>;
		phandle = <0x114>;

		ir_key1 {
			rockchip,usercode = <0x4040>;
			rockchip,key_table = <0xe5 0xac 0xbd 0x9e 0xf2 0xe8 0xf4 0x67 0xf1 0x6c 0xef 0x69 0xee 0x6a 0xba 0x3d>;
		};

		ir_key2 {
			rockchip,usercode = <0xff00>;
			rockchip,key_table = <0x57 0x74 0x77 0x71 0x63 0x72 0x67 0xa5 0x7d 0xa3 0x6c 0xa4 0x73 0x73 0x68 0xac 0x5b 0x9e 0x61 0xe8 0x6a 0x67 0x65 0x6c 0x64 0x69 0x66 0x6a 0x6e 0x8b 0x29 0x184>;
		};

		ir_key3 {
			rockchip,usercode = <0x1dcc>;
			rockchip,key_table = <0xff 0x74 0xf3 0x71 0xfd 0x72 0xf9 0xa5 0xf5 0xa3 0xe9 0xa4 0xf1 0x73 0xfc 0xac 0xf0 0x9e 0xee 0xe8 0xf8 0x67 0xbb 0x6c 0xef 0x69 0xed 0x6a 0xbf 0x8b 0xbe 0x02 0xba 0x03 0xb2 0x04 0xbd 0x2e8 0xb9 0x2e9 0xb1 0x07 0xbc 0x08 0xb8 0x09 0xb0 0x0a 0xb6 0x0b 0xb5 0x0e 0xfe 0x3b 0xfa 0x3c 0xf6 0x3d 0xf2 0x3e 0xb7 0x40 0xb3 0x184>;
		};

		ir_key4 {
			rockchip,usercode = <0xfe01>;
			rockchip,key_table = <0xbf 0x74 0xef 0x72 0xe7 0x73 0xee 0xac 0xe6 0x9e 0x99 0x9e 0xec 0xe8 0xe9 0x67 0xe5 0x6c 0xae 0x69 0xaf 0x6a 0xb3 0x8b 0xbe 0x71 0xbc 0x3b 0xf0 0x3c 0xe8 0x3d 0xff 0x184>;
		};

		ir_key5 {
			rockchip,usercode = <0x1608>;
			rockchip,key_table = <0x78 0x74 0xa4 0x71 0x4a 0x72 0x76 0x73 0xb0 0xac 0x74 0x9e 0x4d 0xe8 0x7b 0x67 0x72 0x6c 0x44 0x69 0x71 0x6a 0x75 0x3d 0x23 0x184>;
		};

		ir_key6 {
			rockchip,usercode = <0xf708>;
			rockchip,key_table = <0x7f 0x74 0x7d 0x72 0x7e 0x73 0x9f 0xac 0x9c 0x9e 0x9a 0xe8 0x9d 0x67 0x97 0x6c 0x9b 0x69 0x99 0x6a 0x98 0x8b 0x86 0x71 0x87 0x3c 0x8d 0x184>;
		};
	};

	pwm1: pwm@ff200010 {
		compatible = "rockchip,px30-pwm", "rockchip,rk3328-pwm";
		reg = <0x00 0xff200010 0x00 0x10>;
		#pwm-cells = <0x03>;
		pinctrl-names = "active";
		pinctrl-0 = <0x83>;
		clocks = <0x02 0x22 0x02 0x153>;
		clock-names = "pwm", "pclk";
		status = "okay";
		phandle = <0x115>;
	};

	pwm2: pwm@ff200020 {
		compatible = "rockchip,px30-pwm", "rockchip,rk3328-pwm";
		reg = <0x00 0xff200020 0x00 0x10>;
		#pwm-cells = <0x03>;
		pinctrl-names = "active";
		pinctrl-0 = <0x84>;
		clocks = <0x02 0x22 0x02 0x153>;
		clock-names = "pwm", "pclk";
		status = "disabled";
		phandle = <0x116>;
	};

	pwm3: pwm@ff200030 {
		compatible = "rockchip,px30-pwm", "rockchip,rk3328-pwm";
		reg = <0x00 0xff200030 0x00 0x10>;
		#pwm-cells = <0x03>;
		pinctrl-names = "active";
		pinctrl-0 = <0x85>;
		clocks = <0x02 0x22 0x02 0x153>;
		clock-names = "pwm", "pclk";
		status = "disabled";
		phandle = <0x117>;
	};

	pwm4: pwm@ff208000 {
		compatible = "rockchip,px30-pwm", "rockchip,rk3328-pwm";
		reg = <0x00 0xff208000 0x00 0x10>;
		#pwm-cells = <0x03>;
		pinctrl-names = "active";
		pinctrl-0 = <0x86>;
		clocks = <0x02 0x23 0x02 0x154>;
		clock-names = "pwm", "pclk";
		status = "disabled";
		phandle = <0x118>;
	};

	pwm5: pwm@ff208010 {
		compatible = "rockchip,px30-pwm", "rockchip,rk3328-pwm";
		reg = <0x00 0xff208010 0x00 0x10>;
		#pwm-cells = <0x03>;
		pinctrl-names = "active";
		pinctrl-0 = <0x87>;
		clocks = <0x02 0x23 0x02 0x154>;
		clock-names = "pwm", "pclk";
		status = "disabled";
		phandle = <0x119>;
	};

	pwm6: pwm@ff208020 {
		compatible = "rockchip,px30-pwm", "rockchip,rk3328-pwm";
		reg = <0x00 0xff208020 0x00 0x10>;
		#pwm-cells = <0x03>;
		pinctrl-names = "active";
		pinctrl-0 = <0x88>;
		clocks = <0x02 0x23 0x02 0x154>;
		clock-names = "pwm", "pclk";
		status = "disabled";
		phandle = <0x11a>;
	};

	pwm7: pwm@ff208030 {
		compatible = "rockchip,px30-pwm", "rockchip,rk3328-pwm";
		reg = <0x00 0xff208030 0x00 0x10>;
		#pwm-cells = <0x03>;
		pinctrl-names = "active";
		pinctrl-0 = <0x89>;
		clocks = <0x02 0x23 0x02 0x154>;
		clock-names = "pwm", "pclk";
		status = "disabled";
		phandle = <0x11b>;
	};

	rktimer: rktimer@ff210000 {
		compatible = "rockchip,rk3288-timer";
		reg = <0x00 0xff210000 0x00 0x1000>;
		interrupts = <0x00 0x1e 0x04>;
		clocks = <0x02 0x159 0x02 0x26>;
		clock-names = "pclk", "timer";
		phandle = <0x11c>;
	};

	amba {
		compatible = "simple-bus";
		#address-cells = <0x02>;
		#size-cells = <0x02>;
		ranges;

		dmac: dmac@ff240000 {
			compatible = "arm,pl330", "arm,primecell";
			reg = <0x00 0xff240000 0x00 0x4000>;
			interrupts = <0x00 0x01 0x04 0x00 0x02 0x04>;
			clocks = <0x02 0xbb>;
			clock-names = "apb_pclk";
			#dma-cells = <0x01>;
			arm,pl330-periph-burst;
			phandle = <0x2d>;
		};
	};

	thermal_zones: thermal-zones {
		phandle = <0x11d>;

		soc_thermal: soc-thermal {
			polling-delay-passive = <0x14>;
			polling-delay = <0x3e8>;
			sustainable-power = <0x2ee>;
			thermal-sensors = <0x8a 0x00>;
			phandle = <0x11e>;

			trips {

				threshold: trip-point-0 {
					temperature = <0x11170>;
					hysteresis = <0x7d0>;
					type = "passive";
					phandle = <0x11f>;
				};

				target: trip-point-1 {
					temperature = <0x14c08>;
					hysteresis = <0x7d0>;
					type = "passive";
					phandle = <0x8b>;
				};

				soc_crit: soc-crit {
					temperature = <0x1c138>;
					hysteresis = <0x7d0>;
					type = "critical";
					phandle = <0x120>;
				};
			};

			cooling-maps {

				map0 {
					trip = <0x8b>;
					cooling-device = <0x09 0xffffffff 0xffffffff>;
					contribution = <0x1000>;
				};

				map1 {
					trip = <0x8b>;
					cooling-device = <0x8c 0xffffffff 0xffffffff>;
					contribution = <0x1000>;
				};
			};
		};

		gpu_thermal: gpu-thermal {
			polling-delay-passive = <0x64>;
			polling-delay = <0x3e8>;
			thermal-sensors = <0x8a 0x01>;
			phandle = <0x121>;
		};
	};

	tsadc: tsadc@ff280000 {
		compatible = "rockchip,px30-tsadc";
		reg = <0x00 0xff280000 0x00 0x100>;
		interrupts = <0x00 0x24 0x04>;
		rockchip,grf = <0x31>;
		clocks = <0x02 0x2c 0x02 0x158>;
		clock-names = "tsadc", "apb_pclk";
		assigned-clocks = <0x02 0x2c>;
		assigned-clock-rates = <0xc350>;
		resets = <0x02 0xa8>;
		reset-names = "tsadc-apb";
		#thermal-sensor-cells = <0x01>;
		rockchip,hw-tshut-temp = <0x1d4c0>;
		status = "okay";
		pinctrl-names = "gpio", "otpout";
		pinctrl-0 = <0x8d>;
		pinctrl-1 = <0x8e>;
		phandle = <0x8a>;
	};

	saradc: saradc@ff288000 {
		compatible = "rockchip,px30-saradc", "rockchip,rk3399-saradc";
		reg = <0x00 0xff288000 0x00 0x100>;
		interrupts = <0x00 0x54 0x04>;
		#io-channel-cells = <0x01>;
		clocks = <0x02 0x2d 0x02 0x157>;
		clock-names = "saradc", "apb_pclk";
		resets = <0x02 0xa5>;
		reset-names = "saradc-apb";
		status = "okay";
		vref-supply = <0x8f>;
		phandle = <0xce>;
	};

	otp: otp@ff290000 {
		compatible = "rockchip,px30-otp";
		reg = <0x00 0xff290000 0x00 0x4000>;
		#address-cells = <0x01>;
		#size-cells = <0x01>;
		clocks = <0x02 0x2f 0x02 0x15a 0x02 0x161>;
		clock-names = "otp", "apb_pclk", "phy";
		resets = <0x02 0xb4>;
		reset-names = "otp_phy";
		phandle = <0x122>;

		otp_id: id@7 {
			reg = <0x07 0x10>;
			phandle = <0x0f>;
		};

		cpu_leakage: cpu-leakage@17 {
			reg = <0x17 0x01>;
			phandle = <0x07>;
		};

		performance: performance@1e {
			reg = <0x1e 0x01>;
			bits = <0x04 0x03>;
			phandle = <0x08>;
		};
	};

	cru: clock-controller@ff2b0000 {
		compatible = "rockchip,px30-cru";
		reg = <0x00 0xff2b0000 0x00 0x1000>;
		rockchip,grf = <0x31>;
		rockchip,boost = <0x90>;
		#clock-cells = <0x01>;
		#reset-cells = <0x01>;
		assigned-clocks = <0x02 0x04>;
		assigned-clock-rates = <0x3dfd2400>;
		phandle = <0x02>;
	};

	cpu_boost: cpu-boost@ff2b8000 {
		compatible = "syscon";
		reg = <0x00 0xff2b8000 0x00 0x1000>;
		rockchip,boost-low-con0 = <0x1032>;
		rockchip,boost-low-con1 = <0x1441>;
		rockchip,boost-high-con0 = <0x1036>;
		rockchip,boost-high-con1 = <0x1441>;
		rockchip,boost-backup-pll = <0x01>;
		rockchip,boost-backup-pll-usage = <0x00>;
		rockchip,boost-switch-threshold = <0x249f00>;
		rockchip,boost-statis-threshold = <0x100>;
		rockchip,boost-statis-enable = <0x00>;
		rockchip,boost-enable = <0x00>;
		phandle = <0x90>;
	};

	pmucru: pmu-clock-controller@ff2bc000 {
		compatible = "rockchip,px30-pmucru";
		reg = <0x00 0xff2bc000 0x00 0x1000>;
		rockchip,grf = <0x31>;
		#clock-cells = <0x01>;
		#reset-cells = <0x01>;
		assigned-clocks = <0x2c 0x01 0x2c 0x08 0x2c 0x05 0x02 0x07 0x02 0xab 0x02 0xb0 0x02 0xf0 0x02 0xf5 0x02 0x140 0x02 0x49>;
		assigned-clock-rates = <0x47868c00 0x5f5e100 0x18cba80 0x23c34600 0xbebc200 0xbebc200 0x8f0d180 0x8f0d180 0x5f5e100 0xbebc200>;
		phandle = <0x2c>;
	};

	usb2phy_grf: syscon@ff2c0000 {
		compatible = "rockchip,px30-usb2phy-grf", "syscon", "simple-mfd";
		reg = <0x00 0xff2c0000 0x00 0x10000>;
		#address-cells = <0x01>;
		#size-cells = <0x01>;
		phandle = <0x123>;

		u2phy: usb2-phy@100 {
			compatible = "rockchip,px30-usb2phy", "rockchip,rk3328-usb2phy";
			reg = <0x100 0x10>;
			clocks = <0x2c 0x0a>;
			clock-names = "phyclk";
			#clock-cells = <0x00>;
			assigned-clocks = <0x02 0x0e 0x02 0x55>;
			assigned-clock-parents = <0x6c 0x02 0x0e>;
			clock-output-names = "usb480m_phy";
			status = "okay";
			phandle = <0x6c>;

			u2phy_host: host-port {
				#phy-cells = <0x00>;
				interrupts = <0x00 0x44 0x04>;
				interrupt-names = "linestate";
				status = "okay";
				rockchip,low-power-mode;
				phandle = <0x95>;
			};

			u2phy_otg: otg-port {
				#phy-cells = <0x00>;
				interrupts = <0x00 0x42 0x04 0x00 0x41 0x04 0x00 0x40 0x04>;
				interrupt-names = "otg-bvalid", "otg-id", "linestate";
				status = "okay";
				rockchip,low-power-mode;
				phandle = <0x94>;
			};
		};
	};

	video_phy: video-phy@ff2e0000 {
		compatible = "rockchip,px30-video-phy";
		reg = <0x00 0xff2e0000 0x00 0x10000 0x00 0xff450000 0x00 0x10000>;
		clocks = <0x2c 0x0b 0x02 0x145 0x02 0x144>;
		clock-names = "ref", "pclk_phy", "pclk_host";
		#clock-cells = <0x00>;
		resets = <0x02 0x3e>;
		reset-names = "rst";
		power-domains = <0x91 0x0c>;
		#phy-cells = <0x00>;
		status = "okay";
		phandle = <0x4f>;
	};

	mipi_dphy_rx0: mipi-dphy-rx0@ff2f0000 {
		compatible = "rockchip,rk3326-mipi-dphy";
		reg = <0x00 0xff2f0000 0x00 0x4000>;
		clocks = <0x02 0x146>;
		clock-names = "dphy-ref";
		power-domains = <0x91 0x0d>;
		rockchip,grf = <0x31>;
		status = "okay";
		phandle = <0x124>;

		ports {
			#address-cells = <0x01>;
			#size-cells = <0x00>;

			port@0 {
				reg = <0x00>;
				#address-cells = <0x01>;
				#size-cells = <0x00>;

				mipi_in: endpoint@1 {
					reg = <0x01>;
					remote-endpoint = <0x92>;
					data-lanes = <0x01 0x02 0x03 0x04>;
					phandle = <0x70>;
				};
			};

			port@1 {
				reg = <0x01>;
				#address-cells = <0x01>;
				#size-cells = <0x00>;

				dphy_rx_out: endpoint@0 {
					reg = <0x00>;
					remote-endpoint = <0x93>;
					phandle = <0xb7>;
				};
			};
		};
	};

	usb20_otg: usb@ff300000 {
		compatible = "rockchip,px30-usb", "rockchip,rk3066-usb", "snps,dwc2";
		reg = <0x00 0xff300000 0x00 0x40000>;
		interrupts = <0x00 0x3e 0x04>;
		clocks = <0x02 0x102>;
		clock-names = "otg";
		power-domains = <0x91 0x05>;
		dr_mode = "host";
		g-np-tx-fifo-size = <0x10>;
		g-rx-fifo-size = <0x118>;
		g-tx-fifo-size = <0x100 0x80 0x80 0x40 0x20 0x10>;
		g-use-dma;
		phys = <0x94>;
		phy-names = "usb2-phy";
		status = "okay";
		phandle = <0x125>;
	};

	usb_host0_ehci: usb@ff340000 {
		compatible = "generic-ehci";
		reg = <0x00 0xff340000 0x00 0x10000>;
		interrupts = <0x00 0x3c 0x04>;
		clocks = <0x02 0x103 0x6c>;
		clock-names = "usbhost", "utmi";
		power-domains = <0x91 0x05>;
		phys = <0x95>;
		phy-names = "usb";
		status = "disabled";
		phandle = <0x126>;
	};

	usb_host0_ohci: usb@ff350000 {
		compatible = "generic-ohci";
		reg = <0x00 0xff350000 0x00 0x10000>;
		interrupts = <0x00 0x3d 0x04>;
		clocks = <0x02 0x103 0x6c>;
		clock-names = "usbhost", "utmi";
		power-domains = <0x91 0x05>;
		phys = <0x95>;
		phy-names = "usb";
		status = "disabled";
		phandle = <0x127>;
	};

	gmac: ethernet@ff360000 {
		compatible = "rockchip,px30-gmac";
		reg = <0x00 0xff360000 0x00 0x10000>;
		rockchip,grf = <0x31>;
		interrupts = <0x00 0x2b 0x04>;
		interrupt-names = "macirq";
		clocks = <0x02 0x3e 0x02 0x3f 0x02 0x3f 0x02 0x40 0x02 0x41 0x02 0xb2 0x02 0x143 0x02 0x4c>;
		clock-names = "stmmaceth", "mac_clk_rx", "mac_clk_tx", "clk_mac_ref", "clk_mac_refout", "aclk_mac", "pclk_mac", "clk_mac_speed";
		phy-mode = "rmii";
		pinctrl-names = "default";
		pinctrl-0 = <0x96 0x97>;
		resets = <0x02 0x5e>;
		reset-names = "stmmaceth";
		power-domains = <0x91 0x09>;
		status = "disabled";
		phandle = <0x128>;
	};

	sdmmc: dwmmc@ff370000 {
		compatible = "rockchip,px30-dw-mshc", "rockchip,rk3288-dw-mshc";
		reg = <0x00 0xff370000 0x00 0x4000>;
		max-frequency = <0x8f0d180>;
		clocks = <0x02 0xf7 0x02 0x3b 0x02 0x43 0x02 0x44>;
		clock-names = "biu", "ciu", "ciu-drv", "ciu-sample";
		assigned-clocks = <0x02 0x3b>;
		assigned-clock-parents = <0x02 0x57>;
		power-domains = <0x91 0x07>;
		fifo-depth = <0x100>;
		interrupts = <0x00 0x36 0x04>;
		pinctrl-names = "default";
		pinctrl-0 = <0x98 0x99 0x9a 0x9b>;
		status = "disabled";
		bus-width = <0x04>;
		cap-mmc-highspeed;
		cap-sd-highspeed;
		supports-sd;
		card-detect-delay = <0x320>;
		ignore-pm-notify;
		sd-uhs-sdr12;
		sd-uhs-sdr25;
		sd-uhs-sdr50;
		sd-uhs-sdr104;
		vqmmc-supply = <0x4d>;
		vmmc-supply = <0x9c>;
		phandle = <0x129>;
	};

	sdio: dwmmc@ff380000 {
		compatible = "rockchip,px30-dw-mshc", "rockchip,rk3288-dw-mshc";
		reg = <0x00 0xff380000 0x00 0x4000>;
		max-frequency = <0x2faf080>;
		clocks = <0x02 0xff 0x02 0x38 0x02 0x45 0x02 0x46>;
		clock-names = "biu", "ciu", "ciu-drv", "ciu-sample";
		assigned-clocks = <0x02 0x38>;
		assigned-clock-parents = <0x02 0x51>;
		power-domains = <0x91 0x0a>;
		fifo-depth = <0x100>;
		interrupts = <0x00 0x37 0x04>;
		pinctrl-names = "default";
		pinctrl-0 = <0x9d 0x9e 0x9f>;
		status = "okay";
		bus-width = <0x04>;
		cap-sd-highspeed;
		supports-sdio;
		ignore-pm-notify;
		keep-power-in-suspend;
		non-removable;
		mmc-pwrseq = <0xa0>;
		phandle = <0x12a>;
	};

	emmc: dwmmc@ff390000 {
		compatible = "rockchip,px30-dw-mshc", "rockchip,rk3288-dw-mshc";
		reg = <0x00 0xff390000 0x00 0x4000>;
		max-frequency = <0x8f0d180>;
		clocks = <0x02 0x100 0x02 0x39 0x02 0x47 0x02 0x48>;
		clock-names = "biu", "ciu", "ciu-drv", "ciu-sample";
		assigned-clocks = <0x02 0x39>;
		assigned-clock-parents = <0x02 0x53>;
		power-domains = <0x91 0x0a>;
		fifo-depth = <0x100>;
		interrupts = <0x00 0x35 0x04>;
		status = "okay";
		bus-width = <0x08>;
		cap-mmc-highspeed;
		mmc-hs200-1_8v;
		supports-emmc;
		disable-wp;
		non-removable;
		num-slots = <0x01>;
		phandle = <0x12b>;
	};

	nandc0: nandc@ff3b0000 {
		compatible = "rockchip,rk-nandc";
		reg = <0x00 0xff3b0000 0x00 0x4000>;
		interrupts = <0x00 0x39 0x04>;
		nandc_id = <0x00>;
		clocks = <0x02 0x37 0x02 0xfe>;
		clock-names = "clk_nandc", "hclk_nandc";
		assigned-clocks = <0x02 0x37>;
		assigned-clock-parents = <0x02 0x4f>;
		power-domains = <0x91 0x0a>;
		status = "okay";
		phandle = <0x12c>;
	};

	gpu: gpu@ff400000 {
		compatible = "arm,mali-bifrost";
		reg = <0x00 0xff400000 0x00 0x4000>;
		interrupts = <0x00 0x2d 0x04 0x00 0x2e 0x04 0x00 0x2f 0x04>;
		interrupt-names = "GPU", "MMU", "JOB";
		upthreshold = <0x28>;
		downdifferential = <0x0a>;
		clocks = <0x02 0x49>;
		clock-names = "clk_mali";
		power-domains = <0x91 0x0e>;
		#cooling-cells = <0x02>;
		operating-points-v2 = <0xa1>;
		status = "okay";
		mali-supply = <0x0e>;
		phandle = <0x8c>;

		power_model {
			compatible = "arm,mali-simple-power-model";
			static-coefficient = <0x64578>;
			dynamic-coefficient = <0x2dd>;
			ts = <0x7d00 0x125c 0xffffffb0 0x02>;
			thermal-zone = "gpu-thermal";
		};
	};

	gpu_opp_table: gpu-opp-table {
		compatible = "operating-points-v2";
		rockchip,thermal-zone = "soc-thermal";
		rockchip,temp-hysteresis = <0x1388>;
		rockchip,low-temp = <0x00>;
		rockchip,low-temp-min-volt = <0xf4240>;
		rockchip,low-temp-adjust-volt = <0x00 0x1e0 0xc350>;
		rockchip,max-volt = <0x11edd8>;
		rockchip,evb-irdrop = <0x61a8>;
		rockchip,pvtm-voltage-sel = <0x00 0xc350 0x00 0xc351 0xd2f0 0x01 0xd2f1 0xea60 0x02 0xea61 0x1869f 0x03>;
		rockchip,pvtm-ch = <0x00 0x00>;
		phandle = <0xa1>;

		opp-200000000 {
			opp-hz = <0x00 0xbebc200>;
			opp-microvolt = <0xe7ef0>;
			opp-microvolt-L0 = <0xe7ef0>;
			opp-microvolt-L1 = <0xe7ef0>;
			opp-microvolt-L2 = <0xe7ef0>;
			opp-microvolt-L3 = <0xe7ef0>;
			status = "disabled";
		};

		opp-300000000 {
			opp-hz = <0x00 0x11e1a300>;
			opp-microvolt = <0xee098>;
			opp-microvolt-L0 = <0xee098>;
			opp-microvolt-L1 = <0xe7ef0>;
			opp-microvolt-L2 = <0xe7ef0>;
			opp-microvolt-L3 = <0xe7ef0>;
		};

		opp-400000000 {
			opp-hz = <0x00 0x17d78400>;
			opp-microvolt = <0x100590>;
			opp-microvolt-L0 = <0x100590>;
			opp-microvolt-L1 = <0xfa3e8>;
			opp-microvolt-L2 = <0xee098>;
			opp-microvolt-L3 = <0xe7ef0>;
		};

		opp-480000000 {
			opp-hz = <0x00 0x1c9c3800>;
			opp-microvolt = <0x112a88>;
			opp-microvolt-L0 = <0x112a88>;
			opp-microvolt-L1 = <0x10c8e0>;
			opp-microvolt-L2 = <0x100590>;
			opp-microvolt-L3 = <0xf4240>;
		};

		opp-666000000 {
			opp-hz = <0x00 0x27b25a80>;
			opp-microvolt = <0x112a88>;
			opp-microvolt-L0 = <0x112a88>;
			opp-microvolt-L1 = <0x10c8e0>;
			opp-microvolt-L2 = <0x100590>;
			opp-microvolt-L3 = <0xf4240>;
		};

		opp-520000000 {
			opp-hz = <0x00 0x1efe9200>;
			opp-microvolt = <0x11edd8>;
			opp-microvolt-L0 = <0x11edd8>;
			opp-microvolt-L1 = <0x118c30>;
			opp-microvolt-L2 = <0x10c8e0>;
			opp-microvolt-L3 = <0x100590>;
		};
	};

	px30s_gpu_opp_table: px30s-gpu-opp-table {
		compatible = "operating-points-v2";
		phandle = <0x12d>;

		opp-200000000 {
			opp-hz = <0x00 0xbebc200>;
			opp-microvolt = <0xf4240>;
			status = "disabled";
		};

		opp-300000000 {
			opp-hz = <0x00 0x11e1a300>;
			opp-microvolt = <0xf4240>;
		};

		opp-400000000 {
			opp-hz = <0x00 0x17d78400>;
			opp-microvolt = <0xf4240>;
		};

		opp-520000000 {
			opp-hz = <0x00 0x1efe9200>;
			opp-microvolt = <0xf4240>;
		};

		opp-666000000 {
			opp-hz = <0x00 0x27b25a80>;
			opp-microvolt = <0xf4240>;
		};
	};

	mpp_srv: mpp-srv {
		compatible = "rockchip,mpp-service";
		rockchip,taskqueue-count = <0x01>;
		rockchip,resetgroup-count = <0x01>;
		rockchip,grf = <0x31>;
		rockchip,grf-offset = <0x410>;
		rockchip,grf-values = <0x80008000 0x80000000 0x80000000>;
		rockchip,grf-names = "grf_rkvdec", "grf_vdpu2", "grf_vepu2";
		status = "okay";
		phandle = <0xa3>;
	};

	vdpu: vdpu@ff442400 {
		compatible = "rockchip,vpu-decoder-px30";
		reg = <0x00 0xff442400 0x00 0x400>;
		interrupts = <0x00 0x4f 0x04>;
		interrupt-names = "irq_dec";
		clocks = <0x02 0xaf 0x02 0xf4>;
		clock-names = "aclk_vcodec", "hclk_vcodec";
		resets = <0x02 0x24 0x02 0x26>;
		reset-names = "shared_video_a", "shared_video_h";
		iommus = <0xa2>;
		power-domains = <0x91 0x0b>;
		rockchip,srv = <0xa3>;
		rockchip,taskqueue-node = <0x00>;
		rockchip,resetgroup-node = <0x00>;
		status = "okay";
		phandle = <0x12e>;
	};

	vpu_mmu: iommu@ff442800 {
		compatible = "rockchip,iommu";
		reg = <0x00 0xff442800 0x00 0x100>;
		interrupts = <0x00 0x51 0x04>;
		interrupt-names = "vpu_mmu";
		clocks = <0x02 0xaf 0x02 0xf4>;
		clock-names = "aclk", "iface";
		power-domains = <0x91 0x0b>;
		#iommu-cells = <0x00>;
		status = "okay";
		phandle = <0xa2>;
	};

	vepu: vepu@ff442000 {
		compatible = "rockchip,vpu-encoder-px30";
		reg = <0x00 0xff442000 0x00 0x400>;
		interrupts = <0x00 0x50 0x04>;
		interrupt-names = "irq_enc";
		clocks = <0x02 0xaf 0x02 0xf4>;
		clock-names = "aclk_vcodec", "hclk_vcodec";
		resets = <0x02 0x24 0x02 0x26>;
		reset-names = "shared_video_a", "shared_video_h";
		iommus = <0xa2>;
		power-domains = <0x91 0x0b>;
		rockchip,srv = <0xa3>;
		rockchip,taskqueue-node = <0x00>;
		rockchip,resetgroup-node = <0x00>;
		status = "okay";
		phandle = <0x12f>;
	};

	hevc: hevc@ff440000 {
		compatible = "rockchip,hevc-decoder-px30";
		reg = <0x00 0xff440000 0x00 0x400>;
		interrupts = <0x00 0x31 0x04>;
		interrupt-names = "irq_dec";
		clocks = <0x02 0xaf 0x02 0xf4 0x02 0x4b>;
		clock-names = "aclk_vcodec", "hclk_vcodec", "clk_core";
		resets = <0x02 0x24 0x02 0x26 0x02 0x25 0x02 0x27 0x02 0x3f>;
		reset-names = "shared_video_a", "shared_video_h", "niu_a", "niu_h", "video_core";
		iommus = <0xa4>;
		rockchip,srv = <0xa3>;
		rockchip,taskqueue-node = <0x00>;
		rockchip,resetgroup-node = <0x00>;
		power-domains = <0x91 0x0b>;
		status = "okay";
		phandle = <0x130>;
	};

	hevc_mmu: iommu@ff440440 {
		compatible = "rockchip,iommu";
		reg = <0x00 0xff440440 0x00 0x40 0x00 0xff440480 0x00 0x40>;
		interrupts = <0x00 0x32 0x04>;
		interrupt-names = "hevc_mmu";
		clocks = <0x02 0xaf 0x02 0xf4>;
		clock-names = "aclk", "iface";
		power-domains = <0x91 0x0b>;
		#iommu-cells = <0x00>;
		status = "okay";
		phandle = <0xa4>;
	};

	dsi: dsi@ff450000 {
		compatible = "rockchip,px30-mipi-dsi";
		reg = <0x00 0xff450000 0x00 0x10000>;
		interrupts = <0x00 0x4b 0x04>;
		clocks = <0x02 0x144 0x4f>;
		clock-names = "pclk", "hs_clk";
		resets = <0x02 0x3d>;
		reset-names = "apb";
		phys = <0x4f>;
		phy-names = "mipi_dphy";
		power-domains = <0x91 0x0c>;
		rockchip,grf = <0x31>;
		#address-cells = <0x01>;
		#size-cells = <0x00>;
		status = "disabled";
		phandle = <0x131>;

		ports {
			#address-cells = <0x01>;
			#size-cells = <0x00>;

			port@0 {
				reg = <0x00>;
				#address-cells = <0x01>;
				#size-cells = <0x00>;

				dsi_in_vopb: endpoint@0 {
					reg = <0x00>;
					remote-endpoint = <0x14>;
					phandle = <0xaa>;
				};

				dsi_in_vopl: endpoint@1 {
					reg = <0x01>;
					remote-endpoint = <0xa5>;
					phandle = <0xae>;
				};
			};

			port@1 {
				reg = <0x01>;

				dsi_out_panel: endpoint {
					remote-endpoint = <0xa6>;
					phandle = <0xa7>;
				};
			};
		};

		panel@0 {
			reg = <0x00>;

			ports {
				#address-cells = <0x01>;
				#size-cells = <0x00>;

				port@0 {
					reg = <0x00>;

					panel_in_dsi: endpoint {
						remote-endpoint = <0xa7>;
						phandle = <0xa6>;
					};
				};
			};
		};
	};

	vopb: vop@ff460000 {
		compatible = "rockchip,px30-vop-big";
		reg = <0x00 0xff460000 0x00 0x1fc 0x00 0xff460a00 0x00 0x400>;
		rockchip,grf = <0x31>;
		reg-names = "regs", "gamma_lut";
		interrupts = <0x00 0x4d 0x04>;
		clocks = <0x02 0xb5 0x02 0x96 0x02 0xfb>;
		clock-names = "aclk_vop", "dclk_vop", "hclk_vop";
		power-domains = <0x91 0x0c>;
		iommus = <0xa8>;
		status = "okay";
		support-multi-area;
		phandle = <0x132>;

		vopb_out: port {
			#address-cells = <0x01>;
			#size-cells = <0x00>;
			phandle = <0x10>;

			vopb_out_lvds: endpoint@0 {
				reg = <0x00>;
				remote-endpoint = <0xa9>;
				phandle = <0x13>;
			};

			vopb_out_dsi: endpoint@1 {
				reg = <0x01>;
				remote-endpoint = <0xaa>;
				phandle = <0x14>;
			};

			vopb_out_rgb: endpoint@2 {
				reg = <0x02>;
				remote-endpoint = <0xab>;
				phandle = <0x15>;
			};
		};
	};

	vopb_mmu: iommu@ff460f00 {
		compatible = "rockchip,iommu";
		reg = <0x00 0xff460f00 0x00 0x100>;
		interrupts = <0x00 0x4d 0x04>;
		interrupt-names = "vopb_mmu";
		clocks = <0x02 0xb5 0x02 0xfb>;
		clock-names = "aclk", "iface";
		power-domains = <0x91 0x0c>;
		#iommu-cells = <0x00>;
		status = "okay";
		phandle = <0xa8>;
	};

	vopl: vop@ff470000 {
		compatible = "rockchip,px30-vop-lit";
		reg = <0x00 0xff470000 0x00 0x1fc 0x00 0xff470a00 0x00 0x400>;
		rockchip,grf = <0x31>;
		reg-names = "regs", "gamma_lut";
		interrupts = <0x00 0x4e 0x04>;
		clocks = <0x02 0xb6 0x02 0x97 0x02 0xfc>;
		clock-names = "aclk_vop", "dclk_vop", "hclk_vop";
		power-domains = <0x91 0x0c>;
		iommus = <0xac>;
		status = "okay";
		phandle = <0x133>;

		vopl_out: port {
			#address-cells = <0x01>;
			#size-cells = <0x00>;
			phandle = <0x11>;

			vopl_out_lvds: endpoint@0 {
				reg = <0x00>;
				remote-endpoint = <0xad>;
				phandle = <0x50>;
			};

			vopl_out_dsi: endpoint@1 {
				reg = <0x01>;
				remote-endpoint = <0xae>;
				phandle = <0xa5>;
			};

			vopl_out_rgb: endpoint@2 {
				reg = <0x02>;
				remote-endpoint = <0xaf>;
				phandle = <0x54>;
			};
		};
	};

	vopl_mmu: iommu@ff470f00 {
		compatible = "rockchip,iommu";
		reg = <0x00 0xff470f00 0x00 0x100>;
		interrupts = <0x00 0x4e 0x04>;
		interrupt-names = "vopl_mmu";
		clocks = <0x02 0xb6 0x02 0xfc>;
		clock-names = "aclk", "iface";
		power-domains = <0x91 0x0c>;
		#iommu-cells = <0x00>;
		status = "okay";
		phandle = <0xac>;
	};

	rk_rga: rk_rga@ff480000 {
		compatible = "rockchip,rga2";
		reg = <0x00 0xff480000 0x00 0x1000>;
		interrupts = <0x00 0x4c 0x04>;
		clocks = <0x02 0xb7 0x02 0xfd 0x02 0x35>;
		clock-names = "aclk_rga", "hclk_rga", "clk_rga";
		power-domains = <0x91 0x0c>;
		status = "okay";
		phandle = <0x134>;
	};

	cif: cif@ff490000 {
		compatible = "rockchip,cif";
		reg = <0x00 0xff490000 0x00 0x200>;
		interrupts = <0x00 0x45 0x04>;
		clocks = <0x02 0xb3 0x02 0xf9 0x02 0x160 0x02 0x34>;
		clock-names = "aclk_cif0", "hclk_cif0", "pclk_cif", "cif0_out";
		resets = <0x02 0x2c 0x02 0x2d 0x02 0x2e>;
		reset-names = "rst_cif_a", "rst_cif_h", "rst_cif_pclkin";
		power-domains = <0x91 0x0d>;
		pinctrl-names = "cif_pin_all";
		pinctrl-0 = <0xb0>;
		iommus = <0xb1>;
		status = "disabled";
		phandle = <0x135>;
	};

	cif_new: cif-new@ff490000 {
		compatible = "rockchip,px30-cif";
		reg = <0x00 0xff490000 0x00 0x200>;
		interrupts = <0x00 0x45 0x04>;
		clocks = <0x02 0xb3 0x02 0xf9 0x02 0x160 0x02 0x34>;
		clock-names = "aclk_cif", "hclk_cif", "pclk_cif", "cif_out";
		resets = <0x02 0x2c 0x02 0x2d 0x02 0x2e>;
		reset-names = "rst_cif_a", "rst_cif_h", "rst_cif_pclkin";
		power-domains = <0x91 0x0d>;
		iommus = <0xb1>;
		status = "disabled";
		phandle = <0x136>;
	};

	vip_mmu: iommu@ff490800 {
		compatible = "rockchip,iommu";
		reg = <0x00 0xff490800 0x00 0x100>;
		interrupts = <0x00 0x45 0x04>;
		interrupt-names = "vip_mmu";
		clocks = <0x02 0xb3 0x02 0xf9>;
		clock-names = "aclk", "iface";
		power-domains = <0x91 0x0d>;
		rk_iommu,disable_reset_quirk;
		#iommu-cells = <0x00>;
		status = "okay";
		phandle = <0xb1>;
	};

	rk_isp: rk_isp@ff4a0000 {
		compatible = "rockchip,px30-isp", "rockchip,isp";
		reg = <0x00 0xff4a0000 0x00 0x8000>;
		interrupts = <0x00 0x46 0x04>;
		clocks = <0x02 0xb4 0x02 0xfa 0x02 0x33 0x02 0x33 0x02 0x15f 0x02 0x34 0x02 0x34 0x02 0x146>;
		clock-names = "aclk_isp", "hclk_isp", "clk_isp", "clk_isp_jpe", "pclkin_isp", "clk_cif_pll", "clk_cif_out", "pclk_dphyrx";
		resets = <0x02 0x2b 0x02 0x2f>;
		reset-names = "rst_isp", "rst_mipicsiphy";
		power-domains = <0x91 0x0d>;
		pinctrl-names = "default", "isp_dvp8bit2", "isp_dvp10bit", "isp_dvp12bit";
		pinctrl-0 = <0xb2>;
		pinctrl-1 = <0xb0>;
		pinctrl-2 = <0xb0 0xb3>;
		pinctrl-3 = <0xb4 0xb0 0xb3>;
		rockchip,isp,mipiphy = <0x01>;
		rockchip,isp,csiphy,reg = <0xff2f0000 0x4000>;
		rockchip,grf = <0x31>;
		rockchip,cru = <0x02>;
		rockchip,isp,iommu-enable = <0x01>;
		iommus = <0xb5>;
		status = "disabled";
		phandle = <0x137>;
	};

	rkisp1: rkisp1@ff4a0000 {
		compatible = "rockchip,rk3326-rkisp1";
		reg = <0x00 0xff4a0000 0x00 0x8000>;
		interrupts = <0x00 0x46 0x04 0x00 0x49 0x04 0x00 0x4a 0x04>;
		interrupt-names = "isp_irq", "mi_irq", "mipi_irq";
		clocks = <0x02 0xb4 0x02 0xfa 0x02 0x33 0x02 0x15f>;
		clock-names = "aclk_isp", "hclk_isp", "clk_isp", "pclk_isp";
		devfreq = <0xb6>;
		power-domains = <0x91 0x0d>;
		iommus = <0xb5>;
		rockchip,grf = <0x31>;
		status = "okay";
		phandle = <0x138>;

		port {
			#address-cells = <0x01>;
			#size-cells = <0x00>;

			isp_mipi_in: endpoint@0 {
				reg = <0x00>;
				remote-endpoint = <0xb7>;
				phandle = <0x93>;
			};
		};
	};

	isp_mmu: iommu@ff4a8000 {
		compatible = "rockchip,iommu";
		reg = <0x00 0xff4a8000 0x00 0x100>;
		interrupts = <0x00 0x46 0x04>;
		interrupt-names = "isp_mmu";
		clocks = <0x02 0xb4 0x02 0xfa>;
		clock-names = "aclk", "iface";
		power-domains = <0x91 0x0d>;
		rk_iommu,disable_reset_quirk;
		#iommu-cells = <0x00>;
		status = "okay";
		phandle = <0xb5>;
	};

	qos_gmac: qos@ff518000 {
		compatible = "syscon";
		reg = <0x00 0xff518000 0x00 0x20>;
		phandle = <0x1a>;
	};

	qos_gpu: qos@ff520000 {
		compatible = "syscon";
		reg = <0x00 0xff520000 0x00 0x20>;
		phandle = <0x2a>;
	};

	qos_sdmmc: qos@ff52c000 {
		compatible = "syscon";
		reg = <0x00 0xff52c000 0x00 0x20>;
		phandle = <0x19>;
	};

	qos_emmc: qos@ff538000 {
		compatible = "syscon";
		reg = <0x00 0xff538000 0x00 0x20>;
		phandle = <0x1b>;
	};

	qos_nand: qos@ff538080 {
		compatible = "syscon";
		reg = <0x00 0xff538080 0x00 0x20>;
		phandle = <0x1c>;
	};

	qos_sdio: qos@ff538100 {
		compatible = "syscon";
		reg = <0x00 0xff538100 0x00 0x20>;
		phandle = <0x1d>;
	};

	qos_sfc: qos@ff538180 {
		compatible = "syscon";
		reg = <0x00 0xff538180 0x00 0x20>;
		phandle = <0x1e>;
	};

	qos_usb_host: qos@ff540000 {
		compatible = "syscon";
		reg = <0x00 0xff540000 0x00 0x20>;
		phandle = <0x17>;
	};

	qos_usb_otg: qos@ff540080 {
		compatible = "syscon";
		reg = <0x00 0xff540080 0x00 0x20>;
		phandle = <0x18>;
	};

	qos_isp_128: qos@ff548000 {
		compatible = "syscon";
		reg = <0x00 0xff548000 0x00 0x20>;
		phandle = <0x25>;
	};

	qos_isp_rd: qos@ff548080 {
		compatible = "syscon";
		reg = <0x00 0xff548080 0x00 0x20>;
		phandle = <0x26>;
	};

	qos_isp_wr: qos@ff548100 {
		compatible = "syscon";
		reg = <0x00 0xff548100 0x00 0x20>;
		phandle = <0x27>;
	};

	qos_isp_m1: qos@ff548180 {
		compatible = "syscon";
		reg = <0x00 0xff548180 0x00 0x20>;
		phandle = <0x28>;
	};

	qos_vip: qos@ff548200 {
		compatible = "syscon";
		reg = <0x00 0xff548200 0x00 0x20>;
		phandle = <0x29>;
	};

	qos_rga_rd: qos@ff550000 {
		compatible = "syscon";
		reg = <0x00 0xff550000 0x00 0x20>;
		phandle = <0x21>;
	};

	qos_rga_wr: qos@ff550080 {
		compatible = "syscon";
		reg = <0x00 0xff550080 0x00 0x20>;
		phandle = <0x22>;
	};

	qos_vop_m0: qos@ff550100 {
		compatible = "syscon";
		reg = <0x00 0xff550100 0x00 0x20>;
		phandle = <0x23>;
	};

	qos_vop_m1: qos@ff550180 {
		compatible = "syscon";
		reg = <0x00 0xff550180 0x00 0x20>;
		phandle = <0x24>;
	};

	qos_vpu: qos@ff558000 {
		compatible = "syscon";
		reg = <0x00 0xff558000 0x00 0x20>;
		phandle = <0x1f>;
	};

	qos_vpu_r128: qos@ff558080 {
		compatible = "syscon";
		reg = <0x00 0xff558080 0x00 0x20>;
		phandle = <0x20>;
	};

	dfi: dfi@ff610000 {
		reg = <0x00 0xff610000 0x00 0x400>;
		compatible = "rockchip,px30-dfi";
		rockchip,pmugrf = <0xb8>;
		status = "okay";
		phandle = <0xb9>;
	};

	dmc: dmc {
		compatible = "rockchip,px30-dmc";
		interrupts = <0x00 0x69 0x04>;
		interrupt-names = "complete_irq";
		devfreq-events = <0xb9>;
		clocks = <0x02 0x54>;
		clock-names = "dmc_clk";
		operating-points-v2 = <0xba>;
		ddr_timing = <0xbb>;
		upthreshold = <0x28>;
		downdifferential = <0x14>;
		system-status-freq = <0x01 0xa2990 0x08 0x6ddd0 0x02 0x2f5d0 0x20 0x80e80 0x1000 0x80e80 0x4000 0xa2990 0x2000 0xa2990>;
		auto-min-freq = <0x50140>;
		auto-freq-en = <0x01>;
		#cooling-cells = <0x02>;
		status = "okay";
		center-supply = <0x0e>;
		phandle = <0xb6>;

		ddr_power_model: ddr_power_model {
			compatible = "ddr_power_model";
			dynamic-power-coefficient = <0x78>;
			static-power-coefficient = <0xc8>;
			ts = <0x7d00 0x125c 0xffffffb0 0x02>;
			thermal-zone = "soc-thermal";
			phandle = <0x139>;
		};
	};

	dmc_fsp: dmc-fsp {
		compatible = "rockchip,px30s-dmc-fsp";
		debug_print_level = <0x00>;
		phy_de_skew_en = <0x01>;
		ddr3_params = <0xbc>;
		ddr4_params = <0xbd>;
		lpddr2_params = <0xbe>;
		lpddr3_params = <0xbf>;
		lpddr4_params = <0xc0>;
		ddr_timing = <0xbb>;
		status = "okay";
		phandle = <0x13a>;
	};

	dmc_opp_table: dmc-opp-table {
		compatible = "operating-points-v2";
		rockchip,max-volt = <0x118c30>;
		rockchip,evb-irdrop = <0x61a8>;
		rockchip,pvtm-voltage-sel = <0x00 0xc350 0x00 0xc351 0xd2f0 0x01 0xd2f1 0xea60 0x02 0xea61 0x1869f 0x03>;
		rockchip,pvtm-ch = <0x00 0x00>;
		rockchip,board-irdrop = <0x1c3 0x320 0x124f8>;
		phandle = <0xba>;

		opp-194000000 {
			opp-hz = <0x00 0xb903480>;
			opp-microvolt = <0xe7ef0>;
			opp-microvolt-L0 = <0xe7ef0>;
			opp-microvolt-L1 = <0xe7ef0>;
			opp-microvolt-L2 = <0xe7ef0>;
			opp-microvolt-L3 = <0xe7ef0>;
			status = "disabled";
		};

		opp-328000000 {
			opp-hz = <0x00 0x138ce200>;
			opp-microvolt = <0xe7ef0>;
			opp-microvolt-L0 = <0xe7ef0>;
			opp-microvolt-L1 = <0xe7ef0>;
			opp-microvolt-L2 = <0xe7ef0>;
			opp-microvolt-L3 = <0xe7ef0>;
		};

		opp-450000000 {
			opp-hz = <0x00 0x1ad27480>;
			opp-microvolt = <0xe7ef0>;
			opp-microvolt-L0 = <0xe7ef0>;
			opp-microvolt-L1 = <0xe7ef0>;
			opp-microvolt-L2 = <0xe7ef0>;
			opp-microvolt-L3 = <0xe7ef0>;
		};

		opp-528000000 {
			opp-hz = <0x00 0x1f78a400>;
			opp-microvolt = <0xee098>;
			opp-microvolt-L0 = <0xee098>;
			opp-microvolt-L1 = <0xee098>;
			opp-microvolt-L2 = <0xe7ef0>;
			opp-microvolt-L3 = <0xe7ef0>;
		};

		opp-666000000 {
			opp-hz = <0x00 0x27b25a80>;
			opp-microvolt = <0x100590>;
			opp-microvolt-L0 = <0x100590>;
			opp-microvolt-L1 = <0xf4240>;
			opp-microvolt-L2 = <0xee098>;
			opp-microvolt-L3 = <0xe7ef0>;
		};

		opp-786000000 {
			opp-hz = <0x00 0x2ed96880>;
			opp-microvolt = <0x10c8e0>;
			opp-microvolt-L0 = <0x10c8e0>;
			opp-microvolt-L1 = <0x100590>;
			opp-microvolt-L2 = <0xfa3e8>;
			opp-microvolt-L3 = <0xf4240>;
			status = "disabled";
		};
	};

	px30s_dmc_opp_table: px30s-dmc-opp-table {
		compatible = "operating-points-v2";
		phandle = <0x13b>;

		opp-328000000 {
			opp-hz = <0x00 0x138ce200>;
			opp-microvolt = <0xf4240>;
		};

		opp-666000000 {
			opp-hz = <0x00 0x27b25a80>;
			opp-microvolt = <0xf4240>;
		};

		opp-786000000 {
			opp-hz = <0x00 0x2ed96880>;
			opp-microvolt = <0xf4240>;
		};

		opp-924000000 {
			opp-hz = <0x00 0x37131f00>;
			opp-microvolt = <0xf4240>;
			status = "disabled";
		};

		opp-1056000000 {
			opp-hz = <0x00 0x3ef14800>;
			opp-microvolt = <0xf4240>;
			status = "disabled";
		};
	};

	dmcdbg: dmcdbg {
		compatible = "rockchip,px30-dmcdbg";
		status = "okay";
		phandle = <0x13c>;
	};

	rockchip_system_monitor: rockchip-system-monitor {
		compatible = "rockchip,system-monitor";
		rockchip,thermal-zone = "soc-thermal";
		rockchip,polling-delay = <0xc8>;
		phandle = <0x13d>;
	};

	pinctrl: pinctrl {
		compatible = "rockchip,px30-pinctrl";
		rockchip,grf = <0x31>;
		rockchip,pmu = <0xb8>;
		#address-cells = <0x02>;
		#size-cells = <0x02>;
		ranges;
		phandle = <0x13e>;

		gpio0: gpio0@ff040000 {
			compatible = "rockchip,gpio-bank";
			reg = <0x00 0xff040000 0x00 0x100>;
			interrupts = <0x00 0x03 0x04>;
			clocks = <0x2c 0x14>;
			gpio-controller;
			#gpio-cells = <0x02>;
			interrupt-controller;
			#interrupt-cells = <0x02>;
			phandle = <0x62>;
		};

		gpio1: gpio1@ff250000 {
			compatible = "rockchip,gpio-bank";
			reg = <0x00 0xff250000 0x00 0x100>;
			interrupts = <0x00 0x04 0x04>;
			clocks = <0x02 0x15c>;
			gpio-controller;
			#gpio-cells = <0x02>;
			interrupt-controller;
			#interrupt-cells = <0x02>;
			phandle = <0xdb>;
		};

		gpio2: gpio2@ff260000 {
			compatible = "rockchip,gpio-bank";
			reg = <0x00 0xff260000 0x00 0x100>;
			interrupts = <0x00 0x05 0x04>;
			clocks = <0x02 0x15d>;
			gpio-controller;
			#gpio-cells = <0x02>;
			interrupt-controller;
			#interrupt-cells = <0x02>;
			phandle = <0xcd>;
		};

		gpio3: gpio3@ff270000 {
			compatible = "rockchip,gpio-bank";
			reg = <0x00 0xff270000 0x00 0x100>;
			interrupts = <0x00 0x06 0x04>;
			clocks = <0x02 0x15e>;
			gpio-controller;
			#gpio-cells = <0x02>;
			interrupt-controller;
			#interrupt-cells = <0x02>;
			phandle = <0x6e>;
		};

		pcfg_pull_up: pcfg-pull-up {
			bias-pull-up;
			phandle = <0xc3>;
		};

		pcfg_pull_down: pcfg-pull-down {
			bias-pull-down;
			phandle = <0x13f>;
		};

		pcfg_pull_none: pcfg-pull-none {
			bias-disable;
			phandle = <0xc2>;
		};

		pcfg_pull_none_2ma: pcfg-pull-none-2ma {
			bias-disable;
			drive-strength = <0x02>;
			phandle = <0x140>;
		};

		pcfg_pull_up_2ma: pcfg-pull-up-2ma {
			bias-pull-up;
			drive-strength = <0x02>;
			phandle = <0x141>;
		};

		pcfg_pull_up_4ma: pcfg-pull-up-4ma {
			bias-pull-up;
			drive-strength = <0x04>;
			phandle = <0xc4>;
		};

		pcfg_pull_none_4ma: pcfg-pull-none-4ma {
			bias-disable;
			drive-strength = <0x04>;
			phandle = <0x142>;
		};

		pcfg_pull_down_4ma: pcfg-pull-down-4ma {
			bias-pull-down;
			drive-strength = <0x04>;
			phandle = <0x143>;
		};

		pcfg_pull_none_8ma: pcfg-pull-none-8ma {
			bias-disable;
			drive-strength = <0x08>;
			phandle = <0xc7>;
		};

		pcfg_pull_up_8ma: pcfg-pull-up-8ma {
			bias-pull-up;
			drive-strength = <0x08>;
			phandle = <0xc5>;
		};

		pcfg_pull_none_12ma: pcfg-pull-none-12ma {
			bias-disable;
			drive-strength = <0x0c>;
			phandle = <0xcb>;
		};

		pcfg_pull_up_12ma: pcfg-pull-up-12ma {
			bias-pull-up;
			drive-strength = <0x0c>;
			phandle = <0xca>;
		};

		pcfg_pull_none_smt: pcfg-pull-none-smt {
			bias-disable;
			input-schmitt-enable;
			phandle = <0xc1>;
		};

		pcfg_output_high: pcfg-output-high {
			output-high;
			phandle = <0x144>;
		};

		pcfg_output_low: pcfg-output-low {
			output-low;
			phandle = <0xcc>;
		};

		pcfg_input_high: pcfg-input-high {
			bias-pull-up;
			input-enable;
			phandle = <0xc6>;
		};

		pcfg_input: pcfg-input {
			input-enable;
			phandle = <0x145>;
		};

		i2c0 {

			i2c0_xfer: i2c0-xfer {
				rockchip,pins = <0x00 0x08 0x01 0xc1 0x00 0x09 0x01 0xc1>;
				phandle = <0x61>;
			};
		};

		i2c1 {

			i2c1_xfer: i2c1-xfer {
				rockchip,pins = <0x00 0x12 0x01 0xc1 0x00 0x13 0x01 0xc1>;
				phandle = <0x6f>;
			};
		};

		i2c2 {

			i2c2_xfer: i2c2-xfer {
				rockchip,pins = <0x02 0x0f 0x02 0xc1 0x02 0x10 0x02 0xc1>;
				phandle = <0x71>;
			};
		};

		i2c3 {

			i2c3_xfer: i2c3-xfer {
				rockchip,pins = <0x01 0x0c 0x04 0xc1 0x01 0x0d 0x04 0xc1>;
				phandle = <0x72>;
			};
		};

		tsadc {

			tsadc_otp_gpio: tsadc-otp-gpio {
				rockchip,pins = <0x00 0x06 0x00 0xc2>;
				phandle = <0x8d>;
			};

			tsadc_otp_out: tsadc-otp-out {
				rockchip,pins = <0x00 0x06 0x01 0xc2>;
				phandle = <0x8e>;
			};
		};

		uart0 {

			uart0_xfer: uart0-xfer {
				rockchip,pins = <0x00 0x0a 0x01 0xc3 0x00 0x0b 0x01 0xc3>;
				phandle = <0x2e>;
			};

			uart0_cts: uart0-cts {
				rockchip,pins = <0x00 0x0c 0x01 0xc2>;
				phandle = <0x2f>;
			};

			uart0_rts: uart0-rts {
				rockchip,pins = <0x00 0x0d 0x01 0xc2>;
				phandle = <0x30>;
			};

			uart0_rts_gpio: uart0-rts-gpio {
				rockchip,pins = <0x00 0x0d 0x00 0xc2>;
				phandle = <0x146>;
			};
		};

		uart1 {

			uart1_xfer: uart1-xfer {
				rockchip,pins = <0x01 0x11 0x01 0xc3 0x01 0x10 0x01 0xc3>;
				phandle = <0x55>;
			};

			uart1_cts: uart1-cts {
				rockchip,pins = <0x01 0x12 0x01 0xc2>;
				phandle = <0x56>;
			};

			uart1_rts: uart1-rts {
				rockchip,pins = <0x01 0x13 0x01 0xc2>;
				phandle = <0xdc>;
			};

			uart1_rts_gpio: uart1-rts-gpio {
				rockchip,pins = <0x01 0x13 0x00 0xc2>;
				phandle = <0xde>;
			};
		};

		uart2-m0 {

			uart2m0_xfer: uart2m0-xfer {
				rockchip,pins = <0x01 0x1a 0x02 0xc3 0x01 0x1b 0x02 0xc3>;
				phandle = <0x57>;
			};
		};

		uart2-m1 {

			uart2m1_xfer: uart2m1-xfer {
				rockchip,pins = <0x02 0x0c 0x02 0xc3 0x02 0x0e 0x02 0xc3>;
				phandle = <0x147>;
			};
		};

		uart3-m0 {

			uart3m0_xfer: uart3m0-xfer {
				rockchip,pins = <0x00 0x10 0x02 0xc3 0x00 0x11 0x02 0xc3>;
				phandle = <0x148>;
			};

			uart3m0_cts: uart3m0-cts {
				rockchip,pins = <0x00 0x12 0x02 0xc2>;
				phandle = <0x149>;
			};

			uart3m0_rts: uart3m0-rts {
				rockchip,pins = <0x00 0x13 0x02 0xc2>;
				phandle = <0x14a>;
			};

			uart3m0_rts_gpio: uart3m0-rts-gpio {
				rockchip,pins = <0x00 0x13 0x00 0xc2>;
				phandle = <0x14b>;
			};
		};

		uart3-m1 {

			uart3m1_xfer: uart3m1-xfer {
				rockchip,pins = <0x01 0x0e 0x02 0xc3 0x01 0x0f 0x02 0xc3>;
				phandle = <0x58>;
			};

			uart3m1_cts: uart3m1-cts {
				rockchip,pins = <0x01 0x0c 0x02 0xc2>;
				phandle = <0x59>;
			};

			uart3m1_rts: uart3m1-rts {
				rockchip,pins = <0x01 0x0d 0x02 0xc2>;
				phandle = <0x5a>;
			};

			uart3m1_rts_gpio: uart3m1-rts-gpio {
				rockchip,pins = <0x01 0x0d 0x00 0xc2>;
				phandle = <0x14c>;
			};
		};

		uart4 {

			uart4_xfer: uart4-xfer {
				rockchip,pins = <0x01 0x1c 0x02 0xc3 0x01 0x1d 0x02 0xc3>;
				phandle = <0x5b>;
			};

			uart4_cts: uart4-cts {
				rockchip,pins = <0x01 0x1e 0x02 0xc2>;
				phandle = <0x5c>;
			};

			uart4_rts: uart4-rts {
				rockchip,pins = <0x01 0x1f 0x02 0xc2>;
				phandle = <0x5d>;
			};
		};

		uart5 {

			uart5_xfer: uart5-xfer {
				rockchip,pins = <0x03 0x02 0x04 0xc3 0x03 0x01 0x04 0xc3>;
				phandle = <0x5e>;
			};

			uart5_cts: uart5-cts {
				rockchip,pins = <0x03 0x03 0x04 0xc2>;
				phandle = <0x5f>;
			};

			uart5_rts: uart5-rts {
				rockchip,pins = <0x03 0x05 0x04 0xc2>;
				phandle = <0x60>;
			};
		};

		spi0 {

			spi0_clk: spi0-clk {
				rockchip,pins = <0x01 0x0f 0x03 0xc4>;
				phandle = <0x73>;
			};

			spi0_csn: spi0-csn {
				rockchip,pins = <0x01 0x0e 0x03 0xc4>;
				phandle = <0x74>;
			};

			spi0_miso: spi0-miso {
				rockchip,pins = <0x01 0x0d 0x03 0xc4>;
				phandle = <0x75>;
			};

			spi0_mosi: spi0-mosi {
				rockchip,pins = <0x01 0x0c 0x03 0xc4>;
				phandle = <0x76>;
			};

			spi0_clk_hs: spi0-clk-hs {
				rockchip,pins = <0x01 0x0f 0x03 0xc5>;
				phandle = <0x77>;
			};

			spi0_miso_hs: spi0-miso-hs {
				rockchip,pins = <0x01 0x0d 0x03 0xc5>;
				phandle = <0x78>;
			};

			spi0_mosi_hs: spi0-mosi-hs {
				rockchip,pins = <0x01 0x0c 0x03 0xc5>;
				phandle = <0x79>;
			};
		};

		spi1 {

			spi1_clk: spi1-clk {
				rockchip,pins = <0x03 0x0f 0x04 0xc4>;
				phandle = <0x7a>;
			};

			spi1_csn0: spi1-csn0 {
				rockchip,pins = <0x03 0x09 0x04 0xc4>;
				phandle = <0x7b>;
			};

			spi1_csn1: spi1-csn1 {
				rockchip,pins = <0x03 0x0a 0x02 0xc4>;
				phandle = <0x7c>;
			};

			spi1_miso: spi1-miso {
				rockchip,pins = <0x03 0x0e 0x04 0xc4>;
				phandle = <0x7d>;
			};

			spi1_mosi: spi1-mosi {
				rockchip,pins = <0x03 0x0c 0x04 0xc4>;
				phandle = <0x7e>;
			};

			spi1_clk_hs: spi1-clk-hs {
				rockchip,pins = <0x03 0x0f 0x04 0xc5>;
				phandle = <0x7f>;
			};

			spi1_miso_hs: spi1-miso-hs {
				rockchip,pins = <0x03 0x0e 0x04 0xc5>;
				phandle = <0x80>;
			};

			spi1_mosi_hs: spi1-mosi-hs {
				rockchip,pins = <0x03 0x0c 0x04 0xc5>;
				phandle = <0x81>;
			};
		};

		pdm {

			pdm_clk0m0: pdm-clk0m0 {
				rockchip,pins = <0x03 0x16 0x02 0xc2>;
				phandle = <0x46>;
			};

			pdm_clk0m1: pdm-clk0m1 {
				rockchip,pins = <0x02 0x16 0x01 0xc2>;
				phandle = <0x14d>;
			};

			pdm_clk1: pdm-clk1 {
				rockchip,pins = <0x03 0x17 0x02 0xc2>;
				phandle = <0x47>;
			};

			pdm_sdi0m0: pdm-sdi0m0 {
				rockchip,pins = <0x03 0x1b 0x02 0xc2>;
				phandle = <0x48>;
			};

			pdm_sdi0m1: pdm-sdi0m1 {
				rockchip,pins = <0x02 0x15 0x02 0xc2>;
				phandle = <0x14e>;
			};

			pdm_sdi1: pdm-sdi1 {
				rockchip,pins = <0x03 0x18 0x02 0xc2>;
				phandle = <0x49>;
			};

			pdm_sdi2: pdm-sdi2 {
				rockchip,pins = <0x03 0x19 0x02 0xc2>;
				phandle = <0x4a>;
			};

			pdm_sdi3: pdm-sdi3 {
				rockchip,pins = <0x03 0x1a 0x02 0xc2>;
				phandle = <0x4b>;
			};

			pdm_clk0m0_sleep: pdm-clk0m0-sleep {
				rockchip,pins = <0x03 0x16 0x00 0xc6>;
				phandle = <0x14f>;
			};

			pdm_clk0m_sleep1: pdm-clk0m1-sleep {
				rockchip,pins = <0x02 0x16 0x00 0xc6>;
				phandle = <0x150>;
			};

			pdm_clk1_sleep: pdm-clk1-sleep {
				rockchip,pins = <0x03 0x17 0x00 0xc6>;
				phandle = <0x151>;
			};

			pdm_sdi0m0_sleep: pdm-sdi0m0-sleep {
				rockchip,pins = <0x03 0x1b 0x00 0xc6>;
				phandle = <0x152>;
			};

			pdm_sdi0m1_sleep: pdm-sdi0m1-sleep {
				rockchip,pins = <0x02 0x15 0x00 0xc6>;
				phandle = <0x153>;
			};

			pdm_sdi1_sleep: pdm-sdi1-sleep {
				rockchip,pins = <0x03 0x18 0x00 0xc6>;
				phandle = <0x154>;
			};

			pdm_sdi2_sleep: pdm-sdi2-sleep {
				rockchip,pins = <0x03 0x19 0x00 0xc6>;
				phandle = <0x155>;
			};

			pdm_sdi3_sleep: pdm-sdi3-sleep {
				rockchip,pins = <0x03 0x1a 0x00 0xc6>;
				phandle = <0x156>;
			};
		};

		i2s0 {

			i2s0_8ch_mclk: i2s0-8ch-mclk {
				rockchip,pins = <0x03 0x11 0x02 0xc2>;
				phandle = <0x157>;
			};

			i2s0_8ch_sclktx: i2s0-8ch-sclktx {
				rockchip,pins = <0x03 0x13 0x02 0xc2>;
				phandle = <0x32>;
			};

			i2s0_8ch_sclkrx: i2s0-8ch-sclkrx {
				rockchip,pins = <0x03 0x0c 0x02 0xc2>;
				phandle = <0x33>;
			};

			i2s0_8ch_lrcktx: i2s0-8ch-lrcktx {
				rockchip,pins = <0x03 0x12 0x02 0xc2>;
				phandle = <0x34>;
			};

			i2s0_8ch_lrckrx: i2s0-8ch-lrckrx {
				rockchip,pins = <0x03 0x0d 0x02 0xc2>;
				phandle = <0x35>;
			};

			i2s0_8ch_sdo0: i2s0-8ch-sdo0 {
				rockchip,pins = <0x03 0x14 0x02 0xc2>;
				phandle = <0x3a>;
			};

			i2s0_8ch_sdo1: i2s0-8ch-sdo1 {
				rockchip,pins = <0x03 0x10 0x02 0xc2>;
				phandle = <0x3b>;
			};

			i2s0_8ch_sdo2: i2s0-8ch-sdo2 {
				rockchip,pins = <0x03 0x0f 0x02 0xc2>;
				phandle = <0x3c>;
			};

			i2s0_8ch_sdo3: i2s0-8ch-sdo3 {
				rockchip,pins = <0x03 0x0e 0x02 0xc2>;
				phandle = <0x3d>;
			};

			i2s0_8ch_sdi0: i2s0-8ch-sdi0 {
				rockchip,pins = <0x03 0x15 0x02 0xc2>;
				phandle = <0x36>;
			};

			i2s0_8ch_sdi1: i2s0-8ch-sdi1 {
				rockchip,pins = <0x03 0x0b 0x02 0xc2>;
				phandle = <0x37>;
			};

			i2s0_8ch_sdi2: i2s0-8ch-sdi2 {
				rockchip,pins = <0x03 0x09 0x02 0xc2>;
				phandle = <0x38>;
			};

			i2s0_8ch_sdi3: i2s0-8ch-sdi3 {
				rockchip,pins = <0x03 0x08 0x02 0xc2>;
				phandle = <0x39>;
			};
		};

		i2s1 {

			i2s1_2ch_mclk: i2s1-2ch-mclk {
				rockchip,pins = <0x02 0x13 0x01 0xc2>;
				phandle = <0x6d>;
			};

			i2s1_2ch_sclk: i2s1-2ch-sclk {
				rockchip,pins = <0x02 0x12 0x01 0xc2>;
				phandle = <0x3e>;
			};

			i2s1_2ch_lrck: i2s1-2ch-lrck {
				rockchip,pins = <0x02 0x11 0x01 0xc2>;
				phandle = <0x3f>;
			};

			i2s1_2ch_sdi: i2s1-2ch-sdi {
				rockchip,pins = <0x02 0x15 0x01 0xc2>;
				phandle = <0x40>;
			};

			i2s1_2ch_sdo: i2s1-2ch-sdo {
				rockchip,pins = <0x02 0x14 0x01 0xc2>;
				phandle = <0x41>;
			};
		};

		i2s2 {

			i2s2_2ch_mclk: i2s2-2ch-mclk {
				rockchip,pins = <0x03 0x01 0x02 0xc2>;
				phandle = <0x158>;
			};

			i2s2_2ch_sclk: i2s2-2ch-sclk {
				rockchip,pins = <0x03 0x02 0x02 0xc2>;
				phandle = <0x42>;
			};

			i2s2_2ch_lrck: i2s2-2ch-lrck {
				rockchip,pins = <0x03 0x03 0x02 0xc2>;
				phandle = <0x43>;
			};

			i2s2_2ch_sdi: i2s2-2ch-sdi {
				rockchip,pins = <0x03 0x05 0x02 0xc2>;
				phandle = <0x44>;
			};

			i2s2_2ch_sdo: i2s2-2ch-sdo {
				rockchip,pins = <0x03 0x07 0x02 0xc2>;
				phandle = <0x45>;
			};
		};

		sdmmc {

			sdmmc_clk: sdmmc-clk {
				rockchip,pins = <0x01 0x1e 0x01 0xc7>;
				phandle = <0x98>;
			};

			sdmmc_cmd: sdmmc-cmd {
				rockchip,pins = <0x01 0x1f 0x01 0xc5>;
				phandle = <0x99>;
			};

			sdmmc_det: sdmmc-det {
				rockchip,pins = <0x00 0x03 0x01 0xc5>;
				phandle = <0x9a>;
			};

			sdmmc_bus1: sdmmc-bus1 {
				rockchip,pins = <0x01 0x1a 0x01 0xc5>;
				phandle = <0x159>;
			};

			sdmmc_bus4: sdmmc-bus4 {
				rockchip,pins = <0x01 0x1a 0x01 0xc5 0x01 0x1b 0x01 0xc5 0x01 0x1c 0x01 0xc5 0x01 0x1d 0x01 0xc5>;
				phandle = <0x9b>;
			};

			sdmmc_gpio: sdmmc-gpio {
				rockchip,pins = <0x01 0x1a 0x00 0xc4 0x01 0x1b 0x00 0xc4 0x01 0x1c 0x00 0xc4 0x01 0x1d 0x00 0xc4 0x01 0x1e 0x00 0xc4 0x01 0x1f 0x00 0xc4>;
				phandle = <0x15a>;
			};
		};

		sdio {

			sdio_clk: sdio-clk {
				rockchip,pins = <0x01 0x15 0x01 0xc2>;
				phandle = <0x9f>;
			};

			sdio_cmd: sdio-cmd {
				rockchip,pins = <0x01 0x14 0x01 0xc3>;
				phandle = <0x9e>;
			};

			sdio_bus4: sdio-bus4 {
				rockchip,pins = <0x01 0x16 0x01 0xc3 0x01 0x17 0x01 0xc3 0x01 0x18 0x01 0xc3 0x01 0x19 0x01 0xc3>;
				phandle = <0x9d>;
			};

			sdio_gpio: sdio-gpio {
				rockchip,pins = <0x01 0x16 0x00 0xc3 0x01 0x17 0x00 0xc3 0x01 0x18 0x00 0xc3 0x01 0x19 0x00 0xc3 0x01 0x14 0x00 0xc3 0x01 0x15 0x00 0xc3>;
				phandle = <0x15b>;
			};
		};

		emmc {

			emmc_clk: emmc-clk {
				rockchip,pins = <0x01 0x09 0x02 0xc8>;
				phandle = <0x15c>;
			};

			emmc_cmd: emmc-cmd {
				rockchip,pins = <0x01 0x0a 0x02 0xc9>;
				phandle = <0x15d>;
			};

			emmc_pwren: emmc-pwren {
				rockchip,pins = <0x01 0x08 0x02 0xc2>;
				phandle = <0x15e>;
			};

			emmc_rstnout: emmc-rstnout {
				rockchip,pins = <0x01 0x0b 0x02 0xc2>;
				phandle = <0x15f>;
			};

			emmc_bus1: emmc-bus1 {
				rockchip,pins = <0x01 0x00 0x02 0xc9>;
				phandle = <0x160>;
			};

			emmc_bus4: emmc-bus4 {
				rockchip,pins = <0x01 0x00 0x02 0xc9 0x01 0x01 0x02 0xc9 0x01 0x02 0x02 0xc9 0x01 0x03 0x02 0xc9>;
				phandle = <0x161>;
			};

			emmc_bus8: emmc-bus8 {
				rockchip,pins = <0x01 0x00 0x02 0xc9 0x01 0x01 0x02 0xc9 0x01 0x02 0x02 0xc9 0x01 0x03 0x02 0xc9 0x01 0x04 0x02 0xc9 0x01 0x05 0x02 0xc9 0x01 0x06 0x02 0xc9 0x01 0x07 0x02 0xc9>;
				phandle = <0x162>;
			};
		};

		flash {

			flash_cs0: flash-cs0 {
				rockchip,pins = <0x01 0x08 0x01 0xc2>;
				phandle = <0x163>;
			};

			flash_rdy: flash-rdy {
				rockchip,pins = <0x01 0x09 0x01 0xc2>;
				phandle = <0x164>;
			};

			flash_dqs: flash-dqs {
				rockchip,pins = <0x01 0x0a 0x01 0xc2>;
				phandle = <0x165>;
			};

			flash_ale: flash-ale {
				rockchip,pins = <0x01 0x0b 0x01 0xc2>;
				phandle = <0x166>;
			};

			flash_cle: flash-cle {
				rockchip,pins = <0x01 0x0c 0x01 0xc2>;
				phandle = <0x167>;
			};

			flash_wrn: flash-wrn {
				rockchip,pins = <0x01 0x0d 0x01 0xc2>;
				phandle = <0x168>;
			};

			flash_csl: flash-csl {
				rockchip,pins = <0x01 0x0e 0x01 0xc2>;
				phandle = <0x169>;
			};

			flash_rdn: flash-rdn {
				rockchip,pins = <0x01 0x0f 0x01 0xc2>;
				phandle = <0x16a>;
			};

			flash_bus8: flash-bus8 {
				rockchip,pins = <0x01 0x00 0x01 0xca 0x01 0x01 0x01 0xca 0x01 0x02 0x01 0xca 0x01 0x03 0x01 0xca 0x01 0x04 0x01 0xca 0x01 0x05 0x01 0xca 0x01 0x06 0x01 0xca 0x01 0x07 0x01 0xca>;
				phandle = <0x16b>;
			};
		};

		lcdc {

			lcdc_m0_rgb_pins: lcdc-m0-rgb-pins {
				rockchip,pins = <0x03 0x00 0x01 0xc7 0x03 0x01 0x01 0xc7 0x03 0x02 0x01 0xc7 0x03 0x03 0x01 0xc7 0x03 0x04 0x01 0xc7 0x03 0x05 0x01 0xc7 0x03 0x06 0x01 0xc7 0x03 0x07 0x01 0xc7 0x03 0x08 0x01 0xc7 0x03 0x09 0x01 0xc7 0x03 0x0a 0x01 0xc7 0x03 0x0b 0x01 0xc7 0x03 0x0c 0x01 0xc7 0x03 0x0d 0x01 0xc7 0x03 0x0e 0x01 0xc7 0x03 0x0f 0x01 0xc7 0x03 0x10 0x01 0xc7 0x03 0x11 0x01 0xc7 0x03 0x12 0x01 0xc7 0x03 0x13 0x01 0xc7 0x03 0x14 0x01 0xc7 0x03 0x15 0x01 0xc7 0x03 0x16 0x01 0xc7 0x03 0x17 0x01 0xc7 0x03 0x18 0x01 0xc7 0x03 0x19 0x01 0xc7 0x03 0x1a 0x01 0xc7 0x03 0x1b 0x01 0xc7>;
				phandle = <0x16c>;
			};

			lcdc_m0_sleep_pins: lcdc-m0-sleep-pins {
				rockchip,pins = <0x03 0x00 0x00 0xc2 0x03 0x01 0x00 0xc2 0x03 0x02 0x00 0xc2 0x03 0x03 0x00 0xc2 0x03 0x04 0x00 0xc2 0x03 0x05 0x00 0xc2 0x03 0x06 0x00 0xc2 0x03 0x07 0x00 0xc2 0x03 0x08 0x00 0xc2 0x03 0x09 0x00 0xc2 0x03 0x0a 0x00 0xc2 0x03 0x0b 0x00 0xc2 0x03 0x0c 0x00 0xc2 0x03 0x0d 0x00 0xc2 0x03 0x0e 0x00 0xc2 0x03 0x0f 0x00 0xc2 0x03 0x10 0x00 0xc2 0x03 0x11 0x00 0xc2 0x03 0x12 0x00 0xc2 0x03 0x13 0x00 0xc2 0x03 0x14 0x00 0xc2 0x03 0x15 0x00 0xc2 0x03 0x16 0x00 0xc2 0x03 0x17 0x00 0xc2 0x03 0x18 0x00 0xc2 0x03 0x19 0x00 0xc2 0x03 0x1a 0x00 0xc2 0x03 0x1b 0x00 0xc2>;
				phandle = <0x16d>;
			};

			lcdc_m1_rgb_pins: lcdc-m1-rgb-pins {
				rockchip,pins = <0x03 0x00 0x01 0xc7 0x03 0x04 0x01 0xc7 0x03 0x06 0x01 0xc7 0x03 0x0a 0x01 0xc7 0x03 0x0b 0x01 0xc7 0x03 0x0d 0x01 0xc7 0x03 0x10 0x01 0xc7 0x03 0x11 0x01 0xc7 0x03 0x12 0x01 0xc7 0x03 0x13 0x01 0xc7 0x03 0x14 0x01 0xc7 0x03 0x15 0x01 0xc7 0x03 0x16 0x01 0xc7 0x03 0x17 0x01 0xc7 0x03 0x18 0x01 0xc7 0x03 0x19 0x01 0xc7 0x03 0x1a 0x01 0xc7 0x03 0x1b 0x01 0xc7>;
				phandle = <0x52>;
			};

			lcdc_m1_sleep_pins: lcdc-m1-sleep-pins {
				rockchip,pins = <0x03 0x00 0x00 0xc2 0x03 0x04 0x00 0xc2 0x03 0x06 0x00 0xc2 0x03 0x0a 0x00 0xc2 0x03 0x0b 0x00 0xc2 0x03 0x0d 0x00 0xc2 0x03 0x10 0x00 0xc2 0x03 0x11 0x00 0xc2 0x03 0x12 0x00 0xc2 0x03 0x13 0x00 0xc2 0x03 0x14 0x00 0xc2 0x03 0x15 0x00 0xc2 0x03 0x16 0x00 0xc2 0x03 0x17 0x00 0xc2 0x03 0x18 0x00 0xc2 0x03 0x19 0x00 0xc2 0x03 0x1a 0x00 0xc2 0x03 0x1b 0x00 0xc2>;
				phandle = <0x53>;
			};
		};

		pwm0 {

			pwm0_pin: pwm0-pin {
				rockchip,pins = <0x00 0x0f 0x01 0xc2>;
				phandle = <0x82>;
			};
		};

		pwm1 {

			pwm1_pin: pwm1-pin {
				rockchip,pins = <0x00 0x10 0x01 0xc2>;
				phandle = <0x83>;
			};
		};

		pwm2 {

			pwm2_pin: pwm2-pin {
				rockchip,pins = <0x02 0x0d 0x01 0xc2>;
				phandle = <0x84>;
			};
		};

		pwm3 {

			pwm3_pin: pwm3-pin {
				rockchip,pins = <0x00 0x11 0x01 0xc2>;
				phandle = <0x85>;
			};
		};

		pwm4 {

			pwm4_pin: pwm4-pin {
				rockchip,pins = <0x03 0x12 0x03 0xc2>;
				phandle = <0x86>;
			};
		};

		pwm5 {

			pwm5_pin: pwm5-pin {
				rockchip,pins = <0x03 0x13 0x03 0xc2>;
				phandle = <0x87>;
			};
		};

		pwm6 {

			pwm6_pin: pwm6-pin {
				rockchip,pins = <0x03 0x14 0x03 0xc2>;
				phandle = <0x88>;
			};
		};

		pwm7 {

			pwm7_pin: pwm7-pin {
				rockchip,pins = <0x03 0x15 0x03 0xc2>;
				phandle = <0x89>;
			};
		};

		gmac {

			rmii_pins: rmii-pins {
				rockchip,pins = <0x02 0x00 0x02 0xcb 0x02 0x01 0x02 0xcb 0x02 0x02 0x02 0xcb 0x02 0x03 0x02 0xc2 0x02 0x04 0x02 0xc2 0x02 0x05 0x02 0xc2 0x02 0x06 0x02 0xc2 0x02 0x07 0x02 0xc2 0x02 0x09 0x02 0xc2>;
				phandle = <0x96>;
			};

			mac_refclk_12ma: mac-refclk-12ma {
				rockchip,pins = <0x02 0x0a 0x02 0xcb>;
				phandle = <0x97>;
			};

			mac_refclk: mac-refclk {
				rockchip,pins = <0x02 0x0a 0x02 0xc2>;
				phandle = <0x16e>;
			};
		};

		cif-m0 {

			cif_clkout_m0: cif-clkout-m0 {
				rockchip,pins = <0x02 0x0b 0x01 0xcb>;
				phandle = <0xb2>;
			};

			dvp_d2d9_m0: dvp-d2d9-m0 {
				rockchip,pins = <0x02 0x00 0x01 0xc2 0x02 0x01 0x01 0xc2 0x02 0x02 0x01 0xc2 0x02 0x03 0x01 0xc2 0x02 0x04 0x01 0xc2 0x02 0x05 0x01 0xc2 0x02 0x06 0x01 0xc2 0x02 0x07 0x01 0xc2 0x02 0x08 0x01 0xc2 0x02 0x09 0x01 0xc2 0x02 0x0a 0x01 0xc2 0x02 0x0b 0x01 0xc2>;
				phandle = <0xb0>;
			};

			dvp_d0d1_m0: dvp-d0d1-m0 {
				rockchip,pins = <0x02 0x0c 0x01 0xc2 0x02 0x0e 0x01 0xc2>;
				phandle = <0xb4>;
			};

			dvp_d10d11_m0: d10-d11-m0 {
				rockchip,pins = <0x02 0x0f 0x01 0xc2 0x02 0x10 0x01 0xc2>;
				phandle = <0xb3>;
			};
		};

		cif-m1 {

			cif_clkout_m1: cif-clkout-m1 {
				rockchip,pins = <0x03 0x18 0x03 0xc2>;
				phandle = <0x16f>;
			};

			dvp_d2d9_m1: dvp-d2d9-m1 {
				rockchip,pins = <0x03 0x03 0x03 0xc2 0x03 0x05 0x03 0xc2 0x03 0x07 0x03 0xc2 0x03 0x08 0x03 0xc2 0x03 0x09 0x03 0xc2 0x03 0x0c 0x03 0xc2 0x03 0x0e 0x03 0xc2 0x03 0x0f 0x03 0xc2 0x03 0x19 0x03 0xc2 0x03 0x1a 0x03 0xc2 0x03 0x1b 0x03 0xc2 0x03 0x18 0x03 0xc2>;
				phandle = <0x170>;
			};

			dvp_d0d1_m1: dvp-d0d1-m1 {
				rockchip,pins = <0x03 0x01 0x03 0xc2 0x03 0x02 0x03 0xc2>;
				phandle = <0x171>;
			};

			dvp_d10d11_m1: d10-d11-m1 {
				rockchip,pins = <0x03 0x16 0x03 0xc2 0x03 0x17 0x03 0xc2>;
				phandle = <0x172>;
			};
		};

		isp {

			isp_prelight: isp-prelight {
				rockchip,pins = <0x03 0x19 0x04 0xc2>;
				phandle = <0x173>;
			};
		};

		headphone {

			hp_det: hp-det {
				rockchip,pins = <0x02 0x16 0x00 0xc3>;
				phandle = <0xd4>;
			};
		};

		bt_wake_host {

			wake_host_irq: wake_host_irq {
				rockchip,pins = <0x00 0x0b 0x00 0xc3>;
				phandle = <0xdd>;
			};
		};

		pmic {

			pmic_int: pmic_int {
				rockchip,pins = <0x00 0x07 0x00 0xc3>;
				phandle = <0x63>;
			};

			soc_slppin_gpio: soc_slppin_gpio {
				rockchip,pins = <0x00 0x04 0x00 0xcc>;
				phandle = <0x66>;
			};

			soc_slppin_slp: soc_slppin_slp {
				rockchip,pins = <0x00 0x04 0x01 0xc2>;
				phandle = <0x64>;
			};

			soc_slppin_rst: soc_slppin_rst {
				rockchip,pins = <0x00 0x04 0x02 0xc2>;
				phandle = <0x68>;
			};
		};

		sdio-pwrseq {

			wifi_enable_h: wifi-enable-h {
				rockchip,pins = <0x00 0x02 0x00 0xc2>;
				phandle = <0xda>;
			};
		};

		spi_panel {

			spi_init_cmd: spi-init-cmd {
				rockchip,pins = <0x03 0x0c 0x00 0xc2 0x03 0x0f 0x00 0xc2 0x03 0x0a 0x00 0xc2>;
				phandle = <0xd6>;
			};
		};
	};

	pcfg-for-s {

		pcfg_pull_none_n_4ma: pcfg-pull-none-n-4ma {
			bias-disable;
			drive-strength-s = <0x04>;
			phandle = <0x174>;
		};

		pcfg_pull_up_n_4ma: pcfg-pull-up-n-4ma {
			bias-pull-up;
			drive-strength-s = <0x04>;
			phandle = <0x175>;
		};

		pcfg_pull_down_n_4ma: pcfg-pull-down-n-4ma {
			bias-pull-down;
			drive-strength-s = <0x04>;
			phandle = <0x176>;
		};

		pcfg_pull_none_0_6ma: pcfg-pull-none-0-6ma {
			bias-disable;
			drive-strength-s = <0x06>;
			phandle = <0x177>;
		};

		pcfg_pull_up_0_6ma: pcfg-pull-up-0-6ma {
			bias-pull-up;
			drive-strength-s = <0x06>;
			phandle = <0x178>;
		};

		pcfg_pull_down_0_6ma: pcfg-pull-down-0-6ma {
			bias-pull-down;
			drive-strength-s = <0x06>;
			phandle = <0x179>;
		};

		pcfg_pull_none_4_6ma: pcfg-pull-none-4-6ma {
			bias-disable;
			drive-strength = <0x04>;
			drive-strength-s = <0x06>;
			phandle = <0x17a>;
		};

		pcfg_pull_up_4_6ma: pcfg-pull-up-4-6ma {
			bias-pull-up;
			drive-strength = <0x04>;
			drive-strength-s = <0x06>;
			phandle = <0x17b>;
		};

		pcfg_pull_down_4_6ma: pcfg-pull-down-4-6ma {
			bias-pull-down;
			drive-strength = <0x04>;
			drive-strength-s = <0x06>;
			phandle = <0x17c>;
		};

		pcfg_pull_none_8_6ma: pcfg-pull-none-8-6ma {
			bias-disable;
			drive-strength = <0x08>;
			drive-strength-s = <0x06>;
			phandle = <0xc8>;
		};

		pcfg_pull_up_8_6ma: pcfg-pull-up-8-6ma {
			bias-pull-up;
			drive-strength = <0x08>;
			drive-strength-s = <0x06>;
			phandle = <0xc9>;
		};

		pcfg_pull_down_8_6ma: pcfg-pull-down-8-6ma {
			bias-pull-down;
			drive-strength = <0x08>;
			drive-strength-s = <0x06>;
			phandle = <0x17d>;
		};

		pcfg_pull_none_8_4ma: pcfg-pull-none-8-4ma {
			bias-disable;
			drive-strength = <0x08>;
			drive-strength-s = <0x04>;
			phandle = <0x17e>;
		};

		pcfg_pull_up_8_4ma: pcfg-pull-up-8-4ma {
			bias-pull-up;
			drive-strength = <0x08>;
			drive-strength-s = <0x04>;
			phandle = <0x17f>;
		};

		pcfg_pull_down_8_4ma: pcfg-pull-down-8-4ma {
			bias-pull-down;
			drive-strength = <0x08>;
			drive-strength-s = <0x04>;
			phandle = <0x180>;
		};

		pcfg_pull_none_12_4ma: pcfg-pull-none-12-4ma {
			bias-disable;
			drive-strength = <0x0c>;
			drive-strength-s = <0x04>;
			phandle = <0x181>;
		};

		pcfg_pull_up_12_4ma: pcfg-pull-up-12-4ma {
			bias-pull-up;
			drive-strength = <0x0c>;
			drive-strength-s = <0x04>;
			phandle = <0x182>;
		};

		pcfg_pull_down_12_4ma: pcfg-pull-down-12-4ma {
			bias-pull-down;
			drive-strength = <0x0c>;
			drive-strength-s = <0x04>;
			phandle = <0x183>;
		};

		pcfg_pull_none_12_6ma: pcfg-pull-none-12-6ma {
			bias-disable;
			drive-strength = <0x0c>;
			drive-strength-s = <0x06>;
			phandle = <0x184>;
		};

		pcfg_pull_up_12_6ma: pcfg-pull-up-12-6ma {
			bias-pull-up;
			drive-strength = <0x0c>;
			drive-strength-s = <0x06>;
			phandle = <0x185>;
		};

		pcfg_pull_down_12_6ma: pcfg-pull-down-12-6ma {
			bias-pull-down;
			drive-strength = <0x0c>;
			drive-strength-s = <0x06>;
			phandle = <0x186>;
		};
	};

	cif_sensor: cif_sensor {
		compatible = "rockchip,sensor";
		status = "disabled";
		phandle = <0x187>;

		gc2145_b {
			is_front = <0x00>;
			powerdown-gpios = <0xcd 0x0d 0x00>;
			pwdn_active = <0x01>;
			pwr_active = <0x01>;
			rockchip,power_pmu_name1 = "vcc2v8_dvp";
			rockchip,power_pmu_voltage1 = <0x2ab980>;
			rockchip,power_pmu_name2 = "vcc1v8_dvp";
			rockchip,power_pmu_voltage2 = <0x1b7740>;
			mir = <0x00>;
			flash_attach = <0x00>;
			resolution = <0x200000>;
			powerup_sequence = <0x7654>;
			orientation = <0x5a>;
			i2c_add = <0x78>;
			i2c_chl = <0x02>;
			cif_chl = <0x00>;
			mclk_rate = <0x18>;
		};

		gc0312_f {
			is_front = <0x01>;
			powerdown-gpios = <0xcd 0x0e 0x00>;
			pwdn_active = <0x01>;
			pwr_active = <0x01>;
			rockchip,power_pmu_name1 = "vcc2v8_dvp";
			rockchip,power_pmu_voltage1 = <0x2ab980>;
			rockchip,power_pmu_name2 = "vcc1v8_dvp";
			rockchip,power_pmu_voltage2 = <0x1b7740>;
			mir = <0x00>;
			flash_attach = <0x00>;
			resolution = <0x30000>;
			powerup_sequence = <0x7654>;
			orientation = <0x10e>;
			i2c_add = <0x42>;
			i2c_chl = <0x02>;
			cif_chl = <0x00>;
			mclk_rate = <0x18>;
		};
	};

	chosen: chosen {
		bootargs = "earlycon=uart8250,mmio32,0xff160000 console=ttyFIQ0 androidboot.baseband=N/A androidboot.veritymode=enforcing androidboot.hardware=rk30board androidboot.console=ttyFIQ0 init=/init kpti=0";
		phandle = <0x188>;
	};

	fiq-debugger {
		compatible = "rockchip,fiq-debugger";
		rockchip,serial-id = <0x02>;
		rockchip,wake-irq = <0x00>;
		rockchip,irq-mode-enable = <0x00>;
		rockchip,baudrate = <0x16e360>;
		interrupts = <0x00 0x7f 0x08>;
		pinctrl-names = "default";
		pinctrl-0 = <0x57>;
		status = "disabled";
	};

	reserved-memory {
		#address-cells = <0x02>;
		#size-cells = <0x02>;
		ranges;

		drm_logo: drm-logo@00000000 {
			compatible = "rockchip,drm-logo";
			reg = <0x00 0x00 0x00 0x00>;
			phandle = <0x12>;
		};

		ramoops: ramoops@110000 {
			compatible = "ramoops";
			reg = <0x00 0x110000 0x00 0xf0000>;
			record-size = <0x20000>;
			console-size = <0x80000>;
			ftrace-size = <0x00>;
			pmsg-size = <0x50000>;
			phandle = <0x189>;
		};
	};

	adc-keys {
		compatible = "adc-keys";
		io-channels = <0xce 0x02>;
		io-channel-names = "buttons";
		poll-interval = <0x64>;
		keyup-threshold-microvolt = <0x1b7740>;
	};

	key: key {
		compatible = "rockchip,key";
		io-channels = <0xce 0x02>;
		phandle = <0x18a>;

		power-key {
			linux,code = <0x74>;
			label = "KEY_POWER";
			rockchip,adc_value = <0x03>;
			gpio-key,wakeup;
		};
	};

	charge-animation {
		compatible = "rockchip,uboot-charge";
		rockchip,uboot-charge-on = <0x00>;
		rockchip,android-charge-on = <0x00>;
		rockchip,uboot-low-power-voltage = <0xdac>;
		rockchip,screen-on-voltage = <0xe10>;
		status = "disabled";
	};

	motor {
		compatible = "rockchip_stepper_motor";
		gpio_motor_black = <0x6e 0x06 0x00>;
		gpio_motor_yellow = <0x6e 0x07 0x00>;
		gpio_motor_brown = <0x6e 0x08 0x00>;
		gpio_motor_blue = <0x6e 0x09 0x00>;
		gpio_motor_min = <0x6e 0x15 0x00>;
		gpio_motor_max = <0x6e 0x16 0x00>;
		status = "okay";
	};

	rk817-sound {
		compatible = "simple-audio-card";
		simple-audio-card,format = "i2s";
		simple-audio-card,name = "rockchip-rk817-codec";
		simple-audio-card,mclk-fs = <0x100>;
		simple-audio-card,widgets = "Microphone", "Mic Jack", "Headphone", "Headphone Jack";
		simple-audio-card,routing = "Mic Jack", "MICBIAS1", "IN1P", "Mic Jack", "Headphone Jack", "HPOL", "Headphone Jack", "HPOR";

		simple-audio-card,cpu {
			sound-dai = <0xcf>;
		};

		simple-audio-card,codec {
			sound-dai = <0xd0>;
		};
	};

	dummy_codec: dummy-codec {
		compatible = "rockchip,dummy-codec";
		#sound-dai-cells = <0x00>;
		status = "okay";
		phandle = <0xd3>;
	};

	hdmiin-sound {
		compatible = "simple-audio-card";
		simple-audio-card,format = "i2s";
		simple-audio-card,name = "rockchip,hdmiin";
		simple-audio-card,bitclock-master = <0xd1>;
		simple-audio-card,frame-master = <0xd1>;
		status = "okay";

		simple-audio-card,cpu {
			sound-dai = <0xd2>;
		};

		dailink0_master: simple-audio-card,codec {
			sound-dai = <0xd3>;
			phandle = <0xd1>;
		};
	};

	rk_headset: rk-headset {
		compatible = "rockchip_headset";
		status = "okay";
		headset_gpio = <0xcd 0x16 0x01>;
		pinctrl-names = "default";
		pinctrl-0 = <0xd4>;
		phandle = <0x18b>;
	};

	panel: panel {
		compatible = "simple-panel";
		bus-format = <0x1011>;
		power-supply = <0xd5>;
		enable-gpios = <0x6e 0x10 0x00>;
		enable-delay-ms = <0x14>;
		bl-gpios = <0x62 0x00 0x00>;
		red-gpios = <0x62 0x0d 0x00>;
		blue-gpios = <0x6e 0x12 0x00>;
		fan-gpios = <0x62 0x10 0x01>;
		prepare-delay-ms = <0x14>;
		unprepare-delay-ms = <0x14>;
		disable-delay-ms = <0x14>;
		spi-sdi-gpios = <0x6e 0x0c 0x00>;
		spi-scl-gpios = <0x6e 0x0f 0x00>;
		spi-cs-gpios = <0x6e 0x0b 0x00>;
		width-mm = <0xd9>;
		height-mm = <0x88>;
		status = "okay";
		pinctrl-names = "default";
		pinctrl-0 = <0xd6>;
		rockchip,cmd-type = "spi";
		phandle = <0x18c>;

		display-timings {
			native-mode = <0xd7>;

			timing0: timing0 {
				clock-frequency = <0x3197500>;
				hactive = <0x400>;
				vactive = <0x258>;
				hback-porch = <0x6e>;
				hfront-porch = <0x6e>;
				vback-porch = <0x04>;
				vfront-porch = <0x32>;
				hsync-len = <0x5a>;
				vsync-len = <0x04>;
				hsync-active = <0x00>;
				vsync-active = <0x00>;
				de-active = <0x00>;
				pixelclk-active = <0x00>;
				phandle = <0xd7>;
			};
		};

		port {

			panel_in_lvds: endpoint {
				remote-endpoint = <0xd8>;
				phandle = <0x51>;
			};
		};
	};

	sdio_pwrseq: sdio-pwrseq {
		compatible = "mmc-pwrseq-simple";
		clocks = <0xd9 0x01>;
		clock-names = "ext_clock";
		pinctrl-names = "default";
		pinctrl-0 = <0xda>;
		reset-gpios = <0x62 0x02 0x01>;
		phandle = <0xa0>;
	};

	vccsys: vccsys {
		compatible = "regulator-fixed";
		regulator-name = "vcc3v8_sys";
		regulator-always-on;
		regulator-boot-on;
		regulator-min-microvolt = <0x39fbc0>;
		regulator-max-microvolt = <0x39fbc0>;
		phandle = <0x6a>;
	};

	wireless-wlan {
		compatible = "wlan-platdata";
		clocks = <0xd9 0x01>;
		clock-names = "ext_clock";
		wifi_chip_type = [00];
		WIFI,host_wake_irq = <0x62 0x0a 0x00>;
		bl_en_gpio = <0x62 0x00 0x01>;
		fan_on_gpio = <0x62 0x10 0x01>;
		host_for_en = <0x6e 0x11 0x00>;
		status = "okay";
	};

	wireless-bluetooth {
		compatible = "bluetooth-platdata";
		clocks = <0xd9 0x01>;
		clock-names = "ext_clock";
		uart_rts_gpios = <0xdb 0x13 0x01>;
		pinctrl-names = "default", "rts_gpio";
		pinctrl-0 = <0xdc 0xdd>;
		pinctrl-1 = <0xde>;
		BT,reset_gpio = <0x62 0x11 0x00>;
		BT,wake_gpio = <0x62 0x01 0x00>;
		BT,wake_host_irq = <0x62 0x0b 0x00>;
		status = "okay";
	};

	__symbols__ {
		ddr_timing = "/ddr_timing";
		ddr3_params = "/ddr3-params";
		ddr4_params = "/ddr4-params";
		lpddr2_params = "/lpddr2-params";
		lpddr3_params = "/lpddr3-params";
		lpddr4_params = "/lpddr4-params";
		cpu0 = "/cpus/cpu@0";
		cpu1 = "/cpus/cpu@1";
		cpu2 = "/cpus/cpu@2";
		cpu3 = "/cpus/cpu@3";
		CPU_SLEEP = "/cpus/idle-states/cpu-sleep";
		CLUSTER_SLEEP = "/cpus/idle-states/cluster-sleep";
		cpu0_opp_table = "/cpu0-opp-table";
		px30s_cpu0_opp_table = "/px30s-cpu0-opp-table";
		bus_apll = "/bus-apll";
		bus_apll_opp_table = "/bus-apll-opp-table";
		display_subsystem = "/display-subsystem";
		route_lvds = "/display-subsystem/route/route-lvds";
		route_dsi = "/display-subsystem/route/route-dsi";
		route_rgb = "/display-subsystem/route/route-rgb";
		optee = "/firmware/optee";
		scmi = "/firmware/scmi";
		scmi_clk = "/firmware/scmi/protocol@14";
		sdei = "/firmware/sdei";
		firmware_android = "/firmware/android";
		gmac_clkin = "/external-gmac-clock";
		rockchip_suspend = "/rockchip-suspend";
		xin24m = "/xin24m";
		xin32k = "/xin32k";
		scmi_shmem = "/scmi-shmem@10f000";
		pmu = "/power-management@ff000000";
		power = "/power-management@ff000000/power-controller";
		pmugrf = "/syscon@ff010000";
		pmu_io_domains = "/syscon@ff010000/io-domains";
		reboot_mode = "/syscon@ff010000/reboot-mode";
		pmu_pvtm = "/syscon@ff010000/pmu-pvtm";
		uart0 = "/serial@ff030000";
		i2s0_8ch = "/i2s@ff060000";
		i2s1_2ch = "/i2s@ff070000";
		i2s2_2ch = "/i2s@ff080000";
		pdm = "/pdm@ff0a0000";
		crypto = "/crypto@ff0b0000";
		rng = "/rng@ff0b0000";
		gic = "/interrupt-controller@ff131000";
		grf = "/syscon@ff140000";
		io_domains = "/syscon@ff140000/io-domains";
		lvds = "/syscon@ff140000/lvds";
		lvds_in_vopb = "/syscon@ff140000/lvds/ports/port@0/endpoint@0";
		lvds_in_vopl = "/syscon@ff140000/lvds/ports/port@0/endpoint@1";
		lvds_out_panel = "/syscon@ff140000/lvds/ports/port@1/endpoint";
		rgb = "/syscon@ff140000/rgb";
		rgb_in_vopb = "/syscon@ff140000/rgb/ports/port@0/endpoint@0";
		rgb_in_vopl = "/syscon@ff140000/rgb/ports/port@0/endpoint@1";
		core_grf = "/syscon@ff148000";
		pvtm = "/syscon@ff148000/pvtm";
		uart1 = "/serial@ff158000";
		uart2 = "/serial@ff160000";
		uart3 = "/serial@ff168000";
		uart4 = "/serial@ff170000";
		uart5 = "/serial@ff178000";
		i2c0 = "/i2c@ff180000";
		rk817 = "/i2c@ff180000/pmic@20";
		pinctrl_rk8xx = "/i2c@ff180000/pmic@20/pinctrl_rk8xx";
		rk817_ts_gpio1 = "/i2c@ff180000/pmic@20/pinctrl_rk8xx/rk817_ts_gpio1";
		rk817_gt_gpio2 = "/i2c@ff180000/pmic@20/pinctrl_rk8xx/rk817_gt_gpio2";
		rk817_pin_ts = "/i2c@ff180000/pmic@20/pinctrl_rk8xx/rk817_pin_ts";
		rk817_pin_gt = "/i2c@ff180000/pmic@20/pinctrl_rk8xx/rk817_pin_gt";
		rk817_slppin_null = "/i2c@ff180000/pmic@20/pinctrl_rk8xx/rk817_slppin_null";
		rk817_slppin_slp = "/i2c@ff180000/pmic@20/pinctrl_rk8xx/rk817_slppin_slp";
		rk817_slppin_pwrdn = "/i2c@ff180000/pmic@20/pinctrl_rk8xx/rk817_slppin_pwrdn";
		rk817_slppin_rst = "/i2c@ff180000/pmic@20/pinctrl_rk8xx/rk817_slppin_rst";
		vdd_logic = "/i2c@ff180000/pmic@20/regulators/DCDC_REG1";
		vdd_arm = "/i2c@ff180000/pmic@20/regulators/DCDC_REG2";
		vcc_ddr = "/i2c@ff180000/pmic@20/regulators/DCDC_REG3";
		vcc_3v0 = "/i2c@ff180000/pmic@20/regulators/DCDC_REG4";
		vcc_1v0 = "/i2c@ff180000/pmic@20/regulators/LDO_REG1";
		vcc1v8_soc = "/i2c@ff180000/pmic@20/regulators/LDO_REG2";
		vdd1v0_soc = "/i2c@ff180000/pmic@20/regulators/LDO_REG3";
		vcc3v0_pmu = "/i2c@ff180000/pmic@20/regulators/LDO_REG4";
		vccio_sd = "/i2c@ff180000/pmic@20/regulators/LDO_REG5";
		vcc_sd = "/i2c@ff180000/pmic@20/regulators/LDO_REG6";
		vcc2v8_dvp = "/i2c@ff180000/pmic@20/regulators/LDO_REG7";
		vcc1v8_dvp = "/i2c@ff180000/pmic@20/regulators/LDO_REG8";
		vcc_lcd = "/i2c@ff180000/pmic@20/regulators/LDO_REG9";
		dcdc_boost = "/i2c@ff180000/pmic@20/regulators/BOOST";
		otg_switch = "/i2c@ff180000/pmic@20/regulators/OTG_SWITCH";
		rk817_codec = "/i2c@ff180000/pmic@20/codec";
		i2c1 = "/i2c@ff190000";
		rk628_csi_v4l2 = "/i2c@ff190000/rk628_csi_v4l2@50";
		hdmiin_out0 = "/i2c@ff190000/rk628_csi_v4l2@50/port/endpoint";
		i2c2 = "/i2c@ff1a0000";
		i2c3 = "/i2c@ff1b0000";
		spi0 = "/spi@ff1d0000";
		spi1 = "/spi@ff1d8000";
		wdt = "/watchdog@ff1e0000";
		pwm0 = "/pwm@ff200000";
		pwm1 = "/pwm@ff200010";
		pwm2 = "/pwm@ff200020";
		pwm3 = "/pwm@ff200030";
		pwm4 = "/pwm@ff208000";
		pwm5 = "/pwm@ff208010";
		pwm6 = "/pwm@ff208020";
		pwm7 = "/pwm@ff208030";
		rktimer = "/rktimer@ff210000";
		dmac = "/amba/dmac@ff240000";
		thermal_zones = "/thermal-zones";
		soc_thermal = "/thermal-zones/soc-thermal";
		threshold = "/thermal-zones/soc-thermal/trips/trip-point-0";
		target = "/thermal-zones/soc-thermal/trips/trip-point-1";
		soc_crit = "/thermal-zones/soc-thermal/trips/soc-crit";
		gpu_thermal = "/thermal-zones/gpu-thermal";
		tsadc = "/tsadc@ff280000";
		saradc = "/saradc@ff288000";
		otp = "/otp@ff290000";
		otp_id = "/otp@ff290000/id@7";
		cpu_leakage = "/otp@ff290000/cpu-leakage@17";
		performance = "/otp@ff290000/performance@1e";
		cru = "/clock-controller@ff2b0000";
		cpu_boost = "/cpu-boost@ff2b8000";
		pmucru = "/pmu-clock-controller@ff2bc000";
		usb2phy_grf = "/syscon@ff2c0000";
		u2phy = "/syscon@ff2c0000/usb2-phy@100";
		u2phy_host = "/syscon@ff2c0000/usb2-phy@100/host-port";
		u2phy_otg = "/syscon@ff2c0000/usb2-phy@100/otg-port";
		video_phy = "/video-phy@ff2e0000";
		mipi_dphy_rx0 = "/mipi-dphy-rx0@ff2f0000";
		mipi_in = "/mipi-dphy-rx0@ff2f0000/ports/port@0/endpoint@1";
		dphy_rx_out = "/mipi-dphy-rx0@ff2f0000/ports/port@1/endpoint@0";
		usb20_otg = "/usb@ff300000";
		usb_host0_ehci = "/usb@ff340000";
		usb_host0_ohci = "/usb@ff350000";
		gmac = "/ethernet@ff360000";
		sdmmc = "/dwmmc@ff370000";
		sdio = "/dwmmc@ff380000";
		emmc = "/dwmmc@ff390000";
		nandc0 = "/nandc@ff3b0000";
		gpu = "/gpu@ff400000";
		gpu_opp_table = "/gpu-opp-table";
		px30s_gpu_opp_table = "/px30s-gpu-opp-table";
		mpp_srv = "/mpp-srv";
		vdpu = "/vdpu@ff442400";
		vpu_mmu = "/iommu@ff442800";
		vepu = "/vepu@ff442000";
		hevc = "/hevc@ff440000";
		hevc_mmu = "/iommu@ff440440";
		dsi = "/dsi@ff450000";
		dsi_in_vopb = "/dsi@ff450000/ports/port@0/endpoint@0";
		dsi_in_vopl = "/dsi@ff450000/ports/port@0/endpoint@1";
		dsi_out_panel = "/dsi@ff450000/ports/port@1/endpoint";
		panel_in_dsi = "/dsi@ff450000/panel@0/ports/port@0/endpoint";
		vopb = "/vop@ff460000";
		vopb_out = "/vop@ff460000/port";
		vopb_out_lvds = "/vop@ff460000/port/endpoint@0";
		vopb_out_dsi = "/vop@ff460000/port/endpoint@1";
		vopb_out_rgb = "/vop@ff460000/port/endpoint@2";
		vopb_mmu = "/iommu@ff460f00";
		vopl = "/vop@ff470000";
		vopl_out = "/vop@ff470000/port";
		vopl_out_lvds = "/vop@ff470000/port/endpoint@0";
		vopl_out_dsi = "/vop@ff470000/port/endpoint@1";
		vopl_out_rgb = "/vop@ff470000/port/endpoint@2";
		vopl_mmu = "/iommu@ff470f00";
		rk_rga = "/rk_rga@ff480000";
		cif = "/cif@ff490000";
		cif_new = "/cif-new@ff490000";
		vip_mmu = "/iommu@ff490800";
		rk_isp = "/rk_isp@ff4a0000";
		rkisp1 = "/rkisp1@ff4a0000";
		isp_mipi_in = "/rkisp1@ff4a0000/port/endpoint@0";
		isp_mmu = "/iommu@ff4a8000";
		qos_gmac = "/qos@ff518000";
		qos_gpu = "/qos@ff520000";
		qos_sdmmc = "/qos@ff52c000";
		qos_emmc = "/qos@ff538000";
		qos_nand = "/qos@ff538080";
		qos_sdio = "/qos@ff538100";
		qos_sfc = "/qos@ff538180";
		qos_usb_host = "/qos@ff540000";
		qos_usb_otg = "/qos@ff540080";
		qos_isp_128 = "/qos@ff548000";
		qos_isp_rd = "/qos@ff548080";
		qos_isp_wr = "/qos@ff548100";
		qos_isp_m1 = "/qos@ff548180";
		qos_vip = "/qos@ff548200";
		qos_rga_rd = "/qos@ff550000";
		qos_rga_wr = "/qos@ff550080";
		qos_vop_m0 = "/qos@ff550100";
		qos_vop_m1 = "/qos@ff550180";
		qos_vpu = "/qos@ff558000";
		qos_vpu_r128 = "/qos@ff558080";
		dfi = "/dfi@ff610000";
		dmc = "/dmc";
		ddr_power_model = "/dmc/ddr_power_model";
		dmc_fsp = "/dmc-fsp";
		dmc_opp_table = "/dmc-opp-table";
		px30s_dmc_opp_table = "/px30s-dmc-opp-table";
		dmcdbg = "/dmcdbg";
		rockchip_system_monitor = "/rockchip-system-monitor";
		pinctrl = "/pinctrl";
		gpio0 = "/pinctrl/gpio0@ff040000";
		gpio1 = "/pinctrl/gpio1@ff250000";
		gpio2 = "/pinctrl/gpio2@ff260000";
		gpio3 = "/pinctrl/gpio3@ff270000";
		pcfg_pull_up = "/pinctrl/pcfg-pull-up";
		pcfg_pull_down = "/pinctrl/pcfg-pull-down";
		pcfg_pull_none = "/pinctrl/pcfg-pull-none";
		pcfg_pull_none_2ma = "/pinctrl/pcfg-pull-none-2ma";
		pcfg_pull_up_2ma = "/pinctrl/pcfg-pull-up-2ma";
		pcfg_pull_up_4ma = "/pinctrl/pcfg-pull-up-4ma";
		pcfg_pull_none_4ma = "/pinctrl/pcfg-pull-none-4ma";
		pcfg_pull_down_4ma = "/pinctrl/pcfg-pull-down-4ma";
		pcfg_pull_none_8ma = "/pinctrl/pcfg-pull-none-8ma";
		pcfg_pull_up_8ma = "/pinctrl/pcfg-pull-up-8ma";
		pcfg_pull_none_12ma = "/pinctrl/pcfg-pull-none-12ma";
		pcfg_pull_up_12ma = "/pinctrl/pcfg-pull-up-12ma";
		pcfg_pull_none_smt = "/pinctrl/pcfg-pull-none-smt";
		pcfg_output_high = "/pinctrl/pcfg-output-high";
		pcfg_output_low = "/pinctrl/pcfg-output-low";
		pcfg_input_high = "/pinctrl/pcfg-input-high";
		pcfg_input = "/pinctrl/pcfg-input";
		i2c0_xfer = "/pinctrl/i2c0/i2c0-xfer";
		i2c1_xfer = "/pinctrl/i2c1/i2c1-xfer";
		i2c2_xfer = "/pinctrl/i2c2/i2c2-xfer";
		i2c3_xfer = "/pinctrl/i2c3/i2c3-xfer";
		tsadc_otp_gpio = "/pinctrl/tsadc/tsadc-otp-gpio";
		tsadc_otp_out = "/pinctrl/tsadc/tsadc-otp-out";
		uart0_xfer = "/pinctrl/uart0/uart0-xfer";
		uart0_cts = "/pinctrl/uart0/uart0-cts";
		uart0_rts = "/pinctrl/uart0/uart0-rts";
		uart0_rts_gpio = "/pinctrl/uart0/uart0-rts-gpio";
		uart1_xfer = "/pinctrl/uart1/uart1-xfer";
		uart1_cts = "/pinctrl/uart1/uart1-cts";
		uart1_rts = "/pinctrl/uart1/uart1-rts";
		uart1_rts_gpio = "/pinctrl/uart1/uart1-rts-gpio";
		uart2m0_xfer = "/pinctrl/uart2-m0/uart2m0-xfer";
		uart2m1_xfer = "/pinctrl/uart2-m1/uart2m1-xfer";
		uart3m0_xfer = "/pinctrl/uart3-m0/uart3m0-xfer";
		uart3m0_cts = "/pinctrl/uart3-m0/uart3m0-cts";
		uart3m0_rts = "/pinctrl/uart3-m0/uart3m0-rts";
		uart3m0_rts_gpio = "/pinctrl/uart3-m0/uart3m0-rts-gpio";
		uart3m1_xfer = "/pinctrl/uart3-m1/uart3m1-xfer";
		uart3m1_cts = "/pinctrl/uart3-m1/uart3m1-cts";
		uart3m1_rts = "/pinctrl/uart3-m1/uart3m1-rts";
		uart3m1_rts_gpio = "/pinctrl/uart3-m1/uart3m1-rts-gpio";
		uart4_xfer = "/pinctrl/uart4/uart4-xfer";
		uart4_cts = "/pinctrl/uart4/uart4-cts";
		uart4_rts = "/pinctrl/uart4/uart4-rts";
		uart5_xfer = "/pinctrl/uart5/uart5-xfer";
		uart5_cts = "/pinctrl/uart5/uart5-cts";
		uart5_rts = "/pinctrl/uart5/uart5-rts";
		spi0_clk = "/pinctrl/spi0/spi0-clk";
		spi0_csn = "/pinctrl/spi0/spi0-csn";
		spi0_miso = "/pinctrl/spi0/spi0-miso";
		spi0_mosi = "/pinctrl/spi0/spi0-mosi";
		spi0_clk_hs = "/pinctrl/spi0/spi0-clk-hs";
		spi0_miso_hs = "/pinctrl/spi0/spi0-miso-hs";
		spi0_mosi_hs = "/pinctrl/spi0/spi0-mosi-hs";
		spi1_clk = "/pinctrl/spi1/spi1-clk";
		spi1_csn0 = "/pinctrl/spi1/spi1-csn0";
		spi1_csn1 = "/pinctrl/spi1/spi1-csn1";
		spi1_miso = "/pinctrl/spi1/spi1-miso";
		spi1_mosi = "/pinctrl/spi1/spi1-mosi";
		spi1_clk_hs = "/pinctrl/spi1/spi1-clk-hs";
		spi1_miso_hs = "/pinctrl/spi1/spi1-miso-hs";
		spi1_mosi_hs = "/pinctrl/spi1/spi1-mosi-hs";
		pdm_clk0m0 = "/pinctrl/pdm/pdm-clk0m0";
		pdm_clk0m1 = "/pinctrl/pdm/pdm-clk0m1";
		pdm_clk1 = "/pinctrl/pdm/pdm-clk1";
		pdm_sdi0m0 = "/pinctrl/pdm/pdm-sdi0m0";
		pdm_sdi0m1 = "/pinctrl/pdm/pdm-sdi0m1";
		pdm_sdi1 = "/pinctrl/pdm/pdm-sdi1";
		pdm_sdi2 = "/pinctrl/pdm/pdm-sdi2";
		pdm_sdi3 = "/pinctrl/pdm/pdm-sdi3";
		pdm_clk0m0_sleep = "/pinctrl/pdm/pdm-clk0m0-sleep";
		pdm_clk0m_sleep1 = "/pinctrl/pdm/pdm-clk0m1-sleep";
		pdm_clk1_sleep = "/pinctrl/pdm/pdm-clk1-sleep";
		pdm_sdi0m0_sleep = "/pinctrl/pdm/pdm-sdi0m0-sleep";
		pdm_sdi0m1_sleep = "/pinctrl/pdm/pdm-sdi0m1-sleep";
		pdm_sdi1_sleep = "/pinctrl/pdm/pdm-sdi1-sleep";
		pdm_sdi2_sleep = "/pinctrl/pdm/pdm-sdi2-sleep";
		pdm_sdi3_sleep = "/pinctrl/pdm/pdm-sdi3-sleep";
		i2s0_8ch_mclk = "/pinctrl/i2s0/i2s0-8ch-mclk";
		i2s0_8ch_sclktx = "/pinctrl/i2s0/i2s0-8ch-sclktx";
		i2s0_8ch_sclkrx = "/pinctrl/i2s0/i2s0-8ch-sclkrx";
		i2s0_8ch_lrcktx = "/pinctrl/i2s0/i2s0-8ch-lrcktx";
		i2s0_8ch_lrckrx = "/pinctrl/i2s0/i2s0-8ch-lrckrx";
		i2s0_8ch_sdo0 = "/pinctrl/i2s0/i2s0-8ch-sdo0";
		i2s0_8ch_sdo1 = "/pinctrl/i2s0/i2s0-8ch-sdo1";
		i2s0_8ch_sdo2 = "/pinctrl/i2s0/i2s0-8ch-sdo2";
		i2s0_8ch_sdo3 = "/pinctrl/i2s0/i2s0-8ch-sdo3";
		i2s0_8ch_sdi0 = "/pinctrl/i2s0/i2s0-8ch-sdi0";
		i2s0_8ch_sdi1 = "/pinctrl/i2s0/i2s0-8ch-sdi1";
		i2s0_8ch_sdi2 = "/pinctrl/i2s0/i2s0-8ch-sdi2";
		i2s0_8ch_sdi3 = "/pinctrl/i2s0/i2s0-8ch-sdi3";
		i2s1_2ch_mclk = "/pinctrl/i2s1/i2s1-2ch-mclk";
		i2s1_2ch_sclk = "/pinctrl/i2s1/i2s1-2ch-sclk";
		i2s1_2ch_lrck = "/pinctrl/i2s1/i2s1-2ch-lrck";
		i2s1_2ch_sdi = "/pinctrl/i2s1/i2s1-2ch-sdi";
		i2s1_2ch_sdo = "/pinctrl/i2s1/i2s1-2ch-sdo";
		i2s2_2ch_mclk = "/pinctrl/i2s2/i2s2-2ch-mclk";
		i2s2_2ch_sclk = "/pinctrl/i2s2/i2s2-2ch-sclk";
		i2s2_2ch_lrck = "/pinctrl/i2s2/i2s2-2ch-lrck";
		i2s2_2ch_sdi = "/pinctrl/i2s2/i2s2-2ch-sdi";
		i2s2_2ch_sdo = "/pinctrl/i2s2/i2s2-2ch-sdo";
		sdmmc_clk = "/pinctrl/sdmmc/sdmmc-clk";
		sdmmc_cmd = "/pinctrl/sdmmc/sdmmc-cmd";
		sdmmc_det = "/pinctrl/sdmmc/sdmmc-det";
		sdmmc_bus1 = "/pinctrl/sdmmc/sdmmc-bus1";
		sdmmc_bus4 = "/pinctrl/sdmmc/sdmmc-bus4";
		sdmmc_gpio = "/pinctrl/sdmmc/sdmmc-gpio";
		sdio_clk = "/pinctrl/sdio/sdio-clk";
		sdio_cmd = "/pinctrl/sdio/sdio-cmd";
		sdio_bus4 = "/pinctrl/sdio/sdio-bus4";
		sdio_gpio = "/pinctrl/sdio/sdio-gpio";
		emmc_clk = "/pinctrl/emmc/emmc-clk";
		emmc_cmd = "/pinctrl/emmc/emmc-cmd";
		emmc_pwren = "/pinctrl/emmc/emmc-pwren";
		emmc_rstnout = "/pinctrl/emmc/emmc-rstnout";
		emmc_bus1 = "/pinctrl/emmc/emmc-bus1";
		emmc_bus4 = "/pinctrl/emmc/emmc-bus4";
		emmc_bus8 = "/pinctrl/emmc/emmc-bus8";
		flash_cs0 = "/pinctrl/flash/flash-cs0";
		flash_rdy = "/pinctrl/flash/flash-rdy";
		flash_dqs = "/pinctrl/flash/flash-dqs";
		flash_ale = "/pinctrl/flash/flash-ale";
		flash_cle = "/pinctrl/flash/flash-cle";
		flash_wrn = "/pinctrl/flash/flash-wrn";
		flash_csl = "/pinctrl/flash/flash-csl";
		flash_rdn = "/pinctrl/flash/flash-rdn";
		flash_bus8 = "/pinctrl/flash/flash-bus8";
		lcdc_m0_rgb_pins = "/pinctrl/lcdc/lcdc-m0-rgb-pins";
		lcdc_m0_sleep_pins = "/pinctrl/lcdc/lcdc-m0-sleep-pins";
		lcdc_m1_rgb_pins = "/pinctrl/lcdc/lcdc-m1-rgb-pins";
		lcdc_m1_sleep_pins = "/pinctrl/lcdc/lcdc-m1-sleep-pins";
		pwm0_pin = "/pinctrl/pwm0/pwm0-pin";
		pwm1_pin = "/pinctrl/pwm1/pwm1-pin";
		pwm2_pin = "/pinctrl/pwm2/pwm2-pin";
		pwm3_pin = "/pinctrl/pwm3/pwm3-pin";
		pwm4_pin = "/pinctrl/pwm4/pwm4-pin";
		pwm5_pin = "/pinctrl/pwm5/pwm5-pin";
		pwm6_pin = "/pinctrl/pwm6/pwm6-pin";
		pwm7_pin = "/pinctrl/pwm7/pwm7-pin";
		rmii_pins = "/pinctrl/gmac/rmii-pins";
		mac_refclk_12ma = "/pinctrl/gmac/mac-refclk-12ma";
		mac_refclk = "/pinctrl/gmac/mac-refclk";
		cif_clkout_m0 = "/pinctrl/cif-m0/cif-clkout-m0";
		dvp_d2d9_m0 = "/pinctrl/cif-m0/dvp-d2d9-m0";
		dvp_d0d1_m0 = "/pinctrl/cif-m0/dvp-d0d1-m0";
		dvp_d10d11_m0 = "/pinctrl/cif-m0/d10-d11-m0";
		cif_clkout_m1 = "/pinctrl/cif-m1/cif-clkout-m1";
		dvp_d2d9_m1 = "/pinctrl/cif-m1/dvp-d2d9-m1";
		dvp_d0d1_m1 = "/pinctrl/cif-m1/dvp-d0d1-m1";
		dvp_d10d11_m1 = "/pinctrl/cif-m1/d10-d11-m1";
		isp_prelight = "/pinctrl/isp/isp-prelight";
		hp_det = "/pinctrl/headphone/hp-det";
		wake_host_irq = "/pinctrl/bt_wake_host/wake_host_irq";
		pmic_int = "/pinctrl/pmic/pmic_int";
		soc_slppin_gpio = "/pinctrl/pmic/soc_slppin_gpio";
		soc_slppin_slp = "/pinctrl/pmic/soc_slppin_slp";
		soc_slppin_rst = "/pinctrl/pmic/soc_slppin_rst";
		wifi_enable_h = "/pinctrl/sdio-pwrseq/wifi-enable-h";
		spi_init_cmd = "/pinctrl/spi_panel/spi-init-cmd";
		pcfg_pull_none_n_4ma = "/pcfg-for-s/pcfg-pull-none-n-4ma";
		pcfg_pull_up_n_4ma = "/pcfg-for-s/pcfg-pull-up-n-4ma";
		pcfg_pull_down_n_4ma = "/pcfg-for-s/pcfg-pull-down-n-4ma";
		pcfg_pull_none_0_6ma = "/pcfg-for-s/pcfg-pull-none-0-6ma";
		pcfg_pull_up_0_6ma = "/pcfg-for-s/pcfg-pull-up-0-6ma";
		pcfg_pull_down_0_6ma = "/pcfg-for-s/pcfg-pull-down-0-6ma";
		pcfg_pull_none_4_6ma = "/pcfg-for-s/pcfg-pull-none-4-6ma";
		pcfg_pull_up_4_6ma = "/pcfg-for-s/pcfg-pull-up-4-6ma";
		pcfg_pull_down_4_6ma = "/pcfg-for-s/pcfg-pull-down-4-6ma";
		pcfg_pull_none_8_6ma = "/pcfg-for-s/pcfg-pull-none-8-6ma";
		pcfg_pull_up_8_6ma = "/pcfg-for-s/pcfg-pull-up-8-6ma";
		pcfg_pull_down_8_6ma = "/pcfg-for-s/pcfg-pull-down-8-6ma";
		pcfg_pull_none_8_4ma = "/pcfg-for-s/pcfg-pull-none-8-4ma";
		pcfg_pull_up_8_4ma = "/pcfg-for-s/pcfg-pull-up-8-4ma";
		pcfg_pull_down_8_4ma = "/pcfg-for-s/pcfg-pull-down-8-4ma";
		pcfg_pull_none_12_4ma = "/pcfg-for-s/pcfg-pull-none-12-4ma";
		pcfg_pull_up_12_4ma = "/pcfg-for-s/pcfg-pull-up-12-4ma";
		pcfg_pull_down_12_4ma = "/pcfg-for-s/pcfg-pull-down-12-4ma";
		pcfg_pull_none_12_6ma = "/pcfg-for-s/pcfg-pull-none-12-6ma";
		pcfg_pull_up_12_6ma = "/pcfg-for-s/pcfg-pull-up-12-6ma";
		pcfg_pull_down_12_6ma = "/pcfg-for-s/pcfg-pull-down-12-6ma";
		cif_sensor = "/cif_sensor";
		chosen = "/chosen";
		drm_logo = "/reserved-memory/drm-logo@00000000";
		ramoops = "/reserved-memory/ramoops@110000";
		key = "/key";
		dummy_codec = "/dummy-codec";
		dailink0_master = "/hdmiin-sound/simple-audio-card,codec";
		rk_headset = "/rk-headset";
		panel = "/panel";
		timing0 = "/panel/display-timings/timing0";
		panel_in_lvds = "/panel/port/endpoint";
		sdio_pwrseq = "/sdio-pwrseq";
		vccsys = "/vccsys";
	};
};
